VERSION ""

NS_ :

BS_:

BU_: CLOCK HUD H_U DATC CCP KMA_TMU CUBIS TMU IPM RSE_R RRC CGW RSE_L AMP EDT SWRC IBOX CLU FHCU ASD MON AVM KBD

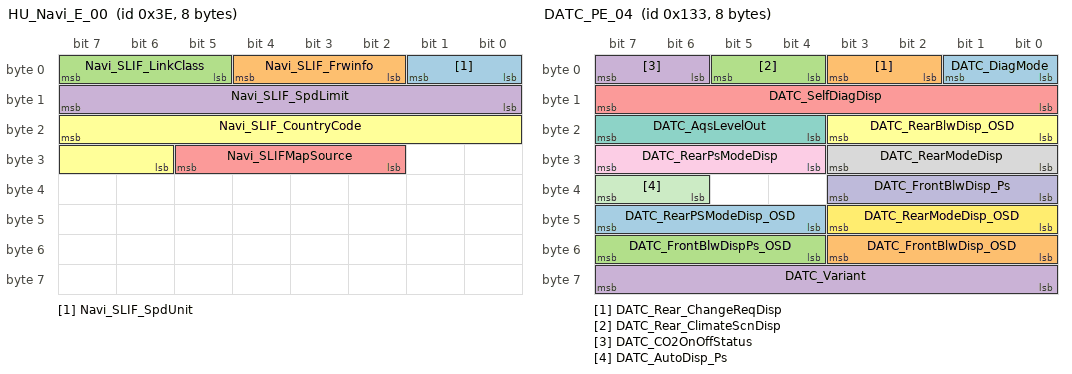
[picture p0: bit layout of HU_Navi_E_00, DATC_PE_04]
BO_ 62 HU_Navi_E_00: 8 H_U
 SG_ Navi_SLIF_SpdUnit : 1|2@0+ (1,0) [0|0] ""  CGW,CLU,HUD
 SG_ Navi_SLIF_Frwinfo : 4|3@0+ (1,0) [0|0] ""  CGW,CLU,HUD
 SG_ Navi_SLIF_LinkClass : 7|3@0+ (1,0) [0|0] ""  CGW,CLU,HUD
 SG_ Navi_SLIF_SpdLimit : 15|8@0+ (1,0) [1|254] ""  CGW,CLU,HUD
 SG_ Navi_SLIFMapSource : 29|4@0+ (1,0) [0|8] ""  CGW,CLU,HUD
 SG_ Navi_SLIF_CountryCode : 23|10@0+ (1,0) [0|0] ""  CGW,CLU,HUD

BO_ 52 HU_DATC_E_02: 8 H_U
 SG_ HU_DATC_DrTempUpDn : 1|2@0+ (1,0) [0|0] ""  CGW,CLU,DATC,IPM
 SG_ HU_DATC_PsTempUpDn : 3|2@0+ (1,0) [0|0] ""  CGW,CLU,DATC,IPM
 SG_ HU_DATC_RlTempUpDn : 5|2@0+ (1,0) [0|0] ""  CGW,CLU,DATC,IPM
 SG_ HU_DATC_RrTempUpDn : 7|2@0+ (1,0) [0|0] ""  CGW,CLU,DATC,IPM
 SG_ HU_DATC_MainBlower : 11|4@0+ (1,0) [0|0] ""  CGW,CLU,DATC,IPM
 SG_ HU_DATC_SubBlower : 15|4@0+ (1,0) [0|0] ""  CGW,CLU,DATC,IPM
 SG_ HU_DATC_RearBlower : 19|4@0+ (1,0) [0|0] ""  CGW,CLU,DATC,IPM
 SG_ HU_DATCRearPsModeSet : 23|4@0+ (1,0) [0|0] ""  CGW,CLU
 SG_ HU_DATC_FrontModeSet : 27|4@0+ (1,0) [0|0] ""  CGW,CLU,DATC,IPM
 SG_ HU_DATC_RearModeSet : 31|4@0+ (1,0) [0|0] ""  CGW,CLU,DATC,IPM
 SG_ HU_DATC_AutoSet : 33|2@0+ (1,0) [0|0] ""  CGW,CLU,DATC,IPM
 SG_ HU_DATC_OffReq : 35|2@0+ (1,0) [0|0] ""  CGW,CLU,DATC,IPM
 SG_ HU_DATC_IntakeSet : 37|2@0+ (1,0) [0|0] ""  CGW,CLU,DATC,IPM
 SG_ HU_DATC_RearOnOffSet : 39|2@0+ (1,0) [0|0] ""  CGW,CLU,DATC,IPM
 SG_ HU_DATC_AcSet : 41|2@0+ (1,0) [0|0] ""  CGW,CLU,DATC,IPM
 SG_ HU_DATC_AqsSet : 43|2@0+ (1,0) [0|0] ""  CGW,CLU,DATC,IPM
 SG_ HU_DATC_FrontDefog : 45|2@0+ (1,0) [0|0] ""  CGW,CLU,DATC,IPM
 SG_ HU_DATC_RearDefog : 47|2@0+ (1,0) [0|0] ""  CGW,CLU,DATC,IPM
 SG_ HU_DATC_ZoneControl : 49|2@0+ (1,0) [0|0] ""  CGW,CLU,DATC,IPM
 SG_ HU_DATC_CO2Set : 51|2@0+ (1,0) [0|0] ""  CGW,CLU,DATC,IPM
 SG_ DATC_SmartVentOnOffSet : 53|2@0+ (1,0) [0|0] ""  CGW,CLU,DATC,IPM
 SG_ DATC_ADSOnOffSet : 55|2@0+ (1,0) [0|0] ""  CGW,CLU
 SG_ HU_DATC_RearAutoDisp : 57|2@0+ (1,0) [0|0] ""  CGW,CLU
 SG_ HU_DATC_RearOffDisp : 59|2@0+ (1,0) [0|0] ""  CGW,CLU

BO_ 308 DATC_PE_05: 8 CLU
 SG_ DATC_PwrInfo : 3|4@0+ (1,0) [0|0] ""  AMP,AVM,CUBIS,H_U,MON
 SG_ DATC_AltL : 5|2@0+ (1,0) [0|0] ""  H_U,MON
 SG_ DATC_CarInfo : 7|2@0+ (1,0) [0|0] ""  H_U
 SG_ DATC_ParkingBrake : 9|2@0+ (1,0) [0|0] ""  H_U
 SG_ DATC_LowFuelWarn : 11|2@0+ (1,0) [0|0] ""  H_U
 SG_ DATC_Rear_Off_Disp : 13|2@0+ (1,0) [0|0] ""  H_U,MON
 SG_ DATC_Rear_AutoDisp : 15|2@0+ (1,0) [0|0] ""  H_U,MON
 SG_ DATC_Rear_BlowerDisp : 19|4@0+ (1,0) [0|0] ""  H_U,MON
 SG_ DATC_DrSeatWarmerDisp : 22|3@0+ (1,0) [0|0] ""  H_U,MON
 SG_ DATC_SyncDisp : 27|4@0+ (1,0) [0|0] ""  H_U,MON
 SG_ DATC_RearDispCtrl : 31|4@0+ (1,0) [0|0] ""  H_U,MON
 SG_ DATC_RearDrModeDisp : 35|4@0+ (1,0) [0|0] ""  H_U
 SG_ DATC_PsSeatWarmerDisp : 38|3@0+ (1,0) [0|0] ""  H_U,MON
 SG_ DATC_DrVentSeatDisp : 42|3@0+ (1,0) [0|0] ""  H_U,MON
 SG_ DATC_PSVentSeatDisp : 46|3@0+ (1,0) [0|0] ""  H_U,MON
 SG_ DATC_RrDefLed : 49|2@0+ (1,0) [0|0] ""  H_U,MON
 SG_ DATC_SmartVentOnOffStatus : 51|2@0+ (1,0) [0|0] ""  H_U
 SG_ DATC_ADSOnOffStatus : 53|2@0+ (1,0) [0|0] ""  H_U
 SG_ DATC_AcDisp_OSD : 55|2@0+ (1,0) [0|0] ""  H_U
 SG_ DATC_PsModeDisp_OSD : 59|4@0+ (1,0) [0|0] ""  H_U
 SG_ DATC_ModeDisp_OSD : 63|4@0+ (1,0) [0|0] ""  H_U

BO_ 307 DATC_PE_04: 8 CLU
 SG_ DATC_DiagMode : 1|2@0+ (1,0) [0|0] ""  H_U,IBOX,MON
 SG_ DATC_Rear_ChangeReqDisp : 3|2@0+ (1,0) [0|0] ""  H_U,IBOX,MON
 SG_ DATC_Rear_ClimateScnDisp : 5|2@0+ (1,0) [0|0] ""  H_U,IBOX,MON
 SG_ DATC_CO2OnOffStatus : 7|2@0+ (1,0) [0|0] ""  H_U
 SG_ DATC_SelfDiagDisp : 15|8@0+ (1,0) [0|0] ""  H_U,IBOX,MON
 SG_ DATC_RearBlwDisp_OSD : 19|4@0+ (1,0) [0|0] ""  H_U
 SG_ DATC_AqsLevelOut : 23|4@0+ (1,0) [0|0] ""  H_U,IBOX,MON
 SG_ DATC_RearModeDisp : 27|4@0+ (1,0) [0|0] ""  H_U
 SG_ DATC_RearPsModeDisp : 31|4@0+ (1,0) [0|0] ""  H_U
 SG_ DATC_FrontBlwDisp_Ps : 35|4@0+ (1,0) [0|0] ""  H_U
 SG_ DATC_AutoDisp_Ps : 39|2@0+ (1,0) [0|0] ""  H_U
 SG_ DATC_RearModeDisp_OSD : 43|4@0+ (1,0) [0|0] ""  H_U
 SG_ DATC_RearPSModeDisp_OSD : 47|4@0+ (1,0) [0|0] ""  H_U
 SG_ DATC_FrontBlwDisp_OSD : 51|4@0+ (1,0) [0|0] ""  H_U
 SG_ DATC_FrontBlwDispPs_OSD : 55|4@0+ (1,0) [0|0] ""  H_U
 SG_ DATC_Variant : 63|8@0+ (1,0) [0|0] ""  H_U,IBOX,MON

BO_ 306 DATC_PE_03: 8 CLU
 SG_ DATC_ModeDisp : 3|4@0+ (1,0) [0|0] ""  H_U,IBOX
 SG_ DATC_TempUnit : 5|2@0+ (1,0) [0|0] ""  H_U,IBOX
 SG_ DATC_AutoDisp : 9|2@0+ (1,0) [0|0] ""  H_U,IBOX
 SG_ DATC_IntakeDisp : 11|2@0+ (1,0) [0|0] ""  H_U,IBOX
 SG_ DATC_ChangeReqDisp : 13|2@0+ (1,0) [0|0] ""  H_U,IBOX
 SG_ DATC_AcDisp : 17|2@0+ (1,0) [0|0] ""  H_U,IBOX
 SG_ DATC_AqsDisp : 19|2@0+ (1,0) [0|0] ""  H_U,IBOX
 SG_ DATC_ClimateScnDisp : 21|2@0+ (1,0) [0|0] ""  H_U,IBOX
 SG_ DATC_DualDisp : 25|2@0+ (1,0) [0|0] ""  H_U,IBOX
 SG_ DATC_OffDisp : 27|2@0+ (1,0) [0|0] ""  H_U,IBOX
 SG_ DATC_OpSts : 30|3@0+ (1,0) [0|0] ""  H_U,IBOX
 SG_ DATC_RearManual : 33|2@0+ (1,0) [0|0] ""  H_U,MON
 SG_ DATC_FrDefLed : 37|2@0+ (1,0) [0|0] ""  H_U
 SG_ DATC_SmartVentDisp : 39|2@0+ (1,0) [0|0] ""  H_U
 SG_ DATC_AutoDefogBlink : 41|2@0+ (1,0) [0|0] ""  H_U,IBOX
 SG_ DATC_ADSDisp : 43|2@0+ (1,0) [0|0] ""  H_U
 SG_ DATC_IonClean : 45|2@0+ (1,0) [0|0] ""  H_U,IBOX
 SG_ DATC_CO2Warning : 47|2@0+ (1,0) [0|0] ""  H_U,IBOX
 SG_ DATC_SubBlowerDisp : 51|4@0+ (1,0) [0|0] ""  H_U,MON
 SG_ DATC_BeepReq : 55|4@0+ (1,0) [0|0] ""  H_U,KBD,MON
 SG_ DATC_MainBlowerDisp : 59|4@0+ (1,0) [0|0] ""  H_U,IBOX
 SG_ DATC_PsModeDisp : 63|4@0+ (1,0) [0|0] ""  H_U,IBOX

BO_ 1329 DATC_P_02: 8 CLU
 SG_ DATC_AmbientTemp_C : 7|8@0+ (1,0) [0|0] ""  H_U,MON
 SG_ DATC_AmbientTemp_F : 23|8@0+ (1,0) [0|0] ""  H_U,MON

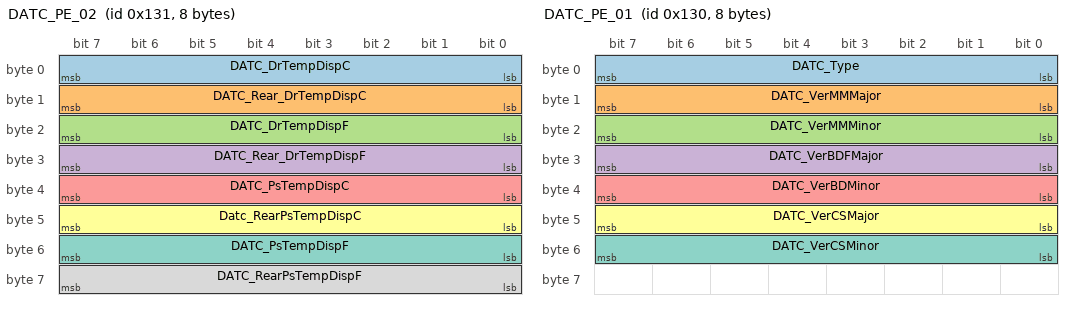
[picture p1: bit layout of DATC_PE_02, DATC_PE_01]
BO_ 305 DATC_PE_02: 8 CLU
 SG_ DATC_DrTempDispC : 7|8@0+ (0.5,14) [15|32] "C"  H_U,IBOX,MON
 SG_ DATC_Rear_DrTempDispC : 15|8@0+ (0.5,14) [15|32] "C"  H_U,IBOX,MON
 SG_ DATC_DrTempDispF : 23|8@0+ (1,56) [58|90] "F"  H_U,IBOX,MON
 SG_ DATC_Rear_DrTempDispF : 31|8@0+ (1,56) [58|90] "F"  H_U,IBOX,MON
 SG_ DATC_PsTempDispC : 39|8@0+ (0.5,14) [15|32] "C"  H_U,IBOX,MON
 SG_ Datc_RearPsTempDispC : 47|8@0+ (0.5,14) [15|32] "C"  H_U,IBOX,MON
 SG_ DATC_PsTempDispF : 55|8@0+ (1,56) [58|90] "F"  H_U,IBOX,MON
 SG_ DATC_RearPsTempDispF : 63|8@0+ (1,56) [58|90] "F"  H_U,IBOX,MON

BO_ 304 DATC_PE_01: 8 CLU
 SG_ DATC_Type : 7|8@0+ (1,0) [0|0] ""  H_U,MON
 SG_ DATC_VerMMMajor : 15|8@0+ (1,0) [0|0] ""  H_U,MON
 SG_ DATC_VerMMMinor : 23|8@0+ (1,0) [0|0] ""  H_U,MON
 SG_ DATC_VerBDFMajor : 31|8@0+ (1,0) [0|0] ""  H_U,MON
 SG_ DATC_VerBDMinor : 39|8@0+ (1,0) [0|0] ""  H_U,MON
 SG_ DATC_VerCSMajor : 47|8@0+ (1,0) [0|0] ""  H_U,MON
 SG_ DATC_VerCSMinor : 55|8@0+ (1,0) [0|0] ""  H_U,MON

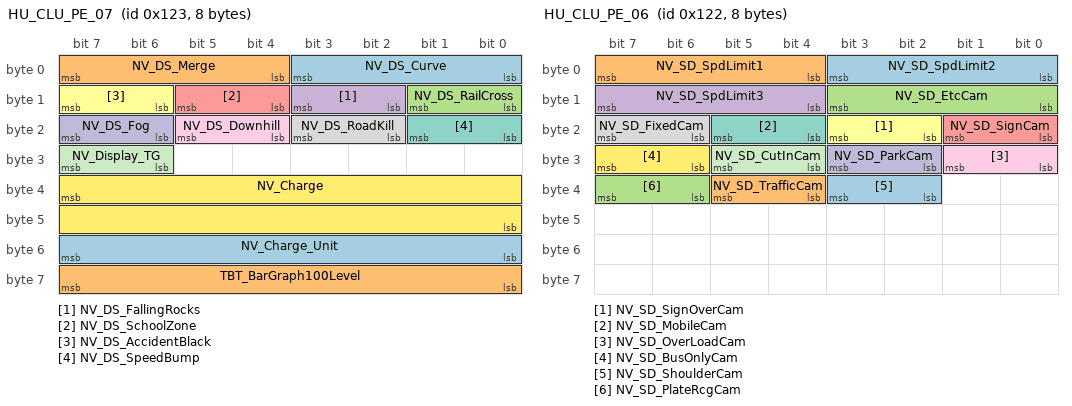
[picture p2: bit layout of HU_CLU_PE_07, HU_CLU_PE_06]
BO_ 291 HU_CLU_PE_07: 8 H_U
 SG_ NV_DS_Curve : 3|4@0+ (1,0) [0|0] ""  CLU
 SG_ NV_DS_Merge : 7|4@0+ (1,0) [0|0] ""  CLU
 SG_ NV_DS_RailCross : 9|2@0+ (1,0) [0|0] ""  CLU
 SG_ NV_DS_FallingRocks : 11|2@0+ (1,0) [0|0] ""  CLU
 SG_ NV_DS_SchoolZone : 13|2@0+ (1,0) [0|0] ""  CLU
 SG_ NV_DS_AccidentBlack : 15|2@0+ (1,0) [0|0] ""  CLU
 SG_ NV_DS_SpeedBump : 17|2@0+ (1,0) [0|0] ""  CLU
 SG_ NV_DS_RoadKill : 19|2@0+ (1,0) [0|0] ""  CLU
 SG_ NV_DS_Downhill : 21|2@0+ (1,0) [0|0] ""  CLU
 SG_ NV_DS_Fog : 23|2@0+ (1,0) [0|0] ""  CLU
 SG_ NV_Display_TG : 31|2@0+ (1,0) [0|0] ""  CLU,HUD
 SG_ NV_Charge : 39|16@0+ (1,0) [0|0] ""  CLU,HUD
 SG_ NV_Charge_Unit : 55|8@0+ (1,0) [0|0] ""  CLU,HUD
 SG_ TBT_BarGraph100Level : 63|8@0+ (1,0) [0|100] "%"  CLU,HUD

BO_ 290 HU_CLU_PE_06: 8 H_U
 SG_ NV_SD_SpdLimit2 : 3|4@0+ (10,0) [0|0] "km/h"  CLU
 SG_ NV_SD_SpdLimit1 : 7|4@0+ (10,0) [0|0] "km/h"  CLU
 SG_ NV_SD_EtcCam : 11|4@0+ (1,0) [0|0] ""  CLU
 SG_ NV_SD_SpdLimit3 : 15|4@0+ (10,0) [0|0] "km/h"  CLU
 SG_ NV_SD_SignCam : 17|2@0+ (1,0) [0|0] ""  CLU
 SG_ NV_SD_SignOverCam : 19|2@0+ (1,0) [0|0] ""  CLU
 SG_ NV_SD_MobileCam : 21|2@0+ (1,0) [0|0] ""  CLU
 SG_ NV_SD_FixedCam : 23|2@0+ (1,0) [0|0] ""  CLU
 SG_ NV_SD_OverLoadCam : 25|2@0+ (1,0) [0|0] ""  CLU
 SG_ NV_SD_ParkCam : 27|2@0+ (1,0) [0|0] ""  CLU
 SG_ NV_SD_CutInCam : 29|2@0+ (1,0) [0|0] ""  CLU
 SG_ NV_SD_BusOnlyCam : 31|2@0+ (1,0) [0|0] ""  CLU
 SG_ NV_SD_ShoulderCam : 35|2@0+ (1,0) [0|0] ""  CLU
 SG_ NV_SD_TrafficCam : 37|2@0+ (1,0) [0|0] ""  CLU
 SG_ NV_SD_PlateRcgCam : 39|2@0+ (1,0) [0|0] ""  CLU

BO_ 286 HU_CLU_PE_10: 8 H_U
 SG_ Navi_TBTInfo : 63|8@0+ (1,0) [0|0] ""  CGW,CLU

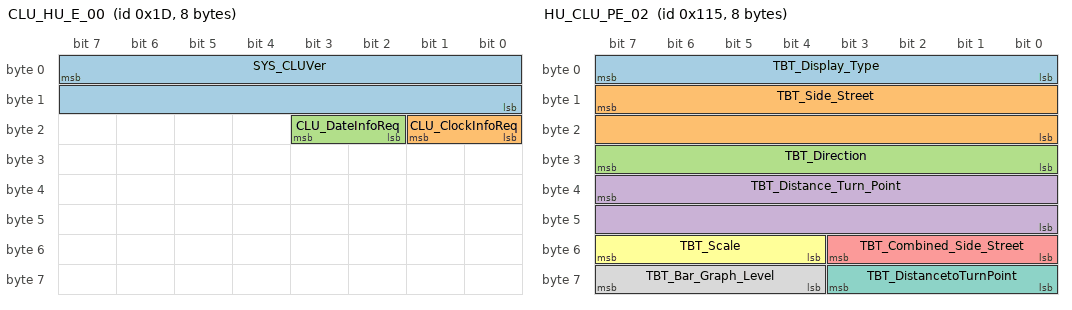
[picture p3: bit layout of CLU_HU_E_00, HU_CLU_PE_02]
BO_ 29 CLU_HU_E_00: 8 CLU
 SG_ SYS_CLUVer : 7|16@0+ (1,0) [0|0] ""  CUBIS,H_U
 SG_ CLU_ClockInfoReq : 17|2@0+ (1,0) [0|0] ""  H_U
 SG_ CLU_DateInfoReq : 19|2@0+ (1,0) [0|0] ""  H_U

BO_ 27 AMP_HU_E_00: 8 AMP
 SG_ SYS_AMPVer : 7|16@0+ (1,0) [0|0] ""  H_U

BO_ 23 HU_IPM_E_00: 8 H_U
 SG_ C_ADrLNValueSet : 2|3@0+ (1,0) [0|0] ""  DATC,IPM
 SG_ C_ADrUNValueSet : 5|3@0+ (1,0) [0|0] ""  DATC,IPM
 SG_ SYS_Ver_Req : 7|2@0+ (1,0) [0|0] ""  AMP,AVM,CLU,CUBIS,DATC,IPM
 SG_ C_IMSRValueReq : 9|2@0+ (1,0) [0|0] ""  DATC,IPM
 SG_ C_PSMNValueSet : 11|2@0+ (1,0) [0|0] ""  DATC,IPM
 SG_ C_SCMNValueSet : 13|2@0+ (1,0) [0|0] ""  DATC,IPM
 SG_ C_ADrLURValueReq : 15|2@0+ (1,0) [0|0] ""  DATC,IPM
 SG_ C_ABuzzerNValueSet : 17|2@0+ (1,0) [0|0] ""  DATC,IPM
 SG_ C_AlarmRValueReq : 19|2@0+ (1,0) [0|0] ""  DATC,IPM
 SG_ C_ArmWKeyNValueSet : 21|2@0+ (1,0) [0|0] ""  DATC,IPM
 SG_ C_TwUnRValueReq : 23|2@0+ (1,0) [0|0] ""  DATC,IPM
 SG_ C_TwUnNValueSet : 25|2@0+ (1,0) [0|0] ""  DATC,IPM
 SG_ C_AutoMRFoldRValueReq : 27|2@0+ (1,0) [0|0] ""  DATC,IPM
 SG_ C_AutoMRFoldNValueSet : 29|2@0+ (1,0) [0|0] ""  DATC,IPM
 SG_ C_ADrLRValueReq : 31|2@0+ (1,0) [0|0] ""  DATC,IPM
 SG_ C_ArmWKeyRValueReq : 33|2@0+ (1,0) [0|0] ""  DATC,IPM
 SG_ C_ABuzzerRValueReq : 35|2@0+ (1,0) [0|0] ""  DATC,IPM
 SG_ C_ADrURValueReq : 37|2@0+ (1,0) [0|0] ""  DATC,IPM
 SG_ C_PSMRValueReq : 39|2@0+ (1,0) [0|0] ""  DATC,IPM
 SG_ C_SCMRValueReq : 47|2@0+ (1,0) [0|0] ""  DATC,IPM

BO_ 277 HU_CLU_PE_02: 8 H_U
 SG_ TBT_Display_Type : 7|8@0+ (1,0) [0|0] ""  CLU,HUD
 SG_ TBT_Side_Street : 15|16@0+ (1,0) [0|0] ""  CLU,HUD
 SG_ TBT_Direction : 31|8@0+ (1,0) [0|0] ""  CLU,HUD
 SG_ TBT_Distance_Turn_Point : 39|16@0+ (1,0) [0|0] "m"  CLU,HUD
 SG_ TBT_Combined_Side_Street : 51|4@0+ (1,0) [0|0] ""  CLU,HUD
 SG_ TBT_Scale : 55|4@0+ (1,0) [0|0] ""  CLU,HUD
 SG_ TBT_DistancetoTurnPoint : 59|4@0+ (1,0) [0|0] "times"  CLU,HUD
 SG_ TBT_Bar_Graph_Level : 63|4@0+ (10,0) [0|100] ""  CLU,HUD

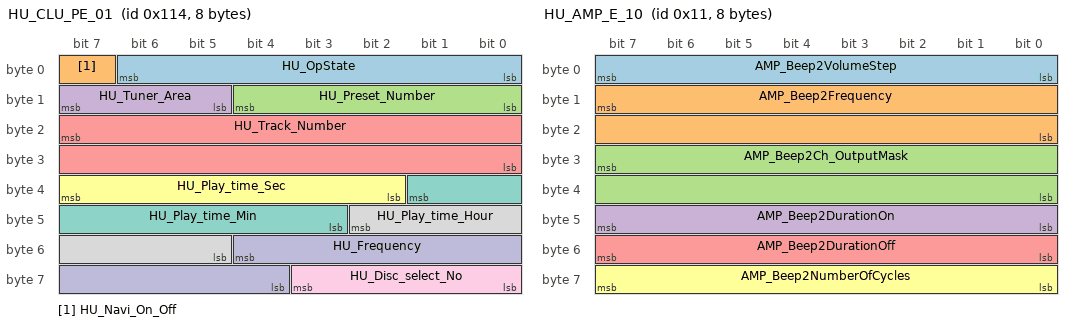
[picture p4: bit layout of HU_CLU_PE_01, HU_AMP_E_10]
BO_ 276 HU_CLU_PE_01: 8 H_U
 SG_ HU_OpState : 6|7@0+ (1,0) [0|0] ""  AMP,CLU
 SG_ HU_Navi_On_Off : 7|1@0+ (1,0) [0|0] ""  CLU,HUD
 SG_ HU_Preset_Number : 12|5@0+ (1,1) [1|30] ""  AMP,CLU
 SG_ HU_Tuner_Area : 15|3@0+ (1,0) [0|0] ""  AMP,CLU
 SG_ HU_Track_Number : 23|16@0+ (1,0) [0|0] ""  CLU
 SG_ HU_Play_time_Sec : 39|6@0+ (1,0) [0|0] ""  CLU
 SG_ HU_Play_time_Min : 33|7@0+ (1,0) [0|0] ""  CLU
 SG_ HU_Play_time_Hour : 42|6@0+ (1,0) [0|0] ""  CLU
 SG_ HU_Disc_select_No : 59|4@0+ (1,0) [0|0] ""  CLU
 SG_ HU_Frequency : 52|9@0+ (1,0) [0|0] ""  AMP,CLU

BO_ 17 HU_AMP_E_10: 8 H_U
 SG_ AMP_Beep2VolumeStep : 7|8@0+ (1,0) [0|0] ""  AMP
 SG_ AMP_Beep2Frequency : 15|16@0+ (1,0) [0|0] ""  AMP
 SG_ AMP_Beep2Ch_OutputMask : 31|16@0+ (1,0) [0|0] ""  AMP
 SG_ AMP_Beep2DurationOn : 47|8@0+ (1,0) [0|0] ""  AMP
 SG_ AMP_Beep2DurationOff : 55|8@0+ (1,0) [0|0] ""  AMP
 SG_ AMP_Beep2NumberOfCycles : 63|8@0+ (1,0) [0|0] ""  AMP

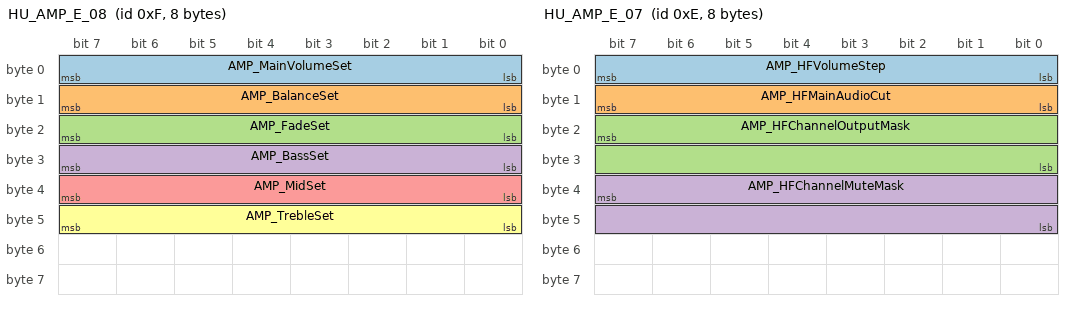
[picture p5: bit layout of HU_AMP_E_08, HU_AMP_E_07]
BO_ 15 HU_AMP_E_08: 8 H_U
 SG_ AMP_MainVolumeSet : 7|8@0+ (1,0) [0|0] ""  AMP
 SG_ AMP_BalanceSet : 15|8@0+ (1,0) [0|0] ""  AMP
 SG_ AMP_FadeSet : 23|8@0+ (1,0) [0|0] ""  AMP
 SG_ AMP_BassSet : 31|8@0+ (1,0) [0|0] ""  AMP
 SG_ AMP_MidSet : 39|8@0+ (1,0) [0|0] ""  AMP
 SG_ AMP_TrebleSet : 47|8@0+ (1,0) [0|0] ""  AMP

BO_ 14 HU_AMP_E_07: 8 H_U
 SG_ AMP_HFVolumeStep : 7|8@0+ (1,0) [0|0] ""  AMP
 SG_ AMP_HFMainAudioCut : 15|8@0+ (1,0) [0|0] ""  AMP
 SG_ AMP_HFChannelOutputMask : 23|16@0+ (1,0) [0|0] ""  AMP
 SG_ AMP_HFChannelMuteMask : 39|16@0+ (1,0) [0|0] ""  AMP

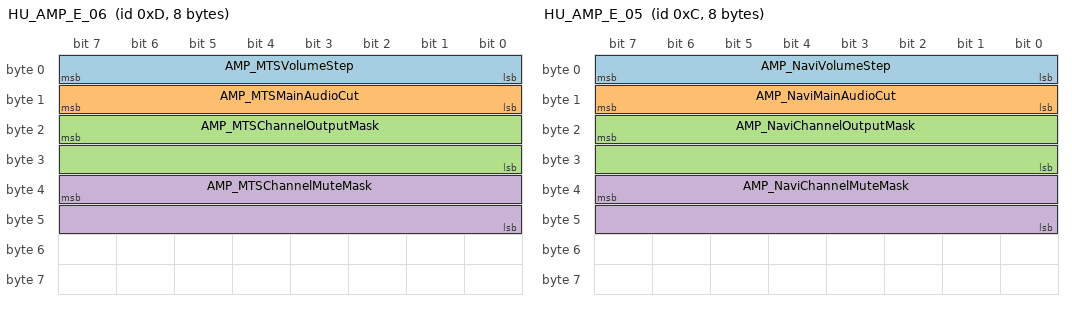
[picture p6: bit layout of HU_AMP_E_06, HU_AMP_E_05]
BO_ 13 HU_AMP_E_06: 8 H_U
 SG_ AMP_MTSVolumeStep : 7|8@0+ (1,0) [0|0] ""  AMP
 SG_ AMP_MTSMainAudioCut : 15|8@0+ (1,0) [0|0] ""  AMP
 SG_ AMP_MTSChannelOutputMask : 23|16@0+ (1,0) [0|0] ""  AMP
 SG_ AMP_MTSChannelMuteMask : 39|16@0+ (1,0) [0|0] ""  AMP

BO_ 12 HU_AMP_E_05: 8 H_U
 SG_ AMP_NaviVolumeStep : 7|8@0+ (1,0) [0|0] ""  AMP
 SG_ AMP_NaviMainAudioCut : 15|8@0+ (1,0) [0|0] ""  AMP
 SG_ AMP_NaviChannelOutputMask : 23|16@0+ (1,0) [0|0] ""  AMP
 SG_ AMP_NaviChannelMuteMask : 39|16@0+ (1,0) [0|0] ""  AMP

BO_ 11 HU_AMP_E_04: 8 H_U
 SG_ AMP_Drive : 1|2@0+ (1,0) [0|0] ""  AMP
 SG_ AMP_ConvertibleTop : 5|2@0+ (1,0) [0|0] ""  AMP

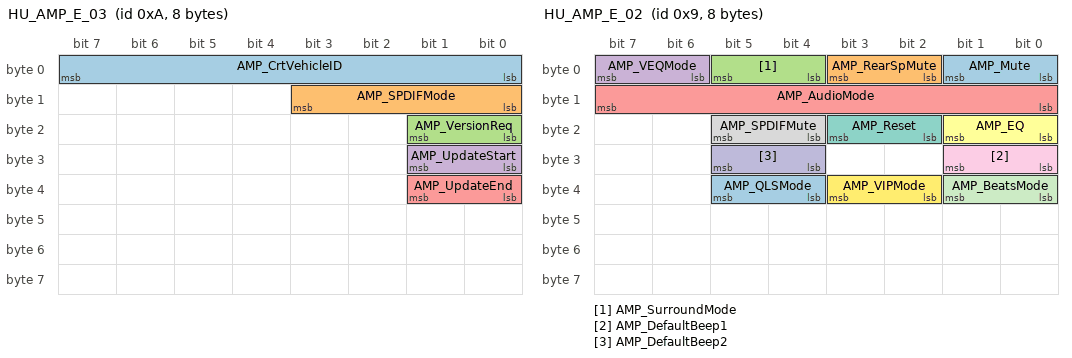
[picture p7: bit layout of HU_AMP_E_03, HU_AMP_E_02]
BO_ 10 HU_AMP_E_03: 8 H_U
 SG_ AMP_CrtVehicleID : 7|8@0+ (1,0) [0|0] ""  AMP
 SG_ AMP_SPDIFMode : 11|4@0+ (1,0) [0|0] ""  AMP
 SG_ AMP_VersionReq : 17|2@0+ (1,0) [0|0] ""  AMP
 SG_ AMP_UpdateStart : 25|2@0+ (1,0) [0|0] ""  AMP
 SG_ AMP_UpdateEnd : 33|2@0+ (1,0) [0|0] ""  AMP

BO_ 9 HU_AMP_E_02: 8 H_U
 SG_ AMP_Mute : 1|2@0+ (1,0) [0|0] ""  AMP
 SG_ AMP_RearSpMute : 3|2@0+ (1,0) [0|0] ""  AMP
 SG_ AMP_SurroundMode : 5|2@0+ (1,0) [0|0] ""  AMP
 SG_ AMP_VEQMode : 7|2@0+ (1,0) [0|0] ""  AMP
 SG_ AMP_AudioMode : 15|8@0+ (1,0) [0|0] ""  AMP
 SG_ AMP_EQ : 17|2@0+ (1,0) [0|0] ""  AMP
 SG_ AMP_Reset : 19|2@0+ (1,0) [0|0] ""  AMP
 SG_ AMP_SPDIFMute : 21|2@0+ (1,0) [0|0] ""  AMP
 SG_ AMP_DefaultBeep1 : 25|2@0+ (1,0) [0|0] ""  AMP
 SG_ AMP_DefaultBeep2 : 29|2@0+ (1,0) [0|0] ""  AMP
 SG_ AMP_BeatsMode : 33|2@0+ (1,0) [0|0] ""  AMP
 SG_ AMP_VIPMode : 35|2@0+ (1,0) [0|0] ""  AMP
 SG_ AMP_QLSMode : 37|2@0+ (1,0) [0|0] ""  AMP

BO_ 1288 HU_CLU_P_02: 8 H_U
 SG_ NV_TIME_TYPE : 3|4@0+ (1,0) [0|0] ""  CLU
 SG_ NV_Hour : 15|8@0+ (1,0) [0|0] ""  CLU
 SG_ NV_Min : 23|8@0+ (1,0) [0|0] ""  CLU

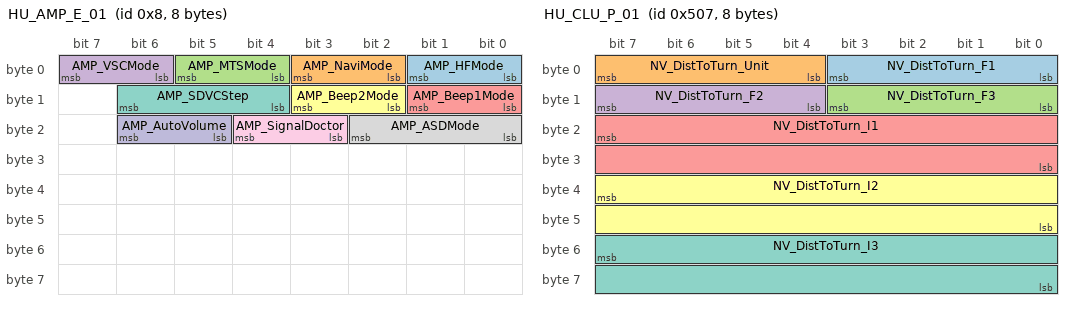
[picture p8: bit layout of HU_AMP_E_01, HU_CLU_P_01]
BO_ 8 HU_AMP_E_01: 8 H_U
 SG_ AMP_HFMode : 1|2@0+ (1,0) [0|0] ""  AMP
 SG_ AMP_NaviMode : 3|2@0+ (1,0) [0|0] ""  AMP
 SG_ AMP_MTSMode : 5|2@0+ (1,0) [0|0] ""  AMP
 SG_ AMP_VSCMode : 7|2@0+ (1,0) [0|0] ""  AMP
 SG_ AMP_Beep1Mode : 9|2@0+ (1,0) [0|0] ""  AMP
 SG_ AMP_Beep2Mode : 11|2@0+ (1,0) [0|0] ""  AMP
 SG_ AMP_SDVCStep : 14|3@0+ (1,0) [0|0] ""  AMP
 SG_ AMP_ASDMode : 18|3@0+ (1,0) [0|0] ""  AMP
 SG_ AMP_SignalDoctor : 20|2@0+ (1,0) [0|0] ""  AMP
 SG_ AMP_AutoVolume : 22|2@0+ (1,0) [0|0] ""  AMP

BO_ 1287 HU_CLU_P_01: 8 H_U
 SG_ NV_DistToTurn_F1 : 3|4@0+ (1,0) [0|0] ""  CLU
 SG_ NV_DistToTurn_Unit : 7|4@0+ (1,0) [0|0] ""  CLU
 SG_ NV_DistToTurn_F3 : 11|4@0+ (1,0) [0|0] ""  CLU
 SG_ NV_DistToTurn_F2 : 15|4@0+ (1,0) [0|0] ""  CLU
 SG_ NV_DistToTurn_I1 : 23|16@0+ (1,0) [0|0] ""  CLU
 SG_ NV_DistToTurn_I2 : 39|16@0+ (1,0) [0|0] ""  CLU
 SG_ NV_DistToTurn_I3 : 55|16@0+ (1,0) [0|0] ""  CLU

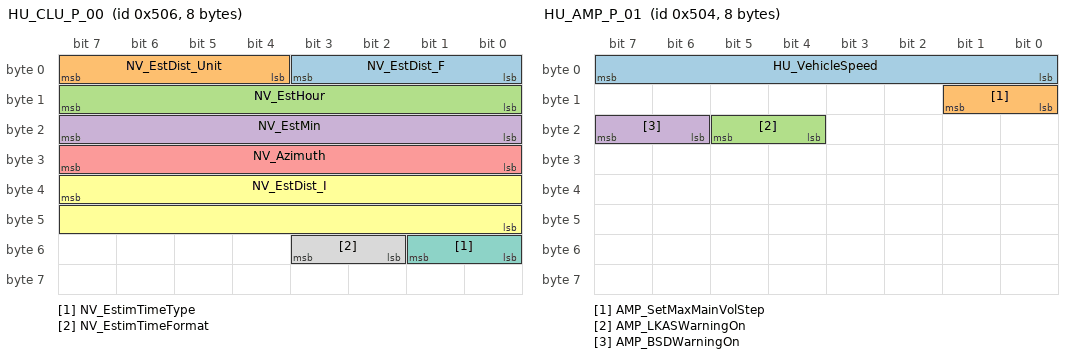
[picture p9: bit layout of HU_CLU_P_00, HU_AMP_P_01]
BO_ 1286 HU_CLU_P_00: 8 H_U
 SG_ NV_EstDist_F : 3|4@0+ (1,0) [0|0] ""  CLU,HUD
 SG_ NV_EstDist_Unit : 7|4@0+ (1,0) [0|0] ""  CLU,HUD
 SG_ NV_EstHour : 15|8@0+ (1,0) [0|0] ""  CLU,HUD
 SG_ NV_EstMin : 23|8@0+ (1,0) [0|0] ""  CLU,HUD
 SG_ NV_Azimuth : 31|8@0+ (1,0) [0|0] ""  CLU,HUD
 SG_ NV_EstDist_I : 39|16@0+ (1,0) [0|0] ""  CLU,HUD
 SG_ NV_EstimTimeType : 49|2@0+ (1,0) [0|0] ""  CGW,CLU,HUD
 SG_ NV_EstimTimeFormat : 51|2@0+ (1,0) [0|0] ""  CGW,CLU,HUD

BO_ 1284 HU_AMP_P_01: 8 H_U
 SG_ HU_VehicleSpeed : 7|8@0+ (1,0) [0|0] ""  AMP
 SG_ AMP_SetMaxMainVolStep : 9|2@0+ (1,0) [0|0] ""  AMP
 SG_ AMP_LKASWarningOn : 21|2@0+ (1,0) [0|0] ""  AMP
 SG_ AMP_BSDWarningOn : 23|2@0+ (1,0) [0|0] ""  AMP

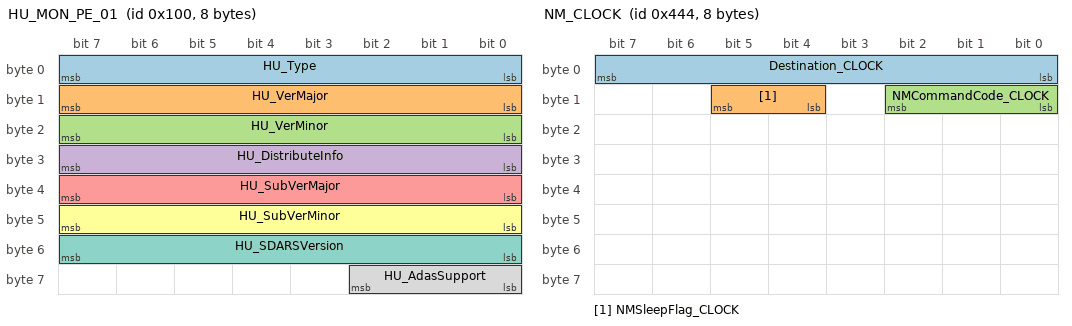
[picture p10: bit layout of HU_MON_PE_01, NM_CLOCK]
BO_ 256 HU_MON_PE_01: 8 H_U
 SG_ HU_Type : 7|8@0+ (1,0) [0|0] ""  AMP,CGW,CLU,HUD,KMA_TMU
 SG_ HU_VerMajor : 15|8@0+ (1,0) [0|0] ""  AMP,CLU,KMA_TMU,MON
 SG_ HU_VerMinor : 23|8@0+ (1,0) [0|0] ""  AMP,CLU,KMA_TMU,MON
 SG_ HU_DistributeInfo : 31|8@0+ (1,0) [0|0] ""  AMP,CGW,CLU,KMA_TMU,MON,RRC
 SG_ HU_SubVerMajor : 39|8@0+ (1,0) [0|0] ""  AMP,MON
 SG_ HU_SubVerMinor : 47|8@0+ (1,0) [0|0] ""  AMP,MON
 SG_ HU_SDARSVersion : 55|8@0+ (1,0) [0|0] ""  AMP,MON
 SG_ HU_AdasSupport : 58|3@0+ (1,0) [0|0] ""  CGW,CLU

BO_ 1092 NM_CLOCK: 8 CLOCK
 SG_ Destination_CLOCK : 7|8@0+ (1,0) [0|0] ""  HUD,H_U,DATC,CCP,KMA_TMU,CUBIS,TMU,IPM,RSE_R,RRC,CGW,RSE_L,AMP,EDT,SWRC,IBOX,CLU,FHCU,ASD,MON,AVM,KBD
 SG_ NMSleepFlag_CLOCK : 13|2@0+ (1,0) [0|0] ""  HUD,H_U,DATC,CCP,KMA_TMU,CUBIS,TMU,IPM,RSE_R,RRC,CGW,RSE_L,AMP,EDT,SWRC,IBOX,CLU,FHCU,ASD,MON,AVM,KBD
 SG_ NMCommandCode_CLOCK : 10|3@0+ (1,0) [0|0] ""  HUD,H_U,DATC,CCP,KMA_TMU,CUBIS,TMU,IPM,RSE_R,RRC,CGW,RSE_L,AMP,EDT,SWRC,IBOX,CLU,FHCU,ASD,MON,AVM,KBD

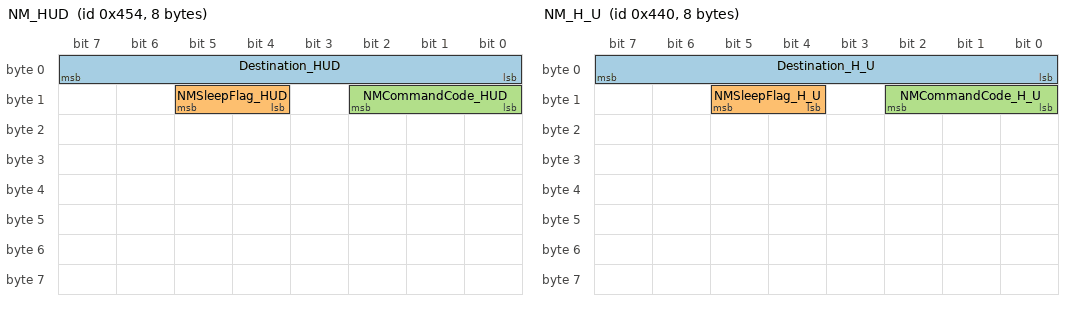
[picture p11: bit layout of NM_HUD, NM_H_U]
BO_ 1108 NM_HUD: 8 HUD
 SG_ Destination_HUD : 7|8@0+ (1,0) [0|0] ""  CLOCK,H_U,DATC,CCP,KMA_TMU,CUBIS,TMU,IPM,RSE_R,RRC,CGW,RSE_L,AMP,EDT,SWRC,IBOX,CLU,FHCU,ASD,MON,AVM,KBD
 SG_ NMSleepFlag_HUD : 13|2@0+ (1,0) [0|0] ""  CLOCK,H_U,DATC,CCP,KMA_TMU,CUBIS,TMU,IPM,RSE_R,RRC,CGW,RSE_L,AMP,EDT,SWRC,IBOX,CLU,FHCU,ASD,MON,AVM,KBD
 SG_ NMCommandCode_HUD : 10|3@0+ (1,0) [0|0] ""  CLOCK,H_U,DATC,CCP,KMA_TMU,CUBIS,TMU,IPM,RSE_R,RRC,CGW,RSE_L,AMP,EDT,SWRC,IBOX,CLU,FHCU,ASD,MON,AVM,KBD

BO_ 1088 NM_H_U: 8 H_U
 SG_ Destination_H_U : 7|8@0+ (1,0) [0|0] ""  CLOCK,HUD,DATC,CCP,KMA_TMU,CUBIS,TMU,IPM,RSE_R,RRC,CGW,RSE_L,AMP,EDT,SWRC,IBOX,CLU,FHCU,ASD,MON,AVM,KBD
 SG_ NMSleepFlag_H_U : 13|2@0+ (1,0) [0|0] ""  CLOCK,HUD,DATC,CCP,KMA_TMU,CUBIS,TMU,IPM,RSE_R,RRC,CGW,RSE_L,AMP,EDT,SWRC,IBOX,CLU,FHCU,ASD,MON,AVM,KBD
 SG_ NMCommandCode_H_U : 10|3@0+ (1,0) [0|0] ""  CLOCK,HUD,DATC,CCP,KMA_TMU,CUBIS,TMU,IPM,RSE_R,RRC,CGW,RSE_L,AMP,EDT,SWRC,IBOX,CLU,FHCU,ASD,MON,AVM,KBD

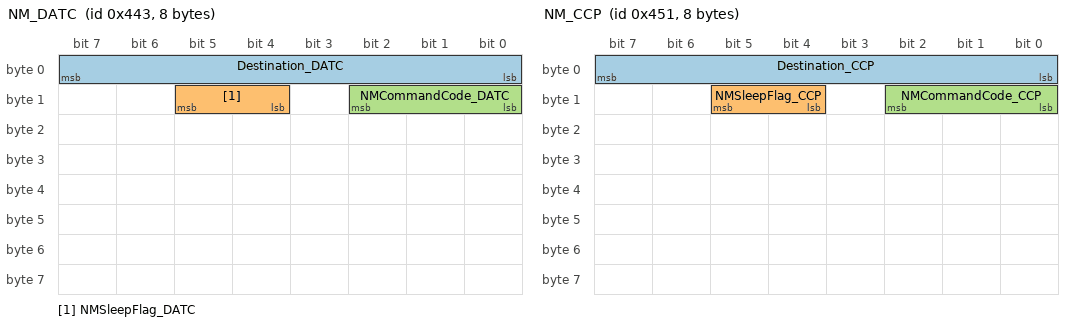
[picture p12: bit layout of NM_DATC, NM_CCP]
BO_ 1091 NM_DATC: 8 DATC
 SG_ Destination_DATC : 7|8@0+ (1,0) [0|0] ""  CLOCK,HUD,H_U,CCP,KMA_TMU,CUBIS,TMU,IPM,RSE_R,RRC,CGW,RSE_L,AMP,EDT,SWRC,IBOX,CLU,FHCU,ASD,MON,AVM,KBD
 SG_ NMSleepFlag_DATC : 13|2@0+ (1,0) [0|0] ""  CLOCK,HUD,H_U,CCP,KMA_TMU,CUBIS,TMU,IPM,RSE_R,RRC,CGW,RSE_L,AMP,EDT,SWRC,IBOX,CLU,FHCU,ASD,MON,AVM,KBD
 SG_ NMCommandCode_DATC : 10|3@0+ (1,0) [0|0] ""  CLOCK,HUD,H_U,CCP,KMA_TMU,CUBIS,TMU,IPM,RSE_R,RRC,CGW,RSE_L,AMP,EDT,SWRC,IBOX,CLU,FHCU,ASD,MON,AVM,KBD

BO_ 1105 NM_CCP: 8 CCP
 SG_ Destination_CCP : 7|8@0+ (1,0) [0|0] ""  CLOCK,HUD,H_U,DATC,KMA_TMU,CUBIS,TMU,IPM,RSE_R,RRC,CGW,RSE_L,AMP,EDT,SWRC,IBOX,CLU,FHCU,ASD,MON,AVM,KBD
 SG_ NMSleepFlag_CCP : 13|2@0+ (1,0) [0|0] ""  CLOCK,HUD,H_U,DATC,KMA_TMU,CUBIS,TMU,IPM,RSE_R,RRC,CGW,RSE_L,AMP,EDT,SWRC,IBOX,CLU,FHCU,ASD,MON,AVM,KBD
 SG_ NMCommandCode_CCP : 10|3@0+ (1,0) [0|0] ""  CLOCK,HUD,H_U,DATC,KMA_TMU,CUBIS,TMU,IPM,RSE_R,RRC,CGW,RSE_L,AMP,EDT,SWRC,IBOX,CLU,FHCU,ASD,MON,AVM,KBD

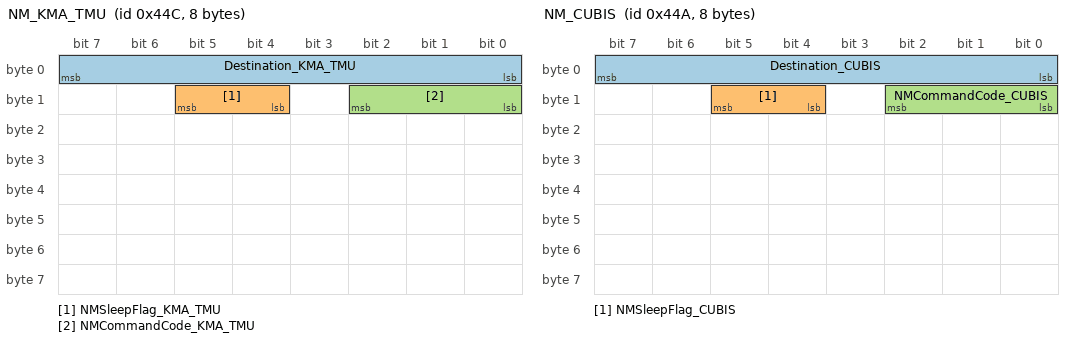
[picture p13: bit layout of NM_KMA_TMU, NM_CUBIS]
BO_ 1100 NM_KMA_TMU: 8 KMA_TMU
 SG_ Destination_KMA_TMU : 7|8@0+ (1,0) [0|0] ""  CLOCK,HUD,H_U,DATC,CCP,CUBIS,TMU,IPM,RSE_R,RRC,CGW,RSE_L,AMP,EDT,SWRC,IBOX,CLU,FHCU,ASD,MON,AVM,KBD
 SG_ NMSleepFlag_KMA_TMU : 13|2@0+ (1,0) [0|0] ""  CLOCK,HUD,H_U,DATC,CCP,CUBIS,TMU,IPM,RSE_R,RRC,CGW,RSE_L,AMP,EDT,SWRC,IBOX,CLU,FHCU,ASD,MON,AVM,KBD
 SG_ NMCommandCode_KMA_TMU : 10|3@0+ (1,0) [0|0] ""  CLOCK,HUD,H_U,DATC,CCP,CUBIS,TMU,IPM,RSE_R,RRC,CGW,RSE_L,AMP,EDT,SWRC,IBOX,CLU,FHCU,ASD,MON,AVM,KBD

BO_ 1098 NM_CUBIS: 8 CUBIS
 SG_ Destination_CUBIS : 7|8@0+ (1,0) [0|0] ""  CLOCK,HUD,H_U,DATC,CCP,KMA_TMU,TMU,IPM,RSE_R,RRC,CGW,RSE_L,AMP,EDT,SWRC,IBOX,CLU,FHCU,ASD,MON,AVM,KBD
 SG_ NMSleepFlag_CUBIS : 13|2@0+ (1,0) [0|0] ""  CLOCK,HUD,H_U,DATC,CCP,KMA_TMU,TMU,IPM,RSE_R,RRC,CGW,RSE_L,AMP,EDT,SWRC,IBOX,CLU,FHCU,ASD,MON,AVM,KBD
 SG_ NMCommandCode_CUBIS : 10|3@0+ (1,0) [0|0] ""  CLOCK,HUD,H_U,DATC,CCP,KMA_TMU,TMU,IPM,RSE_R,RRC,CGW,RSE_L,AMP,EDT,SWRC,IBOX,CLU,FHCU,ASD,MON,AVM,KBD

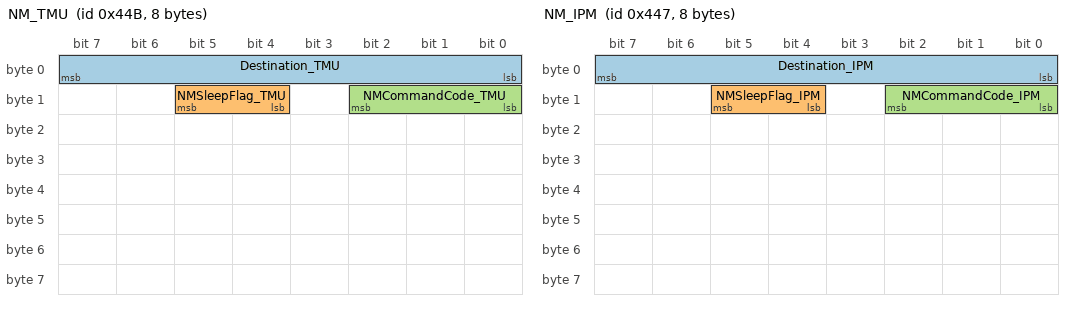
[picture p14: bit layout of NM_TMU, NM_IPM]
BO_ 1099 NM_TMU: 8 TMU
 SG_ Destination_TMU : 7|8@0+ (1,0) [0|0] ""  CLOCK,HUD,H_U,DATC,CCP,KMA_TMU,CUBIS,IPM,RSE_R,RRC,CGW,RSE_L,AMP,EDT,SWRC,IBOX,CLU,FHCU,ASD,MON,AVM,KBD
 SG_ NMSleepFlag_TMU : 13|2@0+ (1,0) [0|0] ""  CLOCK,HUD,H_U,DATC,CCP,KMA_TMU,CUBIS,IPM,RSE_R,RRC,CGW,RSE_L,AMP,EDT,SWRC,IBOX,CLU,FHCU,ASD,MON,AVM,KBD
 SG_ NMCommandCode_TMU : 10|3@0+ (1,0) [0|0] ""  CLOCK,HUD,H_U,DATC,CCP,KMA_TMU,CUBIS,IPM,RSE_R,RRC,CGW,RSE_L,AMP,EDT,SWRC,IBOX,CLU,FHCU,ASD,MON,AVM,KBD

BO_ 1095 NM_IPM: 8 IPM
 SG_ Destination_IPM : 7|8@0+ (1,0) [0|0] ""  CLOCK,HUD,H_U,DATC,CCP,KMA_TMU,CUBIS,TMU,RSE_R,RRC,CGW,RSE_L,AMP,EDT,SWRC,IBOX,CLU,FHCU,ASD,MON,AVM,KBD
 SG_ NMSleepFlag_IPM : 13|2@0+ (1,0) [0|0] ""  CLOCK,HUD,H_U,DATC,CCP,KMA_TMU,CUBIS,TMU,RSE_R,RRC,CGW,RSE_L,AMP,EDT,SWRC,IBOX,CLU,FHCU,ASD,MON,AVM,KBD
 SG_ NMCommandCode_IPM : 10|3@0+ (1,0) [0|0] ""  CLOCK,HUD,H_U,DATC,CCP,KMA_TMU,CUBIS,TMU,RSE_R,RRC,CGW,RSE_L,AMP,EDT,SWRC,IBOX,CLU,FHCU,ASD,MON,AVM,KBD

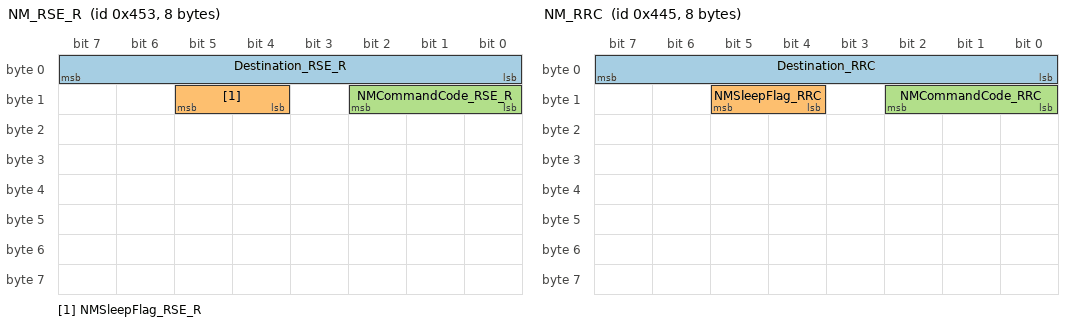
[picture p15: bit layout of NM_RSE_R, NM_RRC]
BO_ 1107 NM_RSE_R: 8 RSE_R
 SG_ Destination_RSE_R : 7|8@0+ (1,0) [0|0] ""  CLOCK,HUD,H_U,DATC,CCP,KMA_TMU,CUBIS,TMU,IPM,RRC,CGW,RSE_L,AMP,EDT,SWRC,IBOX,CLU,FHCU,ASD,MON,AVM,KBD
 SG_ NMSleepFlag_RSE_R : 13|2@0+ (1,0) [0|0] ""  CLOCK,HUD,H_U,DATC,CCP,KMA_TMU,CUBIS,TMU,IPM,RRC,CGW,RSE_L,AMP,EDT,SWRC,IBOX,CLU,FHCU,ASD,MON,AVM,KBD
 SG_ NMCommandCode_RSE_R : 10|3@0+ (1,0) [0|0] ""  CLOCK,HUD,H_U,DATC,CCP,KMA_TMU,CUBIS,TMU,IPM,RRC,CGW,RSE_L,AMP,EDT,SWRC,IBOX,CLU,FHCU,ASD,MON,AVM,KBD

BO_ 1093 NM_RRC: 8 RRC
 SG_ Destination_RRC : 7|8@0+ (1,0) [0|0] ""  CLOCK,HUD,H_U,DATC,CCP,KMA_TMU,CUBIS,TMU,IPM,RSE_R,CGW,RSE_L,AMP,EDT,SWRC,IBOX,CLU,FHCU,ASD,MON,AVM,KBD
 SG_ NMSleepFlag_RRC : 13|2@0+ (1,0) [0|0] ""  CLOCK,HUD,H_U,DATC,CCP,KMA_TMU,CUBIS,TMU,IPM,RSE_R,CGW,RSE_L,AMP,EDT,SWRC,IBOX,CLU,FHCU,ASD,MON,AVM,KBD
 SG_ NMCommandCode_RRC : 10|3@0+ (1,0) [0|0] ""  CLOCK,HUD,H_U,DATC,CCP,KMA_TMU,CUBIS,TMU,IPM,RSE_R,CGW,RSE_L,AMP,EDT,SWRC,IBOX,CLU,FHCU,ASD,MON,AVM,KBD

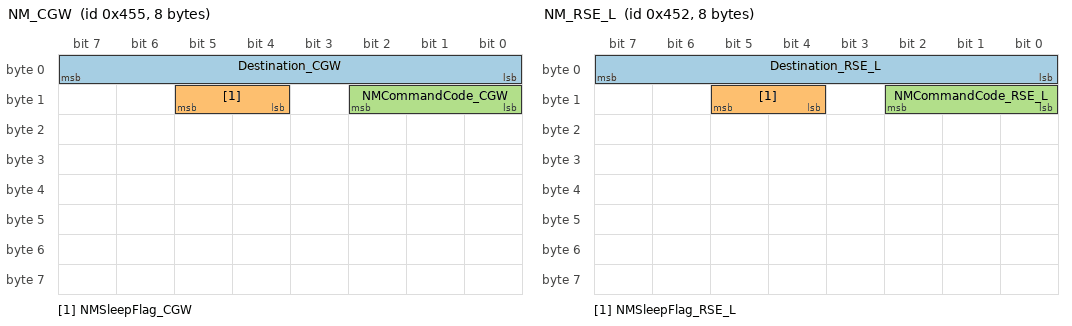
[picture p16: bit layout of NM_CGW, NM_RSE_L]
BO_ 1109 NM_CGW: 8 CGW
 SG_ Destination_CGW : 7|8@0+ (1,0) [0|0] ""  CLOCK,HUD,H_U,DATC,CCP,KMA_TMU,CUBIS,TMU,IPM,RSE_R,RRC,RSE_L,AMP,EDT,SWRC,IBOX,CLU,FHCU,ASD,MON,AVM,KBD
 SG_ NMSleepFlag_CGW : 13|2@0+ (1,0) [0|0] ""  CLOCK,HUD,H_U,DATC,CCP,KMA_TMU,CUBIS,TMU,IPM,RSE_R,RRC,RSE_L,AMP,EDT,SWRC,IBOX,CLU,FHCU,ASD,MON,AVM,KBD
 SG_ NMCommandCode_CGW : 10|3@0+ (1,0) [0|0] ""  CLOCK,HUD,H_U,DATC,CCP,KMA_TMU,CUBIS,TMU,IPM,RSE_R,RRC,RSE_L,AMP,EDT,SWRC,IBOX,CLU,FHCU,ASD,MON,AVM,KBD

BO_ 1106 NM_RSE_L: 8 RSE_L
 SG_ Destination_RSE_L : 7|8@0+ (1,0) [0|0] ""  CLOCK,HUD,H_U,DATC,CCP,KMA_TMU,CUBIS,TMU,IPM,RSE_R,RRC,CGW,AMP,EDT,SWRC,IBOX,CLU,FHCU,ASD,MON,AVM,KBD
 SG_ NMSleepFlag_RSE_L : 13|2@0+ (1,0) [0|0] ""  CLOCK,HUD,H_U,DATC,CCP,KMA_TMU,CUBIS,TMU,IPM,RSE_R,RRC,CGW,AMP,EDT,SWRC,IBOX,CLU,FHCU,ASD,MON,AVM,KBD
 SG_ NMCommandCode_RSE_L : 10|3@0+ (1,0) [0|0] ""  CLOCK,HUD,H_U,DATC,CCP,KMA_TMU,CUBIS,TMU,IPM,RSE_R,RRC,CGW,AMP,EDT,SWRC,IBOX,CLU,FHCU,ASD,MON,AVM,KBD

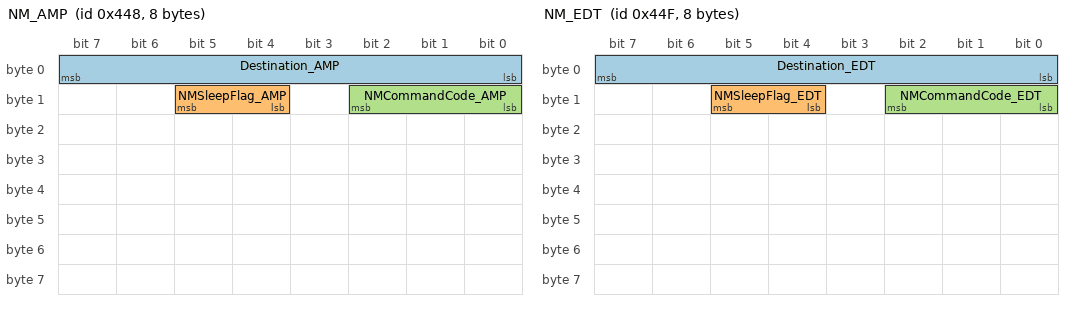
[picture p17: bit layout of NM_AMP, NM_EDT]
BO_ 1096 NM_AMP: 8 AMP
 SG_ Destination_AMP : 7|8@0+ (1,0) [0|0] ""  CLOCK,HUD,H_U,DATC,CCP,KMA_TMU,CUBIS,TMU,IPM,RSE_R,RRC,CGW,RSE_L,EDT,SWRC,IBOX,CLU,FHCU,ASD,MON,AVM,KBD
 SG_ NMSleepFlag_AMP : 13|2@0+ (1,0) [0|0] ""  CLOCK,HUD,H_U,DATC,CCP,KMA_TMU,CUBIS,TMU,IPM,RSE_R,RRC,CGW,RSE_L,EDT,SWRC,IBOX,CLU,FHCU,ASD,MON,AVM,KBD
 SG_ NMCommandCode_AMP : 10|3@0+ (1,0) [0|0] ""  CLOCK,HUD,H_U,DATC,CCP,KMA_TMU,CUBIS,TMU,IPM,RSE_R,RRC,CGW,RSE_L,EDT,SWRC,IBOX,CLU,FHCU,ASD,MON,AVM,KBD

BO_ 1103 NM_EDT: 8 EDT
 SG_ Destination_EDT : 7|8@0+ (1,0) [0|0] ""  CLOCK,HUD,H_U,DATC,CCP,KMA_TMU,CUBIS,TMU,IPM,RSE_R,RRC,CGW,RSE_L,AMP,SWRC,IBOX,CLU,FHCU,ASD,MON,AVM,KBD
 SG_ NMSleepFlag_EDT : 13|2@0+ (1,0) [0|0] ""  CLOCK,HUD,H_U,DATC,CCP,KMA_TMU,CUBIS,TMU,IPM,RSE_R,RRC,CGW,RSE_L,AMP,SWRC,IBOX,CLU,FHCU,ASD,MON,AVM,KBD
 SG_ NMCommandCode_EDT : 10|3@0+ (1,0) [0|0] ""  CLOCK,HUD,H_U,DATC,CCP,KMA_TMU,CUBIS,TMU,IPM,RSE_R,RRC,CGW,RSE_L,AMP,SWRC,IBOX,CLU,FHCU,ASD,MON,AVM,KBD

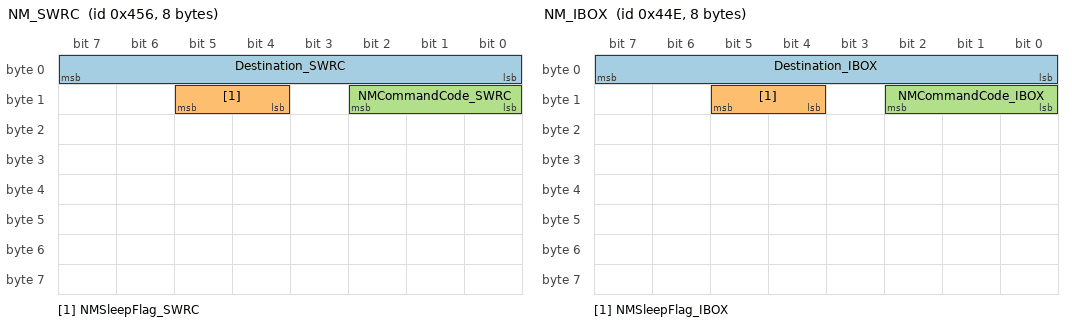
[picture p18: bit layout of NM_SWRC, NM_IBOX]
BO_ 1110 NM_SWRC: 8 SWRC
 SG_ Destination_SWRC : 7|8@0+ (1,0) [0|0] ""  CLOCK,HUD,H_U,DATC,CCP,KMA_TMU,CUBIS,TMU,IPM,RSE_R,RRC,CGW,RSE_L,AMP,EDT,IBOX,CLU,FHCU,ASD,MON,AVM,KBD
 SG_ NMSleepFlag_SWRC : 13|2@0+ (1,0) [0|0] ""  CLOCK,HUD,H_U,DATC,CCP,KMA_TMU,CUBIS,TMU,IPM,RSE_R,RRC,CGW,RSE_L,AMP,EDT,IBOX,CLU,FHCU,ASD,MON,AVM,KBD
 SG_ NMCommandCode_SWRC : 10|3@0+ (1,0) [0|0] ""  CLOCK,HUD,H_U,DATC,CCP,KMA_TMU,CUBIS,TMU,IPM,RSE_R,RRC,CGW,RSE_L,AMP,EDT,IBOX,CLU,FHCU,ASD,MON,AVM,KBD

BO_ 1102 NM_IBOX: 8 IBOX
 SG_ Destination_IBOX : 7|8@0+ (1,0) [0|0] ""  CLOCK,HUD,H_U,DATC,CCP,KMA_TMU,CUBIS,TMU,IPM,RSE_R,RRC,CGW,RSE_L,AMP,EDT,SWRC,CLU,FHCU,ASD,MON,AVM,KBD
 SG_ NMSleepFlag_IBOX : 13|2@0+ (1,0) [0|0] ""  CLOCK,HUD,H_U,DATC,CCP,KMA_TMU,CUBIS,TMU,IPM,RSE_R,RRC,CGW,RSE_L,AMP,EDT,SWRC,CLU,FHCU,ASD,MON,AVM,KBD
 SG_ NMCommandCode_IBOX : 10|3@0+ (1,0) [0|0] ""  CLOCK,HUD,H_U,DATC,CCP,KMA_TMU,CUBIS,TMU,IPM,RSE_R,RRC,CGW,RSE_L,AMP,EDT,SWRC,CLU,FHCU,ASD,MON,AVM,KBD

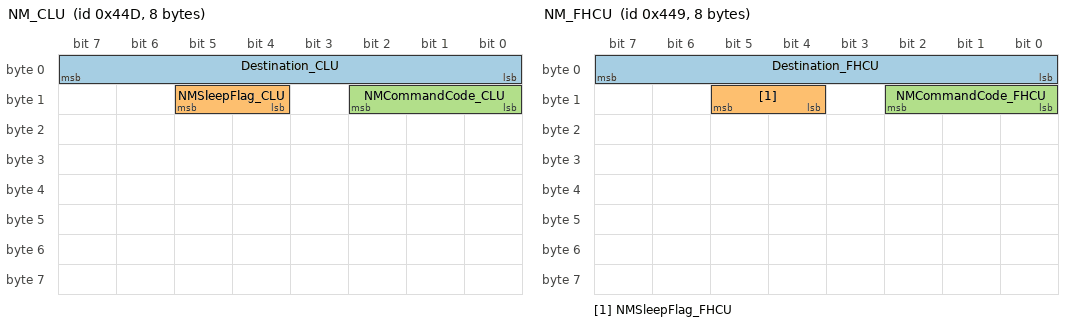
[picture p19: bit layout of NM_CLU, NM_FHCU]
BO_ 1101 NM_CLU: 8 CLU
 SG_ Destination_CLU : 7|8@0+ (1,0) [0|0] ""  CLOCK,HUD,H_U,DATC,CCP,KMA_TMU,CUBIS,TMU,IPM,RSE_R,RRC,CGW,RSE_L,AMP,EDT,SWRC,IBOX,FHCU,ASD,MON,AVM,KBD
 SG_ NMSleepFlag_CLU : 13|2@0+ (1,0) [0|0] ""  CLOCK,HUD,H_U,DATC,CCP,KMA_TMU,CUBIS,TMU,IPM,RSE_R,RRC,CGW,RSE_L,AMP,EDT,SWRC,IBOX,FHCU,ASD,MON,AVM,KBD
 SG_ NMCommandCode_CLU : 10|3@0+ (1,0) [0|0] ""  CLOCK,HUD,H_U,DATC,CCP,KMA_TMU,CUBIS,TMU,IPM,RSE_R,RRC,CGW,RSE_L,AMP,EDT,SWRC,IBOX,FHCU,ASD,MON,AVM,KBD

BO_ 1097 NM_FHCU: 8 FHCU
 SG_ Destination_FHCU : 7|8@0+ (1,0) [0|0] ""  CLOCK,HUD,H_U,DATC,CCP,KMA_TMU,CUBIS,TMU,IPM,RSE_R,RRC,CGW,RSE_L,AMP,EDT,SWRC,IBOX,CLU,ASD,MON,AVM,KBD
 SG_ NMSleepFlag_FHCU : 13|2@0+ (1,0) [0|0] ""  CLOCK,HUD,H_U,DATC,CCP,KMA_TMU,CUBIS,TMU,IPM,RSE_R,RRC,CGW,RSE_L,AMP,EDT,SWRC,IBOX,CLU,ASD,MON,AVM,KBD
 SG_ NMCommandCode_FHCU : 10|3@0+ (1,0) [0|0] ""  CLOCK,HUD,H_U,DATC,CCP,KMA_TMU,CUBIS,TMU,IPM,RSE_R,RRC,CGW,RSE_L,AMP,EDT,SWRC,IBOX,CLU,ASD,MON,AVM,KBD

BO_ 1094 NM_ASD: 8 ASD
 SG_ Destination_ASD : 7|8@0+ (1,0) [0|0] ""  CLOCK,HUD,H_U,DATC,CCP,KMA_TMU,CUBIS,TMU,IPM,RSE_R,RRC,CGW,RSE_L,AMP,EDT,SWRC,IBOX,CLU,FHCU,MON,AVM,KBD
 SG_ NMSleepFlag_ASD : 13|2@0+ (1,0) [0|0] ""  CLOCK,HUD,H_U,DATC,CCP,KMA_TMU,CUBIS,TMU,IPM,RSE_R,RRC,CGW,RSE_L,AMP,EDT,SWRC,IBOX,CLU,FHCU,MON,AVM,KBD
 SG_ NMCommandCode_ASD : 10|3@0+ (1,0) [0|0] ""  CLOCK,HUD,H_U,DATC,CCP,KMA_TMU,CUBIS,TMU,IPM,RSE_R,RRC,CGW,RSE_L,AMP,EDT,SWRC,IBOX,CLU,FHCU,MON,AVM,KBD

BO_ 1089 NM_MON: 8 MON
 SG_ Destination_MON : 7|8@0+ (1,0) [0|0] ""  CLOCK,HUD,H_U,DATC,CCP,KMA_TMU,CUBIS,TMU,IPM,RSE_R,RRC,CGW,RSE_L,AMP,EDT,SWRC,IBOX,CLU,FHCU,ASD,AVM,KBD
 SG_ NMSleepFlag_MON : 13|2@0+ (1,0) [0|0] ""  CLOCK,HUD,H_U,DATC,CCP,KMA_TMU,CUBIS,TMU,IPM,RSE_R,RRC,CGW,RSE_L,AMP,EDT,SWRC,IBOX,CLU,FHCU,ASD,AVM,KBD
 SG_ NMCommandCode_MON : 10|3@0+ (1,0) [0|0] ""  CLOCK,HUD,H_U,DATC,CCP,KMA_TMU,CUBIS,TMU,IPM,RSE_R,RRC,CGW,RSE_L,AMP,EDT,SWRC,IBOX,CLU,FHCU,ASD,AVM,KBD

BO_ 1104 NM_AVM: 8 AVM
 SG_ Destination_AVM : 7|8@0+ (1,0) [0|0] ""  CLOCK,HUD,H_U,DATC,CCP,KMA_TMU,CUBIS,TMU,IPM,RSE_R,RRC,CGW,RSE_L,AMP,EDT,SWRC,IBOX,CLU,FHCU,ASD,MON,KBD
 SG_ NMSleepFlag_AVM : 13|2@0+ (1,0) [0|0] ""  CLOCK,HUD,H_U,DATC,CCP,KMA_TMU,CUBIS,TMU,IPM,RSE_R,RRC,CGW,RSE_L,AMP,EDT,SWRC,IBOX,CLU,FHCU,ASD,MON,KBD
 SG_ NMCommandCode_AVM : 10|3@0+ (1,0) [0|0] ""  CLOCK,HUD,H_U,DATC,CCP,KMA_TMU,CUBIS,TMU,IPM,RSE_R,RRC,CGW,RSE_L,AMP,EDT,SWRC,IBOX,CLU,FHCU,ASD,MON,KBD

BO_ 1090 NM_KBD: 8 KBD
 SG_ Destination_KBD : 7|8@0+ (1,0) [0|0] ""  CLOCK,HUD,H_U,DATC,CCP,KMA_TMU,CUBIS,TMU,IPM,RSE_R,RRC,CGW,RSE_L,AMP,EDT,SWRC,IBOX,CLU,FHCU,ASD,MON,AVM
 SG_ NMSleepFlag_KBD : 13|2@0+ (1,0) [0|0] ""  CLOCK,HUD,H_U,DATC,CCP,KMA_TMU,CUBIS,TMU,IPM,RSE_R,RRC,CGW,RSE_L,AMP,EDT,SWRC,IBOX,CLU,FHCU,ASD,MON,AVM
 SG_ NMCommandCode_KBD : 10|3@0+ (1,0) [0|0] ""  CLOCK,HUD,H_U,DATC,CCP,KMA_TMU,CUBIS,TMU,IPM,RSE_R,RRC,CGW,RSE_L,AMP,EDT,SWRC,IBOX,CLU,FHCU,ASD,MON,AVM

CM_ BO_ 62 "[EC] On Event and On Change";
CM_ SG_ 62 Navi_SLIF_SpdUnit "Unit of Speed Limit for SLIF from NAVI to Camera";
CM_ SG_ 62 Navi_SLIF_Frwinfo "Freeway info for SLIF";
CM_ SG_ 62 Navi_SLIF_LinkClass "Link Class for SLIF";
CM_ SG_ 62 Navi_SLIF_SpdLimit "Speed of Speed Limit for SLIF from NAVI to Camera";
CM_ SG_ 62 Navi_SLIFMapSource "Map source signal for SLIF with TOMTOM service in EU
(NT.TT.ETC)";
CM_ SG_ 62 Navi_SLIF_CountryCode "Country Code for SLIF";
CM_ BO_ 52 "[EC] On Event and On Change";
CM_ SG_ 52 HU_DATC_DrTempUpDn "Temperature control of Driver side";
CM_ SG_ 52 HU_DATC_PsTempUpDn "Temperature control of Passenger side";
CM_ SG_ 52 HU_DATC_RlTempUpDn "In 3-zone system, Temperature control of rear side.
In 4-zone system, Temperature control of rear left side.";
CM_ SG_ 52 HU_DATC_RrTempUpDn "Only for 4-zone system, Temperature control of rear right side";
CM_ SG_ 52 HU_DATC_MainBlower "Main Blower control";
CM_ SG_ 52 HU_DATC_SubBlower "Sub Blower control";
CM_ SG_ 52 HU_DATC_RearBlower "Rear Blower control";
CM_ SG_ 52 HU_DATCRearPsModeSet "후석 조수석 MODE 설정 신호";
CM_ SG_ 52 HU_DATC_FrontModeSet "DATC Mode control";
CM_ SG_ 52 HU_DATC_RearModeSet "DATC Mode control";
CM_ SG_ 52 HU_DATC_AutoSet "DATC Auto control";
CM_ SG_ 52 HU_DATC_OffReq "DATC Off";
CM_ SG_ 52 HU_DATC_IntakeSet "DATC Intake control";
CM_ SG_ 52 HU_DATC_RearOnOffSet "HU_DATC_RearOnOffSet";
CM_ SG_ 52 HU_DATC_AcSet "DATC A/C control";
CM_ SG_ 52 HU_DATC_AqsSet "DATC AQS control";
CM_ SG_ 52 HU_DATC_FrontDefog "Front window Defog";
CM_ SG_ 52 HU_DATC_RearDefog "Rear window Defog";
CM_ SG_ 52 HU_DATC_ZoneControl "DATC independent zone control (Dual/3-Zone/4-Zone)";
CM_ SG_ 52 HU_DATC_CO2Set "CO2 Sensor On/Off";
CM_ SG_ 52 DATC_SmartVentOnOffSet "Smart Ventilation On/Off Set Command";
CM_ SG_ 52 DATC_ADSOnOffSet "ADS(Auto Defog System) On/Off Set Command";
CM_ SG_ 52 HU_DATC_RearAutoDisp "후석 Auto 모드 설정 신호";
CM_ SG_ 52 HU_DATC_RearOffDisp "후석 공조 Off 표시 설정 신호";
CM_ BO_ 308 "[PE] Periodic and On Event";
CM_ SG_ 308 DATC_AltL "AltL Status from CLU";
CM_ SG_ 308 DATC_CarInfo "Car Information";
CM_ SG_ 308 DATC_ParkingBrake "ParkingBrake from EPB";
CM_ SG_ 308 DATC_LowFuelWarn "LowFuelWarning from CLU";
CM_ SG_ 308 DATC_DrSeatWarmerDisp "OPERATING STATUS OF DRIVER-SIDE SEAT WARMER";
CM_ SG_ 308 DATC_SyncDisp "Rear& Front HVAC";
CM_ SG_ 308 DATC_RearDispCtrl "information for Rear HVAC Control State";
CM_ SG_ 308 DATC_RearDrModeDisp "Display Mode for rear left side. In case of 3 zone, this signal is for rear mode.";
CM_ SG_ 308 DATC_PsSeatWarmerDisp "OPERATING STATUS OF PASSENGER-SIDE SEAT WARMER";
CM_ SG_ 308 DATC_DrVentSeatDisp "Operating status of deiver-side ventilation seat";
CM_ SG_ 308 DATC_PSVentSeatDisp "Operating status of passenger-side ventilatioan seat";
CM_ SG_ 308 DATC_RrDefLed "Rear Def LED 점등신호";
CM_ SG_ 308 DATC_SmartVentOnOffStatus "Activation Status of Smart Ventilation";
CM_ SG_ 308 DATC_ADSOnOffStatus "Activation Status of ADS(Auto Defog System)";
CM_ SG_ 308 DATC_AcDisp_OSD "AC display for OSD screen";
CM_ SG_ 308 DATC_PsModeDisp_OSD "PS modedisplay for OSD screen";
CM_ SG_ 308 DATC_ModeDisp_OSD "Mode display for OSD screen, not for full screen";
CM_ BO_ 307 "[PE] Periodic and On Event";
CM_ SG_ 307 DATC_DiagMode "Inform DATC Self diagnosis Stop/Start";
CM_ SG_ 307 DATC_Rear_ChangeReqDisp "Show OSD of climate infor in rear display";
CM_ SG_ 307 DATC_Rear_ClimateScnDisp "Show Full Climate Mode in rear display";
CM_ SG_ 307 DATC_CO2OnOffStatus "Activation Status of Co2 Function";
CM_ SG_ 307 DATC_SelfDiagDisp "Inform HVAC Controller or Sensor error";
CM_ SG_ 307 DATC_RearBlwDisp_OSD "Rear Blower 표시 (상태표시창 용)";
CM_ SG_ 307 DATC_AqsLevelOut "Display AQS Level";
CM_ SG_ 307 DATC_RearModeDisp "Rear Mode";
CM_ SG_ 307 DATC_RearPsModeDisp ".";
CM_ SG_ 307 DATC_FrontBlwDisp_Ps "DATC Front BLower Display-Ps";
CM_ SG_ 307 DATC_AutoDisp_Ps ".";
CM_ SG_ 307 DATC_RearModeDisp_OSD "Rear Mode disply for status line";
CM_ SG_ 307 DATC_RearPSModeDisp_OSD "Rear PS mode display for Status Line";
CM_ SG_ 307 DATC_FrontBlwDispPs_OSD "Front Blower 표시용 (상태표시창 용)";
CM_ SG_ 307 DATC_Variant "DATC Option Variant Information";
CM_ BO_ 306 "[PE] Periodic and On Event";
CM_ SG_ 306 DATC_ModeDisp "Display DATC Mode of Driver side

Basic Modes
- Defog : Defog
- Vent : Upper
- Def : Middle
- Floor : Lower

Mixed Modes
- Auto Defog : Defog + Auto 
- Max Defog : Defog + Seat

* Compatabilityfor old value table 
- Vent/Floor : same with old B/L 
- Defog/Floor : same with old MIX 
- Max Defog : same with old DEF";
CM_ SG_ 306 DATC_TempUnit "Unit of Temperature";
CM_ SG_ 306 DATC_AutoDisp "Display AUTO";
CM_ SG_ 306 DATC_IntakeDisp "Display INTAKE";
CM_ SG_ 306 DATC_ChangeReqDisp "Refresh DATC display";
CM_ SG_ 306 DATC_AcDisp "Display A/C";
CM_ SG_ 306 DATC_AqsDisp "Display AQS";
CM_ SG_ 306 DATC_ClimateScnDisp "Display DATC Full screen";
CM_ SG_ 306 DATC_DualDisp "Display DUAL";
CM_ SG_ 306 DATC_OffDisp "Display OFF";
CM_ SG_ 306 DATC_OpSts "Display DATC Operation Status";
CM_ SG_ 306 DATC_RearManual "Supported Features";
CM_ SG_ 306 DATC_FrDefLed ".";
CM_ SG_ 306 DATC_SmartVentDisp "Operation Status of Smart Ventilation";
CM_ SG_ 306 DATC_AutoDefogBlink "Blink Auto DEFOG";
CM_ SG_ 306 DATC_ADSDisp "Operation Status of ADS(Auto Defog System)";
CM_ SG_ 306 DATC_IonClean "Display ION/CLEAN";
CM_ SG_ 306 DATC_CO2Warning "Display CO2 warning";
CM_ SG_ 306 DATC_BeepReq "beep음 요구";
CM_ SG_ 306 DATC_MainBlowerDisp "Display Level of Main Blower";
CM_ SG_ 306 DATC_PsModeDisp "Display DATC Mode of Passenger side";
CM_ BO_ 1329 "[P] Periodic";
CM_ SG_ 1329 DATC_AmbientTemp_C "Ext temprature : C";
CM_ SG_ 1329 DATC_AmbientTemp_F "Ext temperature : F";
CM_ BO_ 305 "[PE] Periodic and On Event";
CM_ SG_ 305 DATC_DrTempDispC "Temperature of Driver seat (C)";
CM_ SG_ 305 DATC_Rear_DrTempDispC "Temperature of RearLeft seat (Centigrade)";
CM_ SG_ 305 DATC_DrTempDispF "Temperature of Driver seat (F)";
CM_ SG_ 305 DATC_Rear_DrTempDispF "Temperature of RearLeft seat (Fahrenheit)";
CM_ SG_ 305 DATC_PsTempDispC "Temperature of Passenger seat (C)";
CM_ SG_ 305 Datc_RearPsTempDispC "Setting Temperature of Rear Ps side

PHY = = (HEX*0.5 +14)";
CM_ SG_ 305 DATC_PsTempDispF "Temperature of Passenger seat (F)";
CM_ SG_ 305 DATC_RearPsTempDispF "Temperature of RearLeft seat (Fahrenheit)

PHY = =(HEX*1.0 + 56)";
CM_ BO_ 304 "[PE] Periodic and On Event";
CM_ BO_ 291 "[PE] Periodic and On Event";
CM_ SG_ 291 TBT_BarGraph100Level "Bar Graph Level (0 ~ 100%, 10% interval), 
if your system develop after 2012-09-10, you must not use TBT_Bar_Level(@0x115)";
CM_ BO_ 290 "[PE] Periodic and On Event";
CM_ BO_ 286 "[PE] Periodic and On Event";
CM_ SG_ 286 Navi_TBTInfo "TBT Info for Cluster";
CM_ BO_ 29 "[EC] On Event and On Change";
CM_ SG_ 29 CLU_ClockInfoReq "Reqeust Clock Information";
CM_ SG_ 29 CLU_DateInfoReq "Reqeust Date Information";
CM_ BO_ 27 "[EC] On Event and On Change";
CM_ BO_ 23 "[EC] On Event and On Change";
CM_ SG_ 23 C_ADrLNValueSet "Auto Door Lock User Selection mode new setting value signal from DIS";
CM_ SG_ 23 C_ADrUNValueSet "Auto Door Unlock User Selection mode new setting value signal from DIS";
CM_ SG_ 23 SYS_Ver_Req "ECU의 소프트웨어 버전을 물어봄";
CM_ SG_ 23 C_IMSRValueReq "IMS user selection mode status current set value Request signal from DIS";
CM_ SG_ 23 C_PSMNValueSet "PSM User Selection Mode new setting from DIS";
CM_ SG_ 23 C_SCMNValueSet "SCM User Selection Mode new setting value signal from DIS";
CM_ SG_ 23 C_ADrLURValueReq "Auto Door Lock user selection mode status current set value Request signal from DIS";
CM_ SG_ 23 C_ABuzzerNValueSet "Answer Buzzer User Selection mode new setting value signal from DIS";
CM_ SG_ 23 C_AlarmRValueReq "Blaram Alarm user selection mode status current set value Request signal from DIS";
CM_ SG_ 23 C_ArmWKeyNValueSet "Burglar Alarm User Selection mode new setting value signal from DIS";
CM_ SG_ 23 C_TwUnRValueReq "Request send the data of current 'Twice Unlock Mode' value";
CM_ SG_ 23 C_TwUnNValueSet "Request set the new Twice Unlock Mode Value";
CM_ SG_ 23 C_AutoMRFoldRValueReq "Request send the data of Auto Mirror Fold Mode value";
CM_ SG_ 23 C_AutoMRFoldNValueSet "Request set the new Auto mirror Fold Mode";
CM_ SG_ 23 C_ADrLRValueReq "Request send the data of Current Auto Door Lock Mode value";
CM_ SG_ 23 C_ArmWKeyRValueReq "Request send the data of Current Burglar Alarm  Mode value";
CM_ SG_ 23 C_ABuzzerRValueReq "Request send the data of Current Door Lock Sound Mode value";
CM_ SG_ 23 C_ADrURValueReq "Request send the data of Current Auto Door Unlock Mode value";
CM_ SG_ 23 C_PSMRValueReq "Request send the data of Current Seat Easy Access Mode value";
CM_ SG_ 23 C_SCMRValueReq "Request send the data of Current Steering Easy Access Mode value";
CM_ BO_ 277 "[PE] Periodic and On Event";
CM_ SG_ 277 TBT_Display_Type "Display type";
CM_ SG_ 277 TBT_Side_Street "Using according to display type definition";
CM_ SG_ 277 TBT_Direction "Exit road’s direction(7.5 deg. Interval)";
CM_ SG_ 277 TBT_Distance_Turn_Point "Remaining distance to turn point (over Zero Point)";
CM_ SG_ 277 TBT_Combined_Side_Street "Using according to display type definition";
CM_ SG_ 277 TBT_Scale "Scale unit (m, km, mile, feet)";
CM_ SG_ 277 TBT_DistancetoTurnPoint "Remaining distance to turn point (under Zero Point)";
CM_ SG_ 277 TBT_Bar_Graph_Level "Bar Graph Level (0 ~ 100%, 10% interval)";
CM_ BO_ 276 "[PE] Periodic and On Event";
CM_ SG_ 276 HU_OpState "Information that Headunit display device (or Monitor )operates now";
CM_ SG_ 276 HU_Navi_On_Off "Navigation On/Off";
CM_ SG_ 276 HU_Preset_Number "Preset Number info";
CM_ SG_ 276 HU_Tuner_Area "Radio Area Information";
CM_ SG_ 276 HU_Track_Number "Number of track, chapter, file or song";
CM_ SG_ 276 HU_Play_time_Sec "Play time information of Media";
CM_ SG_ 276 HU_Play_time_Min "Play time information of Media";
CM_ SG_ 276 HU_Play_time_Hour "Play time information of Media";
CM_ SG_ 276 HU_Disc_select_No "DISC selection information";
CM_ SG_ 276 HU_Frequency "Radio Frequency Information , DVD Title Number";
CM_ BO_ 17 "[EC] On Event and On Change";
CM_ SG_ 17 AMP_Beep2VolumeStep "Beep2 volume setting";
CM_ SG_ 17 AMP_Beep2Frequency "Beep2 frequency  setting";
CM_ SG_ 17 AMP_Beep2Ch_OutputMask "Bit mask used to identify which speakers will output beep2";
CM_ SG_ 17 AMP_Beep2DurationOn "Beep2 on-time setting
(the middle pause in double beep = 0.5 x AMP_Beep2DurationOn)";
CM_ SG_ 17 AMP_Beep2DurationOff "Beep 2 Off time setting";
CM_ SG_ 17 AMP_Beep2NumberOfCycles "Beep2 repetition numbern setting";
CM_ BO_ 15 "[EC] On Event and On Change";
CM_ SG_ 15 AMP_MainVolumeSet "Main audio volume setting";
CM_ SG_ 15 AMP_BalanceSet "Left/Right Audio Balance setting";
CM_ SG_ 15 AMP_FadeSet "Front/rear audio fader setting";
CM_ SG_ 15 AMP_BassSet "Bass tone control setting";
CM_ SG_ 15 AMP_MidSet "Mid-range tone control setting";
CM_ SG_ 15 AMP_TrebleSet "Treble tone control setting";
CM_ BO_ 14 "[EC] On Event and On Change";
CM_ SG_ 14 AMP_HFVolumeStep "HF call volume setting";
CM_ SG_ 14 AMP_HFMainAudioCut "SPDIF audio volume cut setting during HF call";
CM_ SG_ 14 AMP_HFChannelOutputMask "Bit mask used to identify which speakers will output HF call";
CM_ SG_ 14 AMP_HFChannelMuteMask "Bit mask used to identify which speakers will mute main audio during HF call";
CM_ BO_ 13 "[EC] On Event and On Change";
CM_ SG_ 13 AMP_MTSVolumeStep "MTS call voume Setting";
CM_ SG_ 13 AMP_MTSMainAudioCut "SPDIF audio volume cut setting during MTS call";
CM_ SG_ 13 AMP_MTSChannelOutputMask "Bit mask used to identify which speakers will output MTS call";
CM_ SG_ 13 AMP_MTSChannelMuteMask "Bit mask used to identify which speakers will mute main audio during MTS call";
CM_ BO_ 12 "[EC] On Event and On Change";
CM_ SG_ 12 AMP_NaviVolumeStep "Navigation prompt volume setting";
CM_ SG_ 12 AMP_NaviMainAudioCut "Main audio volume cut setting during Navigation prompt";
CM_ SG_ 12 AMP_NaviChannelOutputMask "Bit mask used to identify which speakers will output NAVI prompt";
CM_ SG_ 12 AMP_NaviChannelMuteMask "Bit mask used to identify which speakers will mute main audio during NAVI prompt";
CM_ BO_ 11 "[EC] On Event and On Change";
CM_ SG_ 11 AMP_Drive "AMP Driver Side State";
CM_ SG_ 11 AMP_ConvertibleTop "Convertible top up/down status";
CM_ BO_ 10 "[EC] On Event and On Change";
CM_ SG_ 10 AMP_CrtVehicleID "Vehicle ID information";
CM_ SG_ 10 AMP_SPDIFMode "SPDIF audio source information";
CM_ SG_ 10 AMP_VersionReq "To Display current version of AMP on Headunit monitor in engineering More";
CM_ SG_ 10 AMP_UpdateStart "AMP Update？Command Start？";
CM_ SG_ 10 AMP_UpdateEnd "AMP Update？Command End？";
CM_ BO_ 9 "[EC] On Event and On Change";
CM_ SG_ 9 AMP_Mute "Mute all speakers";
CM_ SG_ 9 AMP_RearSpMute "Mute rear speakers during RSE use";
CM_ SG_ 9 AMP_SurroundMode "turn surround On/Off";
CM_ SG_ 9 AMP_VEQMode "VEQ On/Off";
CM_ SG_ 9 AMP_AudioMode "set audio mode for EQ selection";
CM_ SG_ 9 AMP_EQ "Report the current EQ status";
CM_ SG_ 9 AMP_Reset "Signal for external amp reinitiation process";
CM_ SG_ 9 AMP_SPDIFMute "Command to only SPDIF sound mute";
CM_ SG_ 9 AMP_DefaultBeep1 "Command to output beep sound asd default beep-1 settings in amplifier";
CM_ SG_ 9 AMP_DefaultBeep2 "Command to output beep sound asd default beep-2 settings in amplifier";
CM_ SG_ 9 AMP_BeatsMode "Tunr Beats On/Off";
CM_ SG_ 9 AMP_VIPMode "Turn VIP mode ON/OFF";
CM_ SG_ 9 AMP_QLSMode "Turn Quantum Logic Surround ON/OFF";
CM_ BO_ 1288 "[P] Periodic";
CM_ SG_ 1288 NV_TIME_TYPE "예정시간 종별";
CM_ SG_ 1288 NV_Hour "Time(Hours)";
CM_ SG_ 1288 NV_Min "Time(Minutes)";
CM_ BO_ 8 "[EC] On Event and On Change";
CM_ SG_ 8 AMP_HFMode "HF call on/off";
CM_ SG_ 8 AMP_NaviMode "Navi prompt on/off";
CM_ SG_ 8 AMP_MTSMode "MTS call on/off";
CM_ SG_ 8 AMP_VSCMode "Vehicle Speed Compensation on/off";
CM_ SG_ 8 AMP_Beep1Mode "Beep1 mode on/off";
CM_ SG_ 8 AMP_Beep2Mode "Beep2 mode on/off";
CM_ SG_ 8 AMP_SDVCStep "SDVC step4 : off,low,mid,high";
CM_ SG_ 8 AMP_ASDMode "ASD Set Mode Value";
CM_ SG_ 8 AMP_SignalDoctor "Turn SignalDoctor ON/OFF";
CM_ SG_ 8 AMP_AutoVolume "Turn AutoVolume ON/OFF";
CM_ BO_ 1287 "[P] Periodic";
CM_ BO_ 1286 "[P] Periodic";
CM_ SG_ 1286 NV_EstimTimeFormat "Time Format of Estimated Arrival Time";
CM_ BO_ 1284 "[P] Periodic";
CM_ SG_ 1284 HU_VehicleSpeed "Vehicle Speed information setting";
CM_ SG_ 1284 AMP_SetMaxMainVolStep "Set AMP’s  Main Volume max step";
CM_ SG_ 1284 AMP_LKASWarningOn "LKAS Warning Alarm On/Off";
CM_ SG_ 1284 AMP_BSDWarningOn "BSD Warning Alarm On/Off";
CM_ BO_ 256 "[PE] Periodic and On Event";
CM_ SG_ 256 HU_Type "H/U type";
CM_ SG_ 256 HU_VerMajor "Major version";
CM_ SG_ 256 HU_VerMinor "Minor version";
CM_ SG_ 256 HU_DistributeInfo "Region :Europe/North America/
Vehicle Type : RHD/LHD
Positionning information";
CM_ SG_ 256 HU_SubVerMajor "Head Unit Submicom Major version";
CM_ SG_ 256 HU_SubVerMinor "Head Unit Submicom Minor version";
CM_ SG_ 256 HU_SDARSVersion "Head Unit SDARS(Sirius/XM) Version";
CM_ SG_ 256 HU_AdasSupport "Information about ADAS support";
CM_ BO_ 1092 "NM Message";
CM_ BO_ 1108 "NM Message";
CM_ BO_ 1088 "NM Message";
CM_ BO_ 1091 "NM Message";
CM_ BO_ 1105 "NM Message";
CM_ BO_ 1100 "NM Message";
CM_ BO_ 1098 "NM Message";
CM_ BO_ 1099 "NM Message";
CM_ BO_ 1095 "NM Message";
CM_ BO_ 1107 "NM Message";
CM_ BO_ 1093 "NM Message";
CM_ BO_ 1109 "NM Message";
CM_ BO_ 1106 "NM Message";
CM_ BO_ 1096 "NM Message";
CM_ BO_ 1103 "NM Message";
CM_ BO_ 1110 "NM Message";
CM_ BO_ 1102 "NM Message";
CM_ BO_ 1101 "NM Message";
CM_ BO_ 1097 "NM Message";
CM_ BO_ 1094 "NM Message";
CM_ BO_ 1089 "NM Message";
CM_ BO_ 1104 "NM Message";
CM_ BO_ 1090 "NM Message";
BA_DEF_ SG_  "Gatewaysignal" ENUM  "No","M-B","B-M","M-C","C-M","M-C-B";
BA_DEF_ SG_  "GenSigEnvVarType" ENUM  "Int","Float","undef";
BA_DEF_ SG_  "GenSigSendType" ENUM  "Cyclic","OnWrite","OnWriteWithRepetition","OnChange","OnChangeWithRepetition","IfActive","IfActiveWithRepetition","NoSigSendType";
BA_DEF_ SG_  "GenSigStartValue" INT 0 0;
BA_DEF_ SG_  "GwSigLatencyTime" INT 0 65535;
BA_DEF_ SG_  "GwSigMissingSourceType" ENUM  "Undef","OldValue","DefaultValue","InitialValue";
BA_DEF_ SG_  "NmNetworkRequest" ENUM  "No","Yes";
BA_DEF_ SG_  "NmNetworkRequestHoldingTime" INT 0 65535;
BA_DEF_ SG_  "Purpose" ENUM  "<t.b.d.>","Function","Diagnostic","Development","NM";
BA_DEF_ SG_  "SignalCategory" HEX 10 15;
BA_DEF_ SG_  "TimeoutValue" STRING ;
BA_DEF_ SG_  "UpdateRateMax" INT 0 0;
BA_DEF_ SG_  "UpdateRateMin" INT 0 0;
BA_DEF_ SG_  "Validity" ENUM  "B+","ACC","IGN1","IGN2";
BA_DEF_ BO_  "DiagRequest" ENUM  "No","Yes";
BA_DEF_ BO_  "DiagResponse" ENUM  "No","Yes";
BA_DEF_ BO_  "DiagState" ENUM  "No","Yes";
BA_DEF_ BO_  "GenMsgCycleTime" INT 0 100000;
BA_DEF_ BO_  "GenMsgCycleTimeFast" INT 0 500;
BA_DEF_ BO_  "GenMsgDelayTime" INT 0 20;
BA_DEF_ BO_  "GenMsgEVName" STRING ;
BA_DEF_ BO_  "GenMsgILSupport" ENUM  "No","Yes";
BA_DEF_ BO_  "GenMsgNrOfRepetition" INT 0 3;
BA_DEF_ BO_  "GenMsgSendType" ENUM  "Cyclic","not_used","not_used","not_used","not_used","not_used","not_used","not_used","NoMsgSendType";
BA_DEF_ BO_  "GenMsgStartDelayTime" INT 0 2000;
BA_DEF_ BO_  "NmMessage" ENUM  "No","Yes";
BA_DEF_ BO_  "RoutingType" ENUM  "<n.a.>","Direct","Indirect";
BA_DEF_ BO_  "TpMessage" ENUM  "No","Yes";
BA_DEF_ BO_  "TpTxIndex" INT 0 255;
BA_DEF_REL_ BU_SG_REL_  "GenSigTimeoutTime" INT 0 7000;
BA_DEF_DEF_  "Gatewaysignal" "No";
BA_DEF_DEF_  "GenSigEnvVarType" "undef";
BA_DEF_DEF_  "GenSigSendType" "NoSigSendType";
BA_DEF_DEF_  "GenSigStartValue" 0;
BA_DEF_DEF_  "GwSigLatencyTime" 40;
BA_DEF_DEF_  "GwSigMissingSourceType" "Undef";
BA_DEF_DEF_  "NmNetworkRequest" "No";
BA_DEF_DEF_  "NmNetworkRequestHoldingTime" 0;
BA_DEF_DEF_  "Purpose" "<t.b.d.>";
BA_DEF_DEF_  "SignalCategory" 12;
BA_DEF_DEF_  "TimeoutValue" "";
BA_DEF_DEF_  "UpdateRateMax" 0;
BA_DEF_DEF_  "UpdateRateMin" 0;
BA_DEF_DEF_  "Validity" "ACC";
BA_DEF_DEF_  "DiagRequest" "No";
BA_DEF_DEF_  "DiagResponse" "No";
BA_DEF_DEF_  "DiagState" "No";
BA_DEF_DEF_  "GenMsgCycleTime" 0;
BA_DEF_DEF_  "GenMsgCycleTimeFast" 0;
BA_DEF_DEF_  "GenMsgDelayTime" 20;
BA_DEF_DEF_  "GenMsgEVName" "@Signame";
BA_DEF_DEF_  "GenMsgILSupport" "Yes";
BA_DEF_DEF_  "GenMsgNrOfRepetition" 0;
BA_DEF_DEF_  "GenMsgSendType" "NoMsgSendType";
BA_DEF_DEF_  "GenMsgStartDelayTime" 0;
BA_DEF_DEF_  "NmMessage" "No";
BA_DEF_DEF_  "RoutingType" "<n.a.>";
BA_DEF_DEF_  "TpMessage" "No";
BA_DEF_DEF_  "TpTxIndex" 0;
BA_DEF_DEF_REL_ "GenSigTimeoutTime" 700;
BA_ "GenMsgCycleTimeFast" BO_ 62 40;
BA_ "GenMsgNrOfRepetition" BO_ 62 3;
BA_ "GenMsgCycleTimeFast" BO_ 52 40;
BA_ "GenMsgNrOfRepetition" BO_ 52 3;
BA_ "GenMsgSendType" BO_ 308 0;
BA_ "GenMsgCycleTime" BO_ 308 1000;
BA_ "GenMsgCycleTimeFast" BO_ 308 40;
BA_ "GenMsgNrOfRepetition" BO_ 308 3;
BA_ "GenMsgStartDelayTime" BO_ 308 50;
BA_ "GenMsgSendType" BO_ 307 0;
BA_ "GenMsgCycleTime" BO_ 307 200;
BA_ "GenMsgCycleTimeFast" BO_ 307 40;
BA_ "GenMsgNrOfRepetition" BO_ 307 3;
BA_ "GenMsgStartDelayTime" BO_ 307 60;
BA_ "GenMsgSendType" BO_ 306 0;
BA_ "GenMsgCycleTime" BO_ 306 1000;
BA_ "GenMsgCycleTimeFast" BO_ 306 40;
BA_ "GenMsgNrOfRepetition" BO_ 306 3;
BA_ "GenMsgStartDelayTime" BO_ 306 70;
BA_ "GenMsgSendType" BO_ 1329 0;
BA_ "GenMsgCycleTime" BO_ 1329 200;
BA_ "GenMsgSendType" BO_ 305 0;
BA_ "GenMsgCycleTime" BO_ 305 1000;
BA_ "GenMsgCycleTimeFast" BO_ 305 40;
BA_ "GenMsgNrOfRepetition" BO_ 305 3;
BA_ "GenMsgStartDelayTime" BO_ 305 80;
BA_ "GenMsgSendType" BO_ 304 0;
BA_ "GenMsgCycleTime" BO_ 304 1000;
BA_ "GenMsgCycleTimeFast" BO_ 304 40;
BA_ "GenMsgNrOfRepetition" BO_ 304 3;
BA_ "GenMsgStartDelayTime" BO_ 304 90;
BA_ "GenMsgSendType" BO_ 291 0;
BA_ "GenMsgCycleTime" BO_ 291 200;
BA_ "GenMsgCycleTimeFast" BO_ 291 40;
BA_ "GenMsgNrOfRepetition" BO_ 291 3;
BA_ "GenMsgStartDelayTime" BO_ 291 80;
BA_ "GenMsgSendType" BO_ 290 0;
BA_ "GenMsgCycleTime" BO_ 290 200;
BA_ "GenMsgCycleTimeFast" BO_ 290 40;
BA_ "GenMsgNrOfRepetition" BO_ 290 3;
BA_ "GenMsgStartDelayTime" BO_ 290 40;
BA_ "GenMsgSendType" BO_ 286 0;
BA_ "GenMsgCycleTime" BO_ 286 200;
BA_ "GenMsgCycleTimeFast" BO_ 286 40;
BA_ "GenMsgNrOfRepetition" BO_ 286 3;
BA_ "GenMsgStartDelayTime" BO_ 286 150;
BA_ "GenMsgCycleTimeFast" BO_ 29 40;
BA_ "GenMsgNrOfRepetition" BO_ 29 3;
BA_ "GenMsgCycleTimeFast" BO_ 27 40;
BA_ "GenMsgNrOfRepetition" BO_ 27 3;
BA_ "GenMsgCycleTimeFast" BO_ 23 40;
BA_ "GenMsgNrOfRepetition" BO_ 23 3;
BA_ "GenMsgSendType" BO_ 277 0;
BA_ "GenMsgCycleTime" BO_ 277 200;
BA_ "GenMsgCycleTimeFast" BO_ 277 40;
BA_ "GenMsgNrOfRepetition" BO_ 277 3;
BA_ "GenMsgStartDelayTime" BO_ 277 70;
BA_ "GenMsgSendType" BO_ 276 0;
BA_ "GenMsgCycleTime" BO_ 276 200;
BA_ "GenMsgCycleTimeFast" BO_ 276 40;
BA_ "GenMsgNrOfRepetition" BO_ 276 3;
BA_ "GenMsgStartDelayTime" BO_ 276 80;
BA_ "GenMsgCycleTimeFast" BO_ 17 40;
BA_ "GenMsgNrOfRepetition" BO_ 17 3;
BA_ "GenMsgCycleTimeFast" BO_ 15 40;
BA_ "GenMsgNrOfRepetition" BO_ 15 3;
BA_ "GenMsgCycleTimeFast" BO_ 14 40;
BA_ "GenMsgNrOfRepetition" BO_ 14 3;
BA_ "GenMsgCycleTimeFast" BO_ 13 40;
BA_ "GenMsgNrOfRepetition" BO_ 13 3;
BA_ "GenMsgCycleTimeFast" BO_ 12 40;
BA_ "GenMsgNrOfRepetition" BO_ 12 3;
BA_ "GenMsgCycleTimeFast" BO_ 11 40;
BA_ "GenMsgNrOfRepetition" BO_ 11 3;
BA_ "GenMsgCycleTimeFast" BO_ 10 40;
BA_ "GenMsgNrOfRepetition" BO_ 10 3;
BA_ "GenMsgCycleTimeFast" BO_ 9 40;
BA_ "GenMsgNrOfRepetition" BO_ 9 3;
BA_ "GenMsgSendType" BO_ 1288 0;
BA_ "GenMsgCycleTime" BO_ 1288 200;
BA_ "GenMsgStartDelayTime" BO_ 1288 20;
BA_ "GenMsgCycleTimeFast" BO_ 8 40;
BA_ "GenMsgNrOfRepetition" BO_ 8 3;
BA_ "GenMsgSendType" BO_ 1287 0;
BA_ "GenMsgCycleTime" BO_ 1287 200;
BA_ "GenMsgStartDelayTime" BO_ 1287 20;
BA_ "GenMsgSendType" BO_ 1286 0;
BA_ "GenMsgCycleTime" BO_ 1286 200;
BA_ "GenMsgStartDelayTime" BO_ 1286 10;
BA_ "GenMsgSendType" BO_ 1284 0;
BA_ "GenMsgCycleTime" BO_ 1284 200;
BA_ "GenMsgStartDelayTime" BO_ 1284 20;
BA_ "GenMsgSendType" BO_ 256 0;
BA_ "GenMsgCycleTime" BO_ 256 2000;
BA_ "GenMsgCycleTimeFast" BO_ 256 40;
BA_ "GenMsgNrOfRepetition" BO_ 256 3;
BA_ "GenMsgStartDelayTime" BO_ 256 110;
BA_ "NmMessage" BO_ 1092 1;
BA_ "GenMsgILSupport" BO_ 1092 0;
BA_ "NmMessage" BO_ 1108 1;
BA_ "GenMsgILSupport" BO_ 1108 0;
BA_ "NmMessage" BO_ 1088 1;
BA_ "GenMsgILSupport" BO_ 1088 0;
BA_ "NmMessage" BO_ 1091 1;
BA_ "GenMsgILSupport" BO_ 1091 0;
BA_ "NmMessage" BO_ 1105 1;
BA_ "GenMsgILSupport" BO_ 1105 0;
BA_ "NmMessage" BO_ 1100 1;
BA_ "GenMsgILSupport" BO_ 1100 0;
BA_ "NmMessage" BO_ 1098 1;
BA_ "GenMsgILSupport" BO_ 1098 0;
BA_ "NmMessage" BO_ 1099 1;
BA_ "GenMsgILSupport" BO_ 1099 0;
BA_ "NmMessage" BO_ 1095 1;
BA_ "GenMsgILSupport" BO_ 1095 0;
BA_ "NmMessage" BO_ 1107 1;
BA_ "GenMsgILSupport" BO_ 1107 0;
BA_ "NmMessage" BO_ 1093 1;
BA_ "GenMsgILSupport" BO_ 1093 0;
BA_ "NmMessage" BO_ 1109 1;
BA_ "GenMsgILSupport" BO_ 1109 0;
BA_ "NmMessage" BO_ 1106 1;
BA_ "GenMsgILSupport" BO_ 1106 0;
BA_ "NmMessage" BO_ 1096 1;
BA_ "GenMsgILSupport" BO_ 1096 0;
BA_ "NmMessage" BO_ 1103 1;
BA_ "GenMsgILSupport" BO_ 1103 0;
BA_ "NmMessage" BO_ 1110 1;
BA_ "GenMsgILSupport" BO_ 1110 0;
BA_ "NmMessage" BO_ 1102 1;
BA_ "GenMsgILSupport" BO_ 1102 0;
BA_ "NmMessage" BO_ 1101 1;
BA_ "GenMsgILSupport" BO_ 1101 0;
BA_ "NmMessage" BO_ 1097 1;
BA_ "GenMsgILSupport" BO_ 1097 0;
BA_ "NmMessage" BO_ 1094 1;
BA_ "GenMsgILSupport" BO_ 1094 0;
BA_ "NmMessage" BO_ 1089 1;
BA_ "GenMsgILSupport" BO_ 1089 0;
BA_ "NmMessage" BO_ 1104 1;
BA_ "GenMsgILSupport" BO_ 1104 0;
BA_ "NmMessage" BO_ 1090 1;
BA_ "GenMsgILSupport" BO_ 1090 0;
BA_ "GenSigSendType" SG_ 62 Navi_SLIF_SpdUnit 4;
BA_ "GenSigStartValue" SG_ 62 Navi_SLIF_SpdUnit 3;
BA_ "Gatewaysignal" SG_ 62 Navi_SLIF_SpdUnit 3;
BA_ "NmNetworkRequest" SG_ 62 Navi_SLIF_SpdUnit 1;
BA_ "TimeoutValue" SG_ 62 Navi_SLIF_SpdUnit "Old Value";
BA_ "GenSigSendType" SG_ 62 Navi_SLIF_Frwinfo 4;
BA_ "GenSigStartValue" SG_ 62 Navi_SLIF_Frwinfo 7;
BA_ "Gatewaysignal" SG_ 62 Navi_SLIF_Frwinfo 3;
BA_ "NmNetworkRequest" SG_ 62 Navi_SLIF_Frwinfo 1;
BA_ "GenSigSendType" SG_ 62 Navi_SLIF_LinkClass 4;
BA_ "GenSigStartValue" SG_ 62 Navi_SLIF_LinkClass 7;
BA_ "Gatewaysignal" SG_ 62 Navi_SLIF_LinkClass 3;
BA_ "NmNetworkRequest" SG_ 62 Navi_SLIF_LinkClass 1;
BA_ "GenSigSendType" SG_ 62 Navi_SLIF_SpdLimit 4;
BA_ "GenSigStartValue" SG_ 62 Navi_SLIF_SpdLimit 255;
BA_ "Gatewaysignal" SG_ 62 Navi_SLIF_SpdLimit 3;
BA_ "NmNetworkRequest" SG_ 62 Navi_SLIF_SpdLimit 1;
BA_ "TimeoutValue" SG_ 62 Navi_SLIF_SpdLimit "Old Value";
BA_ "GenSigSendType" SG_ 62 Navi_SLIFMapSource 4;
BA_ "GenSigStartValue" SG_ 62 Navi_SLIFMapSource 7;
BA_ "Gatewaysignal" SG_ 62 Navi_SLIFMapSource 3;
BA_ "NmNetworkRequest" SG_ 62 Navi_SLIFMapSource 1;
BA_ "GenSigSendType" SG_ 62 Navi_SLIF_CountryCode 4;
BA_ "GenSigStartValue" SG_ 62 Navi_SLIF_CountryCode 1023;
BA_ "Gatewaysignal" SG_ 62 Navi_SLIF_CountryCode 3;
BA_ "NmNetworkRequest" SG_ 62 Navi_SLIF_CountryCode 1;
BA_ "GenSigSendType" SG_ 52 HU_DATC_DrTempUpDn 4;
BA_ "GenSigStartValue" SG_ 52 HU_DATC_DrTempUpDn 3;
BA_ "Gatewaysignal" SG_ 52 HU_DATC_DrTempUpDn 3;
BA_ "NmNetworkRequest" SG_ 52 HU_DATC_DrTempUpDn 1;
BA_ "SignalCategory" SG_ 52 HU_DATC_DrTempUpDn 13;
BA_ "Validity" SG_ 52 HU_DATC_DrTempUpDn 2;
BA_ "GenSigSendType" SG_ 52 HU_DATC_PsTempUpDn 4;
BA_ "GenSigStartValue" SG_ 52 HU_DATC_PsTempUpDn 3;
BA_ "Gatewaysignal" SG_ 52 HU_DATC_PsTempUpDn 3;
BA_ "NmNetworkRequest" SG_ 52 HU_DATC_PsTempUpDn 1;
BA_ "Validity" SG_ 52 HU_DATC_PsTempUpDn 2;
BA_ "GenSigSendType" SG_ 52 HU_DATC_RlTempUpDn 4;
BA_ "GenSigStartValue" SG_ 52 HU_DATC_RlTempUpDn 3;
BA_ "Gatewaysignal" SG_ 52 HU_DATC_RlTempUpDn 3;
BA_ "NmNetworkRequest" SG_ 52 HU_DATC_RlTempUpDn 1;
BA_ "Validity" SG_ 52 HU_DATC_RlTempUpDn 2;
BA_ "GenSigSendType" SG_ 52 HU_DATC_RrTempUpDn 4;
BA_ "GenSigStartValue" SG_ 52 HU_DATC_RrTempUpDn 3;
BA_ "Gatewaysignal" SG_ 52 HU_DATC_RrTempUpDn 3;
BA_ "NmNetworkRequest" SG_ 52 HU_DATC_RrTempUpDn 1;
BA_ "Validity" SG_ 52 HU_DATC_RrTempUpDn 2;
BA_ "GenSigSendType" SG_ 52 HU_DATC_MainBlower 4;
BA_ "GenSigStartValue" SG_ 52 HU_DATC_MainBlower 15;
BA_ "Gatewaysignal" SG_ 52 HU_DATC_MainBlower 3;
BA_ "NmNetworkRequest" SG_ 52 HU_DATC_MainBlower 1;
BA_ "Validity" SG_ 52 HU_DATC_MainBlower 2;
BA_ "GenSigSendType" SG_ 52 HU_DATC_SubBlower 4;
BA_ "GenSigStartValue" SG_ 52 HU_DATC_SubBlower 15;
BA_ "Gatewaysignal" SG_ 52 HU_DATC_SubBlower 3;
BA_ "NmNetworkRequest" SG_ 52 HU_DATC_SubBlower 1;
BA_ "Validity" SG_ 52 HU_DATC_SubBlower 2;
BA_ "GenSigSendType" SG_ 52 HU_DATC_RearBlower 4;
BA_ "GenSigStartValue" SG_ 52 HU_DATC_RearBlower 15;
BA_ "Gatewaysignal" SG_ 52 HU_DATC_RearBlower 3;
BA_ "NmNetworkRequest" SG_ 52 HU_DATC_RearBlower 1;
BA_ "Validity" SG_ 52 HU_DATC_RearBlower 2;
BA_ "GenSigSendType" SG_ 52 HU_DATCRearPsModeSet 3;
BA_ "GenSigStartValue" SG_ 52 HU_DATCRearPsModeSet 15;
BA_ "Validity" SG_ 52 HU_DATCRearPsModeSet 2;
BA_ "GenSigSendType" SG_ 52 HU_DATC_FrontModeSet 4;
BA_ "GenSigStartValue" SG_ 52 HU_DATC_FrontModeSet 15;
BA_ "Gatewaysignal" SG_ 52 HU_DATC_FrontModeSet 3;
BA_ "NmNetworkRequest" SG_ 52 HU_DATC_FrontModeSet 1;
BA_ "Validity" SG_ 52 HU_DATC_FrontModeSet 2;
BA_ "GenSigSendType" SG_ 52 HU_DATC_RearModeSet 4;
BA_ "GenSigStartValue" SG_ 52 HU_DATC_RearModeSet 15;
BA_ "Gatewaysignal" SG_ 52 HU_DATC_RearModeSet 3;
BA_ "NmNetworkRequest" SG_ 52 HU_DATC_RearModeSet 1;
BA_ "Validity" SG_ 52 HU_DATC_RearModeSet 2;
BA_ "GenSigSendType" SG_ 52 HU_DATC_AutoSet 4;
BA_ "GenSigStartValue" SG_ 52 HU_DATC_AutoSet 3;
BA_ "Gatewaysignal" SG_ 52 HU_DATC_AutoSet 3;
BA_ "NmNetworkRequest" SG_ 52 HU_DATC_AutoSet 1;
BA_ "Validity" SG_ 52 HU_DATC_AutoSet 2;
BA_ "GenSigSendType" SG_ 52 HU_DATC_OffReq 4;
BA_ "GenSigStartValue" SG_ 52 HU_DATC_OffReq 3;
BA_ "Gatewaysignal" SG_ 52 HU_DATC_OffReq 3;
BA_ "NmNetworkRequest" SG_ 52 HU_DATC_OffReq 1;
BA_ "Validity" SG_ 52 HU_DATC_OffReq 2;
BA_ "GenSigSendType" SG_ 52 HU_DATC_IntakeSet 4;
BA_ "GenSigStartValue" SG_ 52 HU_DATC_IntakeSet 3;
BA_ "Gatewaysignal" SG_ 52 HU_DATC_IntakeSet 3;
BA_ "NmNetworkRequest" SG_ 52 HU_DATC_IntakeSet 1;
BA_ "Validity" SG_ 52 HU_DATC_IntakeSet 2;
BA_ "GenSigSendType" SG_ 52 HU_DATC_RearOnOffSet 4;
BA_ "GenSigStartValue" SG_ 52 HU_DATC_RearOnOffSet 3;
BA_ "Gatewaysignal" SG_ 52 HU_DATC_RearOnOffSet 3;
BA_ "NmNetworkRequest" SG_ 52 HU_DATC_RearOnOffSet 1;
BA_ "Validity" SG_ 52 HU_DATC_RearOnOffSet 2;
BA_ "GenSigSendType" SG_ 52 HU_DATC_AcSet 4;
BA_ "GenSigStartValue" SG_ 52 HU_DATC_AcSet 3;
BA_ "Gatewaysignal" SG_ 52 HU_DATC_AcSet 3;
BA_ "NmNetworkRequest" SG_ 52 HU_DATC_AcSet 1;
BA_ "Validity" SG_ 52 HU_DATC_AcSet 2;
BA_ "GenSigSendType" SG_ 52 HU_DATC_AqsSet 4;
BA_ "GenSigStartValue" SG_ 52 HU_DATC_AqsSet 3;
BA_ "Gatewaysignal" SG_ 52 HU_DATC_AqsSet 3;
BA_ "NmNetworkRequest" SG_ 52 HU_DATC_AqsSet 1;
BA_ "Validity" SG_ 52 HU_DATC_AqsSet 2;
BA_ "GenSigSendType" SG_ 52 HU_DATC_FrontDefog 4;
BA_ "GenSigStartValue" SG_ 52 HU_DATC_FrontDefog 3;
BA_ "Gatewaysignal" SG_ 52 HU_DATC_FrontDefog 3;
BA_ "NmNetworkRequest" SG_ 52 HU_DATC_FrontDefog 1;
BA_ "Validity" SG_ 52 HU_DATC_FrontDefog 2;
BA_ "GenSigSendType" SG_ 52 HU_DATC_RearDefog 4;
BA_ "GenSigStartValue" SG_ 52 HU_DATC_RearDefog 3;
BA_ "Gatewaysignal" SG_ 52 HU_DATC_RearDefog 3;
BA_ "NmNetworkRequest" SG_ 52 HU_DATC_RearDefog 1;
BA_ "Validity" SG_ 52 HU_DATC_RearDefog 2;
BA_ "GenSigSendType" SG_ 52 HU_DATC_ZoneControl 4;
BA_ "GenSigStartValue" SG_ 52 HU_DATC_ZoneControl 3;
BA_ "Gatewaysignal" SG_ 52 HU_DATC_ZoneControl 3;
BA_ "NmNetworkRequest" SG_ 52 HU_DATC_ZoneControl 1;
BA_ "Validity" SG_ 52 HU_DATC_ZoneControl 2;
BA_ "GenSigSendType" SG_ 52 HU_DATC_CO2Set 4;
BA_ "GenSigStartValue" SG_ 52 HU_DATC_CO2Set 3;
BA_ "Gatewaysignal" SG_ 52 HU_DATC_CO2Set 3;
BA_ "NmNetworkRequest" SG_ 52 HU_DATC_CO2Set 1;
BA_ "Validity" SG_ 52 HU_DATC_CO2Set 2;
BA_ "GenSigSendType" SG_ 52 DATC_SmartVentOnOffSet 4;
BA_ "GenSigStartValue" SG_ 52 DATC_SmartVentOnOffSet 3;
BA_ "Gatewaysignal" SG_ 52 DATC_SmartVentOnOffSet 3;
BA_ "NmNetworkRequest" SG_ 52 DATC_SmartVentOnOffSet 1;
BA_ "Validity" SG_ 52 DATC_SmartVentOnOffSet 2;
BA_ "GenSigSendType" SG_ 52 DATC_ADSOnOffSet 4;
BA_ "GenSigStartValue" SG_ 52 DATC_ADSOnOffSet 3;
BA_ "Gatewaysignal" SG_ 52 DATC_ADSOnOffSet 3;
BA_ "NmNetworkRequest" SG_ 52 DATC_ADSOnOffSet 1;
BA_ "Validity" SG_ 52 DATC_ADSOnOffSet 2;
BA_ "GenSigSendType" SG_ 52 HU_DATC_RearAutoDisp 3;
BA_ "GenSigStartValue" SG_ 52 HU_DATC_RearAutoDisp 3;
BA_ "Validity" SG_ 52 HU_DATC_RearAutoDisp 2;
BA_ "GenSigSendType" SG_ 52 HU_DATC_RearOffDisp 3;
BA_ "GenSigStartValue" SG_ 52 HU_DATC_RearOffDisp 3;
BA_ "Validity" SG_ 52 HU_DATC_RearOffDisp 2;
BA_ "GenSigSendType" SG_ 308 DATC_PwrInfo 4;
BA_ "NmNetworkRequest" SG_ 308 DATC_PwrInfo 1;
BA_ "NmNetworkRequestHoldingTime" SG_ 308 DATC_PwrInfo 5;
BA_ "Validity" SG_ 308 DATC_PwrInfo 2;
BA_ "GenSigSendType" SG_ 308 DATC_AltL 4;
BA_ "NmNetworkRequest" SG_ 308 DATC_AltL 1;
BA_ "NmNetworkRequestHoldingTime" SG_ 308 DATC_AltL 5;
BA_ "Validity" SG_ 308 DATC_AltL 2;
BA_ "GenSigSendType" SG_ 308 DATC_CarInfo 4;
BA_ "NmNetworkRequest" SG_ 308 DATC_CarInfo 1;
BA_ "NmNetworkRequestHoldingTime" SG_ 308 DATC_CarInfo 5;
BA_ "TimeoutValue" SG_ 308 DATC_CarInfo "0x0";
BA_ "Validity" SG_ 308 DATC_CarInfo 2;
BA_ "GenSigSendType" SG_ 308 DATC_ParkingBrake 4;
BA_ "NmNetworkRequest" SG_ 308 DATC_ParkingBrake 1;
BA_ "NmNetworkRequestHoldingTime" SG_ 308 DATC_ParkingBrake 5;
BA_ "TimeoutValue" SG_ 308 DATC_ParkingBrake "0x0";
BA_ "Validity" SG_ 308 DATC_ParkingBrake 2;
BA_ "GenSigSendType" SG_ 308 DATC_LowFuelWarn 4;
BA_ "NmNetworkRequest" SG_ 308 DATC_LowFuelWarn 1;
BA_ "NmNetworkRequestHoldingTime" SG_ 308 DATC_LowFuelWarn 5;
BA_ "TimeoutValue" SG_ 308 DATC_LowFuelWarn "0x0";
BA_ "Validity" SG_ 308 DATC_LowFuelWarn 2;
BA_ "GenSigSendType" SG_ 308 DATC_Rear_Off_Disp 4;
BA_ "GenSigStartValue" SG_ 308 DATC_Rear_Off_Disp 3;
BA_ "NmNetworkRequest" SG_ 308 DATC_Rear_Off_Disp 1;
BA_ "Validity" SG_ 308 DATC_Rear_Off_Disp 2;
BA_ "GenSigSendType" SG_ 308 DATC_Rear_AutoDisp 4;
BA_ "GenSigStartValue" SG_ 308 DATC_Rear_AutoDisp 3;
BA_ "NmNetworkRequest" SG_ 308 DATC_Rear_AutoDisp 1;
BA_ "Validity" SG_ 308 DATC_Rear_AutoDisp 2;
BA_ "GenSigSendType" SG_ 308 DATC_Rear_BlowerDisp 4;
BA_ "GenSigStartValue" SG_ 308 DATC_Rear_BlowerDisp 3;
BA_ "NmNetworkRequest" SG_ 308 DATC_Rear_BlowerDisp 1;
BA_ "Validity" SG_ 308 DATC_Rear_BlowerDisp 2;
BA_ "GenSigSendType" SG_ 308 DATC_DrSeatWarmerDisp 4;
BA_ "GenSigStartValue" SG_ 308 DATC_DrSeatWarmerDisp 7;
BA_ "NmNetworkRequest" SG_ 308 DATC_DrSeatWarmerDisp 1;
BA_ "SignalCategory" SG_ 308 DATC_DrSeatWarmerDisp 13;
BA_ "Validity" SG_ 308 DATC_DrSeatWarmerDisp 2;
BA_ "GenSigSendType" SG_ 308 DATC_SyncDisp 4;
BA_ "NmNetworkRequest" SG_ 308 DATC_SyncDisp 1;
BA_ "TimeoutValue" SG_ 308 DATC_SyncDisp "0xf";
BA_ "Validity" SG_ 308 DATC_SyncDisp 2;
BA_ "GenSigSendType" SG_ 308 DATC_RearDispCtrl 4;
BA_ "NmNetworkRequest" SG_ 308 DATC_RearDispCtrl 1;
BA_ "TimeoutValue" SG_ 308 DATC_RearDispCtrl "0xf";
BA_ "Validity" SG_ 308 DATC_RearDispCtrl 2;
BA_ "GenSigSendType" SG_ 308 DATC_RearDrModeDisp 4;
BA_ "GenSigStartValue" SG_ 308 DATC_RearDrModeDisp 15;
BA_ "NmNetworkRequest" SG_ 308 DATC_RearDrModeDisp 1;
BA_ "TimeoutValue" SG_ 308 DATC_RearDrModeDisp "Old Value";
BA_ "Validity" SG_ 308 DATC_RearDrModeDisp 2;
BA_ "GenSigSendType" SG_ 308 DATC_PsSeatWarmerDisp 4;
BA_ "GenSigStartValue" SG_ 308 DATC_PsSeatWarmerDisp 7;
BA_ "NmNetworkRequest" SG_ 308 DATC_PsSeatWarmerDisp 1;
BA_ "SignalCategory" SG_ 308 DATC_PsSeatWarmerDisp 13;
BA_ "Validity" SG_ 308 DATC_PsSeatWarmerDisp 2;
BA_ "GenSigSendType" SG_ 308 DATC_DrVentSeatDisp 4;
BA_ "GenSigStartValue" SG_ 308 DATC_DrVentSeatDisp 7;
BA_ "NmNetworkRequest" SG_ 308 DATC_DrVentSeatDisp 1;
BA_ "SignalCategory" SG_ 308 DATC_DrVentSeatDisp 13;
BA_ "Validity" SG_ 308 DATC_DrVentSeatDisp 2;
BA_ "GenSigSendType" SG_ 308 DATC_PSVentSeatDisp 4;
BA_ "GenSigStartValue" SG_ 308 DATC_PSVentSeatDisp 7;
BA_ "NmNetworkRequest" SG_ 308 DATC_PSVentSeatDisp 1;
BA_ "SignalCategory" SG_ 308 DATC_PSVentSeatDisp 13;
BA_ "Validity" SG_ 308 DATC_PSVentSeatDisp 2;
BA_ "GenSigSendType" SG_ 308 DATC_RrDefLed 4;
BA_ "GenSigStartValue" SG_ 308 DATC_RrDefLed 3;
BA_ "NmNetworkRequest" SG_ 308 DATC_RrDefLed 1;
BA_ "SignalCategory" SG_ 308 DATC_RrDefLed 13;
BA_ "Validity" SG_ 308 DATC_RrDefLed 2;
BA_ "GenSigSendType" SG_ 308 DATC_SmartVentOnOffStatus 4;
BA_ "GenSigStartValue" SG_ 308 DATC_SmartVentOnOffStatus 3;
BA_ "Gatewaysignal" SG_ 308 DATC_SmartVentOnOffStatus 4;
BA_ "NmNetworkRequest" SG_ 308 DATC_SmartVentOnOffStatus 1;
BA_ "TimeoutValue" SG_ 308 DATC_SmartVentOnOffStatus "Old Value";
BA_ "Validity" SG_ 308 DATC_SmartVentOnOffStatus 2;
BA_ "GenSigSendType" SG_ 308 DATC_ADSOnOffStatus 4;
BA_ "GenSigStartValue" SG_ 308 DATC_ADSOnOffStatus 3;
BA_ "Gatewaysignal" SG_ 308 DATC_ADSOnOffStatus 4;
BA_ "NmNetworkRequest" SG_ 308 DATC_ADSOnOffStatus 1;
BA_ "TimeoutValue" SG_ 308 DATC_ADSOnOffStatus "Old Value";
BA_ "Validity" SG_ 308 DATC_ADSOnOffStatus 2;
BA_ "GenSigSendType" SG_ 308 DATC_AcDisp_OSD 3;
BA_ "GenSigStartValue" SG_ 308 DATC_AcDisp_OSD 3;
BA_ "Validity" SG_ 308 DATC_AcDisp_OSD 2;
BA_ "GenSigSendType" SG_ 308 DATC_PsModeDisp_OSD 3;
BA_ "GenSigStartValue" SG_ 308 DATC_PsModeDisp_OSD 15;
BA_ "Validity" SG_ 308 DATC_PsModeDisp_OSD 2;
BA_ "GenSigSendType" SG_ 308 DATC_ModeDisp_OSD 3;
BA_ "GenSigStartValue" SG_ 308 DATC_ModeDisp_OSD 15;
BA_ "Validity" SG_ 308 DATC_ModeDisp_OSD 2;
BA_ "GenSigSendType" SG_ 307 DATC_DiagMode 4;
BA_ "GenSigStartValue" SG_ 307 DATC_DiagMode 3;
BA_ "NmNetworkRequest" SG_ 307 DATC_DiagMode 1;
BA_ "TimeoutValue" SG_ 307 DATC_DiagMode "Old Value";
BA_ "Validity" SG_ 307 DATC_DiagMode 2;
BA_ "GenSigSendType" SG_ 307 DATC_Rear_ChangeReqDisp 4;
BA_ "GenSigStartValue" SG_ 307 DATC_Rear_ChangeReqDisp 3;
BA_ "NmNetworkRequest" SG_ 307 DATC_Rear_ChangeReqDisp 1;
BA_ "TimeoutValue" SG_ 307 DATC_Rear_ChangeReqDisp "Old Value";
BA_ "Validity" SG_ 307 DATC_Rear_ChangeReqDisp 2;
BA_ "GenSigSendType" SG_ 307 DATC_Rear_ClimateScnDisp 4;
BA_ "GenSigStartValue" SG_ 307 DATC_Rear_ClimateScnDisp 3;
BA_ "NmNetworkRequest" SG_ 307 DATC_Rear_ClimateScnDisp 1;
BA_ "TimeoutValue" SG_ 307 DATC_Rear_ClimateScnDisp "Old Value";
BA_ "Validity" SG_ 307 DATC_Rear_ClimateScnDisp 2;
BA_ "GenSigSendType" SG_ 307 DATC_CO2OnOffStatus 3;
BA_ "GenSigStartValue" SG_ 307 DATC_CO2OnOffStatus 3;
BA_ "TimeoutValue" SG_ 307 DATC_CO2OnOffStatus "Old value";
BA_ "Validity" SG_ 307 DATC_CO2OnOffStatus 2;
BA_ "GenSigSendType" SG_ 307 DATC_SelfDiagDisp 4;
BA_ "GenSigStartValue" SG_ 307 DATC_SelfDiagDisp 255;
BA_ "NmNetworkRequest" SG_ 307 DATC_SelfDiagDisp 1;
BA_ "TimeoutValue" SG_ 307 DATC_SelfDiagDisp "Old Value";
BA_ "Validity" SG_ 307 DATC_SelfDiagDisp 2;
BA_ "GenSigSendType" SG_ 307 DATC_RearBlwDisp_OSD 3;
BA_ "GenSigStartValue" SG_ 307 DATC_RearBlwDisp_OSD 15;
BA_ "Validity" SG_ 307 DATC_RearBlwDisp_OSD 2;
BA_ "GenSigSendType" SG_ 307 DATC_AqsLevelOut 4;
BA_ "GenSigStartValue" SG_ 307 DATC_AqsLevelOut 15;
BA_ "NmNetworkRequest" SG_ 307 DATC_AqsLevelOut 1;
BA_ "TimeoutValue" SG_ 307 DATC_AqsLevelOut "Old Value";
BA_ "Validity" SG_ 307 DATC_AqsLevelOut 2;
BA_ "GenSigSendType" SG_ 307 DATC_RearModeDisp 3;
BA_ "GenSigStartValue" SG_ 307 DATC_RearModeDisp 15;
BA_ "TimeoutValue" SG_ 307 DATC_RearModeDisp "Old value";
BA_ "Validity" SG_ 307 DATC_RearModeDisp 2;
BA_ "GenSigSendType" SG_ 307 DATC_RearPsModeDisp 3;
BA_ "GenSigStartValue" SG_ 307 DATC_RearPsModeDisp 15;
BA_ "TimeoutValue" SG_ 307 DATC_RearPsModeDisp "Old Value";
BA_ "Validity" SG_ 307 DATC_RearPsModeDisp 2;
BA_ "GenSigSendType" SG_ 307 DATC_FrontBlwDisp_Ps 3;
BA_ "GenSigStartValue" SG_ 307 DATC_FrontBlwDisp_Ps 15;
BA_ "TimeoutValue" SG_ 307 DATC_FrontBlwDisp_Ps "Old Value";
BA_ "Validity" SG_ 307 DATC_FrontBlwDisp_Ps 2;
BA_ "GenSigSendType" SG_ 307 DATC_AutoDisp_Ps 3;
BA_ "GenSigStartValue" SG_ 307 DATC_AutoDisp_Ps 3;
BA_ "TimeoutValue" SG_ 307 DATC_AutoDisp_Ps "Old value";
BA_ "Validity" SG_ 307 DATC_AutoDisp_Ps 2;
BA_ "GenSigSendType" SG_ 307 DATC_RearModeDisp_OSD 3;
BA_ "GenSigStartValue" SG_ 307 DATC_RearModeDisp_OSD 15;
BA_ "TimeoutValue" SG_ 307 DATC_RearModeDisp_OSD "Old value";
BA_ "Validity" SG_ 307 DATC_RearModeDisp_OSD 2;
BA_ "GenSigSendType" SG_ 307 DATC_RearPSModeDisp_OSD 3;
BA_ "GenSigStartValue" SG_ 307 DATC_RearPSModeDisp_OSD 15;
BA_ "TimeoutValue" SG_ 307 DATC_RearPSModeDisp_OSD "Old value";
BA_ "Validity" SG_ 307 DATC_RearPSModeDisp_OSD 2;
BA_ "GenSigSendType" SG_ 307 DATC_FrontBlwDisp_OSD 3;
BA_ "GenSigStartValue" SG_ 307 DATC_FrontBlwDisp_OSD 15;
BA_ "TimeoutValue" SG_ 307 DATC_FrontBlwDisp_OSD "Old Value";
BA_ "Validity" SG_ 307 DATC_FrontBlwDisp_OSD 2;
BA_ "GenSigSendType" SG_ 307 DATC_FrontBlwDispPs_OSD 3;
BA_ "GenSigStartValue" SG_ 307 DATC_FrontBlwDispPs_OSD 15;
BA_ "Validity" SG_ 307 DATC_FrontBlwDispPs_OSD 2;
BA_ "GenSigSendType" SG_ 307 DATC_Variant 4;
BA_ "GenSigStartValue" SG_ 307 DATC_Variant 255;
BA_ "NmNetworkRequest" SG_ 307 DATC_Variant 1;
BA_ "TimeoutValue" SG_ 307 DATC_Variant "Old Value";
BA_ "Validity" SG_ 307 DATC_Variant 2;
BA_ "GenSigSendType" SG_ 306 DATC_ModeDisp 4;
BA_ "GenSigStartValue" SG_ 306 DATC_ModeDisp 15;
BA_ "NmNetworkRequest" SG_ 306 DATC_ModeDisp 1;
BA_ "TimeoutValue" SG_ 306 DATC_ModeDisp "Old Value";
BA_ "Validity" SG_ 306 DATC_ModeDisp 2;
BA_ "GenSigSendType" SG_ 306 DATC_TempUnit 4;
BA_ "GenSigStartValue" SG_ 306 DATC_TempUnit 3;
BA_ "NmNetworkRequest" SG_ 306 DATC_TempUnit 1;
BA_ "TimeoutValue" SG_ 306 DATC_TempUnit "Old Value";
BA_ "Validity" SG_ 306 DATC_TempUnit 2;
BA_ "GenSigSendType" SG_ 306 DATC_AutoDisp 4;
BA_ "GenSigStartValue" SG_ 306 DATC_AutoDisp 3;
BA_ "NmNetworkRequest" SG_ 306 DATC_AutoDisp 1;
BA_ "TimeoutValue" SG_ 306 DATC_AutoDisp "Old Value";
BA_ "Validity" SG_ 306 DATC_AutoDisp 2;
BA_ "GenSigSendType" SG_ 306 DATC_IntakeDisp 4;
BA_ "GenSigStartValue" SG_ 306 DATC_IntakeDisp 3;
BA_ "NmNetworkRequest" SG_ 306 DATC_IntakeDisp 1;
BA_ "TimeoutValue" SG_ 306 DATC_IntakeDisp "Old Value";
BA_ "Validity" SG_ 306 DATC_IntakeDisp 2;
BA_ "GenSigSendType" SG_ 306 DATC_ChangeReqDisp 4;
BA_ "GenSigStartValue" SG_ 306 DATC_ChangeReqDisp 3;
BA_ "NmNetworkRequest" SG_ 306 DATC_ChangeReqDisp 1;
BA_ "TimeoutValue" SG_ 306 DATC_ChangeReqDisp "Old Value";
BA_ "Validity" SG_ 306 DATC_ChangeReqDisp 2;
BA_ "GenSigSendType" SG_ 306 DATC_AcDisp 4;
BA_ "GenSigStartValue" SG_ 306 DATC_AcDisp 3;
BA_ "NmNetworkRequest" SG_ 306 DATC_AcDisp 1;
BA_ "TimeoutValue" SG_ 306 DATC_AcDisp "Old Value";
BA_ "Validity" SG_ 306 DATC_AcDisp 2;
BA_ "GenSigSendType" SG_ 306 DATC_AqsDisp 4;
BA_ "GenSigStartValue" SG_ 306 DATC_AqsDisp 3;
BA_ "NmNetworkRequest" SG_ 306 DATC_AqsDisp 1;
BA_ "TimeoutValue" SG_ 306 DATC_AqsDisp "Old Value";
BA_ "Validity" SG_ 306 DATC_AqsDisp 2;
BA_ "GenSigSendType" SG_ 306 DATC_ClimateScnDisp 4;
BA_ "GenSigStartValue" SG_ 306 DATC_ClimateScnDisp 3;
BA_ "Gatewaysignal" SG_ 306 DATC_ClimateScnDisp 4;
BA_ "NmNetworkRequest" SG_ 306 DATC_ClimateScnDisp 1;
BA_ "TimeoutValue" SG_ 306 DATC_ClimateScnDisp "Old Value";
BA_ "Validity" SG_ 306 DATC_ClimateScnDisp 2;
BA_ "GenSigSendType" SG_ 306 DATC_DualDisp 4;
BA_ "GenSigStartValue" SG_ 306 DATC_DualDisp 3;
BA_ "NmNetworkRequest" SG_ 306 DATC_DualDisp 1;
BA_ "TimeoutValue" SG_ 306 DATC_DualDisp "Old Value";
BA_ "Validity" SG_ 306 DATC_DualDisp 2;
BA_ "GenSigSendType" SG_ 306 DATC_OffDisp 4;
BA_ "GenSigStartValue" SG_ 306 DATC_OffDisp 3;
BA_ "NmNetworkRequest" SG_ 306 DATC_OffDisp 1;
BA_ "TimeoutValue" SG_ 306 DATC_OffDisp "Old Value";
BA_ "Validity" SG_ 306 DATC_OffDisp 2;
BA_ "GenSigSendType" SG_ 306 DATC_OpSts 4;
BA_ "GenSigStartValue" SG_ 306 DATC_OpSts 7;
BA_ "NmNetworkRequest" SG_ 306 DATC_OpSts 1;
BA_ "TimeoutValue" SG_ 306 DATC_OpSts "Old Value";
BA_ "Validity" SG_ 306 DATC_OpSts 2;
BA_ "GenSigSendType" SG_ 306 DATC_RearManual 4;
BA_ "GenSigStartValue" SG_ 306 DATC_RearManual 3;
BA_ "NmNetworkRequest" SG_ 306 DATC_RearManual 1;
BA_ "SignalCategory" SG_ 306 DATC_RearManual 13;
BA_ "TimeoutValue" SG_ 306 DATC_RearManual "Old";
BA_ "Validity" SG_ 306 DATC_RearManual 2;
BA_ "GenSigSendType" SG_ 306 DATC_FrDefLed 3;
BA_ "GenSigStartValue" SG_ 306 DATC_FrDefLed 3;
BA_ "TimeoutValue" SG_ 306 DATC_FrDefLed "Old Value";
BA_ "Validity" SG_ 306 DATC_FrDefLed 2;
BA_ "GenSigSendType" SG_ 306 DATC_SmartVentDisp 4;
BA_ "GenSigStartValue" SG_ 306 DATC_SmartVentDisp 3;
BA_ "Gatewaysignal" SG_ 306 DATC_SmartVentDisp 4;
BA_ "NmNetworkRequest" SG_ 306 DATC_SmartVentDisp 1;
BA_ "TimeoutValue" SG_ 306 DATC_SmartVentDisp "Old Value";
BA_ "Validity" SG_ 306 DATC_SmartVentDisp 2;
BA_ "GenSigSendType" SG_ 306 DATC_AutoDefogBlink 4;
BA_ "GenSigStartValue" SG_ 306 DATC_AutoDefogBlink 3;
BA_ "NmNetworkRequest" SG_ 306 DATC_AutoDefogBlink 1;
BA_ "SignalCategory" SG_ 306 DATC_AutoDefogBlink 13;
BA_ "TimeoutValue" SG_ 306 DATC_AutoDefogBlink "Old Value";
BA_ "Validity" SG_ 306 DATC_AutoDefogBlink 2;
BA_ "GenSigSendType" SG_ 306 DATC_ADSDisp 4;
BA_ "GenSigStartValue" SG_ 306 DATC_ADSDisp 3;
BA_ "Gatewaysignal" SG_ 306 DATC_ADSDisp 4;
BA_ "NmNetworkRequest" SG_ 306 DATC_ADSDisp 1;
BA_ "TimeoutValue" SG_ 306 DATC_ADSDisp "Old Value";
BA_ "Validity" SG_ 306 DATC_ADSDisp 2;
BA_ "GenSigSendType" SG_ 306 DATC_IonClean 4;
BA_ "GenSigStartValue" SG_ 306 DATC_IonClean 3;
BA_ "NmNetworkRequest" SG_ 306 DATC_IonClean 1;
BA_ "TimeoutValue" SG_ 306 DATC_IonClean "Old Value";
BA_ "Validity" SG_ 306 DATC_IonClean 2;
BA_ "GenSigSendType" SG_ 306 DATC_CO2Warning 4;
BA_ "GenSigStartValue" SG_ 306 DATC_CO2Warning 3;
BA_ "NmNetworkRequest" SG_ 306 DATC_CO2Warning 1;
BA_ "TimeoutValue" SG_ 306 DATC_CO2Warning "Old Value";
BA_ "Validity" SG_ 306 DATC_CO2Warning 2;
BA_ "GenSigSendType" SG_ 306 DATC_SubBlowerDisp 4;
BA_ "GenSigStartValue" SG_ 306 DATC_SubBlowerDisp 15;
BA_ "NmNetworkRequest" SG_ 306 DATC_SubBlowerDisp 1;
BA_ "SignalCategory" SG_ 306 DATC_SubBlowerDisp 13;
BA_ "TimeoutValue" SG_ 306 DATC_SubBlowerDisp "Old";
BA_ "Validity" SG_ 306 DATC_SubBlowerDisp 2;
BA_ "GenSigSendType" SG_ 306 DATC_BeepReq 4;
BA_ "NmNetworkRequest" SG_ 306 DATC_BeepReq 1;
BA_ "SignalCategory" SG_ 306 DATC_BeepReq 13;
BA_ "TimeoutValue" SG_ 306 DATC_BeepReq "Old";
BA_ "Validity" SG_ 306 DATC_BeepReq 2;
BA_ "GenSigSendType" SG_ 306 DATC_MainBlowerDisp 4;
BA_ "GenSigStartValue" SG_ 306 DATC_MainBlowerDisp 15;
BA_ "NmNetworkRequest" SG_ 306 DATC_MainBlowerDisp 1;
BA_ "TimeoutValue" SG_ 306 DATC_MainBlowerDisp "Old Value";
BA_ "Validity" SG_ 306 DATC_MainBlowerDisp 2;
BA_ "GenSigSendType" SG_ 306 DATC_PsModeDisp 4;
BA_ "GenSigStartValue" SG_ 306 DATC_PsModeDisp 15;
BA_ "NmNetworkRequest" SG_ 306 DATC_PsModeDisp 1;
BA_ "TimeoutValue" SG_ 306 DATC_PsModeDisp "Old Value";
BA_ "Validity" SG_ 306 DATC_PsModeDisp 2;
BA_ "GenSigStartValue" SG_ 1329 DATC_AmbientTemp_C 255;
BA_ "TimeoutValue" SG_ 1329 DATC_AmbientTemp_C "Old Value";
BA_ "Validity" SG_ 1329 DATC_AmbientTemp_C 2;
BA_ "GenSigStartValue" SG_ 1329 DATC_AmbientTemp_F 255;
BA_ "TimeoutValue" SG_ 1329 DATC_AmbientTemp_F "Old Value";
BA_ "Validity" SG_ 1329 DATC_AmbientTemp_F 2;
BA_ "GenSigSendType" SG_ 305 DATC_DrTempDispC 4;
BA_ "GenSigStartValue" SG_ 305 DATC_DrTempDispC 255;
BA_ "Gatewaysignal" SG_ 305 DATC_DrTempDispC 4;
BA_ "NmNetworkRequest" SG_ 305 DATC_DrTempDispC 1;
BA_ "TimeoutValue" SG_ 305 DATC_DrTempDispC "Old Value";
BA_ "Validity" SG_ 305 DATC_DrTempDispC 2;
BA_ "GenSigSendType" SG_ 305 DATC_Rear_DrTempDispC 4;
BA_ "GenSigStartValue" SG_ 305 DATC_Rear_DrTempDispC 255;
BA_ "Gatewaysignal" SG_ 305 DATC_Rear_DrTempDispC 4;
BA_ "NmNetworkRequest" SG_ 305 DATC_Rear_DrTempDispC 1;
BA_ "TimeoutValue" SG_ 305 DATC_Rear_DrTempDispC "Old Value";
BA_ "Validity" SG_ 305 DATC_Rear_DrTempDispC 2;
BA_ "GenSigSendType" SG_ 305 DATC_DrTempDispF 4;
BA_ "GenSigStartValue" SG_ 305 DATC_DrTempDispF 255;
BA_ "Gatewaysignal" SG_ 305 DATC_DrTempDispF 4;
BA_ "NmNetworkRequest" SG_ 305 DATC_DrTempDispF 1;
BA_ "TimeoutValue" SG_ 305 DATC_DrTempDispF "Old Value";
BA_ "Validity" SG_ 305 DATC_DrTempDispF 2;
BA_ "GenSigSendType" SG_ 305 DATC_Rear_DrTempDispF 4;
BA_ "GenSigStartValue" SG_ 305 DATC_Rear_DrTempDispF 255;
BA_ "Gatewaysignal" SG_ 305 DATC_Rear_DrTempDispF 4;
BA_ "NmNetworkRequest" SG_ 305 DATC_Rear_DrTempDispF 1;
BA_ "TimeoutValue" SG_ 305 DATC_Rear_DrTempDispF "Old Value";
BA_ "Validity" SG_ 305 DATC_Rear_DrTempDispF 2;
BA_ "GenSigSendType" SG_ 305 DATC_PsTempDispC 4;
BA_ "GenSigStartValue" SG_ 305 DATC_PsTempDispC 255;
BA_ "Gatewaysignal" SG_ 305 DATC_PsTempDispC 4;
BA_ "NmNetworkRequest" SG_ 305 DATC_PsTempDispC 1;
BA_ "TimeoutValue" SG_ 305 DATC_PsTempDispC "Old Value";
BA_ "Validity" SG_ 305 DATC_PsTempDispC 2;
BA_ "GenSigSendType" SG_ 305 Datc_RearPsTempDispC 3;
BA_ "GenSigStartValue" SG_ 305 Datc_RearPsTempDispC 255;
BA_ "Gatewaysignal" SG_ 305 Datc_RearPsTempDispC 4;
BA_ "SignalCategory" SG_ 305 Datc_RearPsTempDispC 13;
BA_ "TimeoutValue" SG_ 305 Datc_RearPsTempDispC "Old Value";
BA_ "Validity" SG_ 305 Datc_RearPsTempDispC 2;
BA_ "GenSigSendType" SG_ 305 DATC_PsTempDispF 4;
BA_ "GenSigStartValue" SG_ 305 DATC_PsTempDispF 255;
BA_ "Gatewaysignal" SG_ 305 DATC_PsTempDispF 4;
BA_ "NmNetworkRequest" SG_ 305 DATC_PsTempDispF 1;
BA_ "TimeoutValue" SG_ 305 DATC_PsTempDispF "Old Value";
BA_ "Validity" SG_ 305 DATC_PsTempDispF 2;
BA_ "GenSigSendType" SG_ 305 DATC_RearPsTempDispF 3;
BA_ "GenSigStartValue" SG_ 305 DATC_RearPsTempDispF 255;
BA_ "Gatewaysignal" SG_ 305 DATC_RearPsTempDispF 4;
BA_ "TimeoutValue" SG_ 305 DATC_RearPsTempDispF "Old value";
BA_ "Validity" SG_ 305 DATC_RearPsTempDispF 2;
BA_ "GenSigSendType" SG_ 304 DATC_Type 4;
BA_ "GenSigStartValue" SG_ 304 DATC_Type 255;
BA_ "NmNetworkRequest" SG_ 304 DATC_Type 1;
BA_ "SignalCategory" SG_ 304 DATC_Type 13;
BA_ "TimeoutValue" SG_ 304 DATC_Type "OldValue";
BA_ "Validity" SG_ 304 DATC_Type 2;
BA_ "GenSigSendType" SG_ 304 DATC_VerMMMajor 4;
BA_ "GenSigStartValue" SG_ 304 DATC_VerMMMajor 255;
BA_ "NmNetworkRequest" SG_ 304 DATC_VerMMMajor 1;
BA_ "SignalCategory" SG_ 304 DATC_VerMMMajor 13;
BA_ "TimeoutValue" SG_ 304 DATC_VerMMMajor "OldValue";
BA_ "Validity" SG_ 304 DATC_VerMMMajor 2;
BA_ "GenSigSendType" SG_ 304 DATC_VerMMMinor 4;
BA_ "GenSigStartValue" SG_ 304 DATC_VerMMMinor 255;
BA_ "NmNetworkRequest" SG_ 304 DATC_VerMMMinor 1;
BA_ "SignalCategory" SG_ 304 DATC_VerMMMinor 13;
BA_ "TimeoutValue" SG_ 304 DATC_VerMMMinor "OldValue";
BA_ "Validity" SG_ 304 DATC_VerMMMinor 2;
BA_ "GenSigSendType" SG_ 304 DATC_VerBDFMajor 4;
BA_ "GenSigStartValue" SG_ 304 DATC_VerBDFMajor 255;
BA_ "NmNetworkRequest" SG_ 304 DATC_VerBDFMajor 1;
BA_ "SignalCategory" SG_ 304 DATC_VerBDFMajor 13;
BA_ "TimeoutValue" SG_ 304 DATC_VerBDFMajor "OldValue";
BA_ "Validity" SG_ 304 DATC_VerBDFMajor 2;
BA_ "GenSigSendType" SG_ 304 DATC_VerBDMinor 4;
BA_ "GenSigStartValue" SG_ 304 DATC_VerBDMinor 255;
BA_ "NmNetworkRequest" SG_ 304 DATC_VerBDMinor 1;
BA_ "SignalCategory" SG_ 304 DATC_VerBDMinor 13;
BA_ "TimeoutValue" SG_ 304 DATC_VerBDMinor "OldValue";
BA_ "Validity" SG_ 304 DATC_VerBDMinor 2;
BA_ "GenSigSendType" SG_ 304 DATC_VerCSMajor 4;
BA_ "GenSigStartValue" SG_ 304 DATC_VerCSMajor 255;
BA_ "NmNetworkRequest" SG_ 304 DATC_VerCSMajor 1;
BA_ "SignalCategory" SG_ 304 DATC_VerCSMajor 13;
BA_ "TimeoutValue" SG_ 304 DATC_VerCSMajor "OldValue";
BA_ "Validity" SG_ 304 DATC_VerCSMajor 2;
BA_ "GenSigSendType" SG_ 304 DATC_VerCSMinor 4;
BA_ "GenSigStartValue" SG_ 304 DATC_VerCSMinor 255;
BA_ "NmNetworkRequest" SG_ 304 DATC_VerCSMinor 1;
BA_ "SignalCategory" SG_ 304 DATC_VerCSMinor 13;
BA_ "TimeoutValue" SG_ 304 DATC_VerCSMinor "OldValue";
BA_ "Validity" SG_ 304 DATC_VerCSMinor 2;
BA_ "GenSigSendType" SG_ 291 NV_DS_Curve 4;
BA_ "GenSigStartValue" SG_ 291 NV_DS_Curve 15;
BA_ "NmNetworkRequest" SG_ 291 NV_DS_Curve 1;
BA_ "GenSigSendType" SG_ 291 NV_DS_Merge 4;
BA_ "GenSigStartValue" SG_ 291 NV_DS_Merge 15;
BA_ "NmNetworkRequest" SG_ 291 NV_DS_Merge 1;
BA_ "GenSigSendType" SG_ 291 NV_DS_RailCross 4;
BA_ "GenSigStartValue" SG_ 291 NV_DS_RailCross 3;
BA_ "NmNetworkRequest" SG_ 291 NV_DS_RailCross 1;
BA_ "GenSigSendType" SG_ 291 NV_DS_FallingRocks 4;
BA_ "GenSigStartValue" SG_ 291 NV_DS_FallingRocks 3;
BA_ "NmNetworkRequest" SG_ 291 NV_DS_FallingRocks 1;
BA_ "GenSigSendType" SG_ 291 NV_DS_SchoolZone 4;
BA_ "GenSigStartValue" SG_ 291 NV_DS_SchoolZone 3;
BA_ "NmNetworkRequest" SG_ 291 NV_DS_SchoolZone 1;
BA_ "GenSigSendType" SG_ 291 NV_DS_AccidentBlack 4;
BA_ "GenSigStartValue" SG_ 291 NV_DS_AccidentBlack 3;
BA_ "NmNetworkRequest" SG_ 291 NV_DS_AccidentBlack 1;
BA_ "GenSigSendType" SG_ 291 NV_DS_SpeedBump 4;
BA_ "GenSigStartValue" SG_ 291 NV_DS_SpeedBump 3;
BA_ "NmNetworkRequest" SG_ 291 NV_DS_SpeedBump 1;
BA_ "GenSigSendType" SG_ 291 NV_DS_RoadKill 4;
BA_ "GenSigStartValue" SG_ 291 NV_DS_RoadKill 3;
BA_ "NmNetworkRequest" SG_ 291 NV_DS_RoadKill 1;
BA_ "GenSigSendType" SG_ 291 NV_DS_Downhill 4;
BA_ "GenSigStartValue" SG_ 291 NV_DS_Downhill 3;
BA_ "NmNetworkRequest" SG_ 291 NV_DS_Downhill 1;
BA_ "GenSigSendType" SG_ 291 NV_DS_Fog 4;
BA_ "GenSigStartValue" SG_ 291 NV_DS_Fog 3;
BA_ "NmNetworkRequest" SG_ 291 NV_DS_Fog 1;
BA_ "GenSigSendType" SG_ 291 NV_Display_TG 4;
BA_ "GenSigStartValue" SG_ 291 NV_Display_TG 3;
BA_ "NmNetworkRequest" SG_ 291 NV_Display_TG 1;
BA_ "GenSigSendType" SG_ 291 NV_Charge 4;
BA_ "GenSigStartValue" SG_ 291 NV_Charge 65535;
BA_ "NmNetworkRequest" SG_ 291 NV_Charge 1;
BA_ "GenSigSendType" SG_ 291 NV_Charge_Unit 4;
BA_ "GenSigStartValue" SG_ 291 NV_Charge_Unit 255;
BA_ "NmNetworkRequest" SG_ 291 NV_Charge_Unit 1;
BA_ "GenSigSendType" SG_ 291 TBT_BarGraph100Level 3;
BA_ "GenSigStartValue" SG_ 291 TBT_BarGraph100Level 255;
BA_ "TimeoutValue" SG_ 291 TBT_BarGraph100Level "old vaule";
BA_ "Validity" SG_ 291 TBT_BarGraph100Level 2;
BA_ "GenSigSendType" SG_ 290 NV_SD_SpdLimit2 4;
BA_ "GenSigStartValue" SG_ 290 NV_SD_SpdLimit2 15;
BA_ "NmNetworkRequest" SG_ 290 NV_SD_SpdLimit2 1;
BA_ "GenSigSendType" SG_ 290 NV_SD_SpdLimit1 4;
BA_ "GenSigStartValue" SG_ 290 NV_SD_SpdLimit1 15;
BA_ "NmNetworkRequest" SG_ 290 NV_SD_SpdLimit1 1;
BA_ "GenSigSendType" SG_ 290 NV_SD_EtcCam 4;
BA_ "GenSigStartValue" SG_ 290 NV_SD_EtcCam 3;
BA_ "NmNetworkRequest" SG_ 290 NV_SD_EtcCam 1;
BA_ "GenSigSendType" SG_ 290 NV_SD_SpdLimit3 4;
BA_ "GenSigStartValue" SG_ 290 NV_SD_SpdLimit3 15;
BA_ "NmNetworkRequest" SG_ 290 NV_SD_SpdLimit3 1;
BA_ "GenSigSendType" SG_ 290 NV_SD_SignCam 4;
BA_ "GenSigStartValue" SG_ 290 NV_SD_SignCam 3;
BA_ "NmNetworkRequest" SG_ 290 NV_SD_SignCam 1;
BA_ "GenSigSendType" SG_ 290 NV_SD_SignOverCam 4;
BA_ "GenSigStartValue" SG_ 290 NV_SD_SignOverCam 3;
BA_ "NmNetworkRequest" SG_ 290 NV_SD_SignOverCam 1;
BA_ "GenSigSendType" SG_ 290 NV_SD_MobileCam 4;
BA_ "GenSigStartValue" SG_ 290 NV_SD_MobileCam 3;
BA_ "NmNetworkRequest" SG_ 290 NV_SD_MobileCam 1;
BA_ "GenSigSendType" SG_ 290 NV_SD_FixedCam 4;
BA_ "GenSigStartValue" SG_ 290 NV_SD_FixedCam 3;
BA_ "NmNetworkRequest" SG_ 290 NV_SD_FixedCam 1;
BA_ "GenSigSendType" SG_ 290 NV_SD_OverLoadCam 4;
BA_ "GenSigStartValue" SG_ 290 NV_SD_OverLoadCam 3;
BA_ "NmNetworkRequest" SG_ 290 NV_SD_OverLoadCam 1;
BA_ "GenSigSendType" SG_ 290 NV_SD_ParkCam 4;
BA_ "GenSigStartValue" SG_ 290 NV_SD_ParkCam 3;
BA_ "NmNetworkRequest" SG_ 290 NV_SD_ParkCam 1;
BA_ "GenSigSendType" SG_ 290 NV_SD_CutInCam 4;
BA_ "GenSigStartValue" SG_ 290 NV_SD_CutInCam 3;
BA_ "NmNetworkRequest" SG_ 290 NV_SD_CutInCam 1;
BA_ "GenSigSendType" SG_ 290 NV_SD_BusOnlyCam 4;
BA_ "GenSigStartValue" SG_ 290 NV_SD_BusOnlyCam 3;
BA_ "NmNetworkRequest" SG_ 290 NV_SD_BusOnlyCam 1;
BA_ "GenSigSendType" SG_ 290 NV_SD_ShoulderCam 4;
BA_ "GenSigStartValue" SG_ 290 NV_SD_ShoulderCam 3;
BA_ "NmNetworkRequest" SG_ 290 NV_SD_ShoulderCam 1;
BA_ "GenSigSendType" SG_ 290 NV_SD_TrafficCam 4;
BA_ "GenSigStartValue" SG_ 290 NV_SD_TrafficCam 3;
BA_ "NmNetworkRequest" SG_ 290 NV_SD_TrafficCam 1;
BA_ "GenSigSendType" SG_ 290 NV_SD_PlateRcgCam 4;
BA_ "GenSigStartValue" SG_ 290 NV_SD_PlateRcgCam 3;
BA_ "NmNetworkRequest" SG_ 290 NV_SD_PlateRcgCam 1;
BA_ "GenSigSendType" SG_ 286 Navi_TBTInfo 4;
BA_ "GenSigStartValue" SG_ 286 Navi_TBTInfo 255;
BA_ "NmNetworkRequest" SG_ 286 Navi_TBTInfo 1;
BA_ "SignalCategory" SG_ 286 Navi_TBTInfo 13;
BA_ "TimeoutValue" SG_ 286 Navi_TBTInfo "Old Value";
BA_ "GenSigSendType" SG_ 29 SYS_CLUVer 4;
BA_ "GenSigStartValue" SG_ 29 SYS_CLUVer 65535;
BA_ "NmNetworkRequest" SG_ 29 SYS_CLUVer 1;
BA_ "GenSigSendType" SG_ 29 CLU_ClockInfoReq 4;
BA_ "GenSigStartValue" SG_ 29 CLU_ClockInfoReq 3;
BA_ "NmNetworkRequest" SG_ 29 CLU_ClockInfoReq 1;
BA_ "GenSigSendType" SG_ 29 CLU_DateInfoReq 4;
BA_ "GenSigStartValue" SG_ 29 CLU_DateInfoReq 3;
BA_ "NmNetworkRequest" SG_ 29 CLU_DateInfoReq 1;
BA_ "GenSigSendType" SG_ 27 SYS_AMPVer 4;
BA_ "NmNetworkRequest" SG_ 27 SYS_AMPVer 1;
BA_ "GenSigSendType" SG_ 23 C_ADrLNValueSet 4;
BA_ "GenSigStartValue" SG_ 23 C_ADrLNValueSet 7;
BA_ "NmNetworkRequest" SG_ 23 C_ADrLNValueSet 1;
BA_ "GenSigSendType" SG_ 23 C_ADrUNValueSet 4;
BA_ "GenSigStartValue" SG_ 23 C_ADrUNValueSet 7;
BA_ "NmNetworkRequest" SG_ 23 C_ADrUNValueSet 1;
BA_ "GenSigSendType" SG_ 23 SYS_Ver_Req 4;
BA_ "GenSigStartValue" SG_ 23 SYS_Ver_Req 3;
BA_ "NmNetworkRequest" SG_ 23 SYS_Ver_Req 1;
BA_ "GenSigSendType" SG_ 23 C_IMSRValueReq 4;
BA_ "GenSigStartValue" SG_ 23 C_IMSRValueReq 3;
BA_ "NmNetworkRequest" SG_ 23 C_IMSRValueReq 1;
BA_ "GenSigSendType" SG_ 23 C_PSMNValueSet 4;
BA_ "GenSigStartValue" SG_ 23 C_PSMNValueSet 3;
BA_ "NmNetworkRequest" SG_ 23 C_PSMNValueSet 1;
BA_ "GenSigSendType" SG_ 23 C_SCMNValueSet 4;
BA_ "GenSigStartValue" SG_ 23 C_SCMNValueSet 3;
BA_ "NmNetworkRequest" SG_ 23 C_SCMNValueSet 1;
BA_ "GenSigSendType" SG_ 23 C_ADrLURValueReq 4;
BA_ "GenSigStartValue" SG_ 23 C_ADrLURValueReq 3;
BA_ "NmNetworkRequest" SG_ 23 C_ADrLURValueReq 1;
BA_ "GenSigSendType" SG_ 23 C_ABuzzerNValueSet 4;
BA_ "GenSigStartValue" SG_ 23 C_ABuzzerNValueSet 3;
BA_ "NmNetworkRequest" SG_ 23 C_ABuzzerNValueSet 1;
BA_ "GenSigSendType" SG_ 23 C_AlarmRValueReq 4;
BA_ "GenSigStartValue" SG_ 23 C_AlarmRValueReq 3;
BA_ "NmNetworkRequest" SG_ 23 C_AlarmRValueReq 1;
BA_ "GenSigSendType" SG_ 23 C_ArmWKeyNValueSet 4;
BA_ "GenSigStartValue" SG_ 23 C_ArmWKeyNValueSet 3;
BA_ "NmNetworkRequest" SG_ 23 C_ArmWKeyNValueSet 1;
BA_ "GenSigSendType" SG_ 23 C_TwUnRValueReq 4;
BA_ "GenSigStartValue" SG_ 23 C_TwUnRValueReq 3;
BA_ "NmNetworkRequest" SG_ 23 C_TwUnRValueReq 1;
BA_ "NmNetworkRequestHoldingTime" SG_ 23 C_TwUnRValueReq 5;
BA_ "Validity" SG_ 23 C_TwUnRValueReq 0;
BA_ "GenSigSendType" SG_ 23 C_TwUnNValueSet 4;
BA_ "GenSigStartValue" SG_ 23 C_TwUnNValueSet 3;
BA_ "NmNetworkRequest" SG_ 23 C_TwUnNValueSet 1;
BA_ "NmNetworkRequestHoldingTime" SG_ 23 C_TwUnNValueSet 5;
BA_ "Validity" SG_ 23 C_TwUnNValueSet 0;
BA_ "GenSigSendType" SG_ 23 C_AutoMRFoldRValueReq 4;
BA_ "GenSigStartValue" SG_ 23 C_AutoMRFoldRValueReq 3;
BA_ "NmNetworkRequest" SG_ 23 C_AutoMRFoldRValueReq 1;
BA_ "Validity" SG_ 23 C_AutoMRFoldRValueReq 2;
BA_ "GenSigSendType" SG_ 23 C_AutoMRFoldNValueSet 4;
BA_ "GenSigStartValue" SG_ 23 C_AutoMRFoldNValueSet 3;
BA_ "NmNetworkRequest" SG_ 23 C_AutoMRFoldNValueSet 1;
BA_ "Validity" SG_ 23 C_AutoMRFoldNValueSet 2;
BA_ "GenSigSendType" SG_ 23 C_ADrLRValueReq 4;
BA_ "GenSigStartValue" SG_ 23 C_ADrLRValueReq 3;
BA_ "NmNetworkRequest" SG_ 23 C_ADrLRValueReq 1;
BA_ "GenSigSendType" SG_ 23 C_ArmWKeyRValueReq 4;
BA_ "GenSigStartValue" SG_ 23 C_ArmWKeyRValueReq 3;
BA_ "NmNetworkRequest" SG_ 23 C_ArmWKeyRValueReq 1;
BA_ "GenSigSendType" SG_ 23 C_ABuzzerRValueReq 4;
BA_ "GenSigStartValue" SG_ 23 C_ABuzzerRValueReq 3;
BA_ "NmNetworkRequest" SG_ 23 C_ABuzzerRValueReq 1;
BA_ "GenSigSendType" SG_ 23 C_ADrURValueReq 4;
BA_ "GenSigStartValue" SG_ 23 C_ADrURValueReq 3;
BA_ "NmNetworkRequest" SG_ 23 C_ADrURValueReq 1;
BA_ "GenSigSendType" SG_ 23 C_PSMRValueReq 4;
BA_ "GenSigStartValue" SG_ 23 C_PSMRValueReq 3;
BA_ "NmNetworkRequest" SG_ 23 C_PSMRValueReq 1;
BA_ "GenSigSendType" SG_ 23 C_SCMRValueReq 4;
BA_ "GenSigStartValue" SG_ 23 C_SCMRValueReq 3;
BA_ "NmNetworkRequest" SG_ 23 C_SCMRValueReq 1;
BA_ "GenSigSendType" SG_ 277 TBT_Display_Type 4;
BA_ "GenSigStartValue" SG_ 277 TBT_Display_Type 255;
BA_ "NmNetworkRequest" SG_ 277 TBT_Display_Type 1;
BA_ "TimeoutValue" SG_ 277 TBT_Display_Type "Old value";
BA_ "GenSigSendType" SG_ 277 TBT_Side_Street 4;
BA_ "GenSigStartValue" SG_ 277 TBT_Side_Street 65535;
BA_ "NmNetworkRequest" SG_ 277 TBT_Side_Street 1;
BA_ "TimeoutValue" SG_ 277 TBT_Side_Street "Old value";
BA_ "GenSigSendType" SG_ 277 TBT_Direction 4;
BA_ "GenSigStartValue" SG_ 277 TBT_Direction 255;
BA_ "NmNetworkRequest" SG_ 277 TBT_Direction 1;
BA_ "TimeoutValue" SG_ 277 TBT_Direction "Old value";
BA_ "GenSigSendType" SG_ 277 TBT_Distance_Turn_Point 4;
BA_ "GenSigStartValue" SG_ 277 TBT_Distance_Turn_Point 65535;
BA_ "NmNetworkRequest" SG_ 277 TBT_Distance_Turn_Point 1;
BA_ "TimeoutValue" SG_ 277 TBT_Distance_Turn_Point "Old value";
BA_ "GenSigSendType" SG_ 277 TBT_Combined_Side_Street 4;
BA_ "GenSigStartValue" SG_ 277 TBT_Combined_Side_Street 15;
BA_ "NmNetworkRequest" SG_ 277 TBT_Combined_Side_Street 1;
BA_ "TimeoutValue" SG_ 277 TBT_Combined_Side_Street "Old value";
BA_ "GenSigSendType" SG_ 277 TBT_Scale 4;
BA_ "GenSigStartValue" SG_ 277 TBT_Scale 15;
BA_ "NmNetworkRequest" SG_ 277 TBT_Scale 1;
BA_ "TimeoutValue" SG_ 277 TBT_Scale "Old value";
BA_ "GenSigSendType" SG_ 277 TBT_DistancetoTurnPoint 4;
BA_ "GenSigStartValue" SG_ 277 TBT_DistancetoTurnPoint 15;
BA_ "NmNetworkRequest" SG_ 277 TBT_DistancetoTurnPoint 1;
BA_ "TimeoutValue" SG_ 277 TBT_DistancetoTurnPoint "Old value";
BA_ "GenSigSendType" SG_ 277 TBT_Bar_Graph_Level 4;
BA_ "GenSigStartValue" SG_ 277 TBT_Bar_Graph_Level 15;
BA_ "NmNetworkRequest" SG_ 277 TBT_Bar_Graph_Level 1;
BA_ "TimeoutValue" SG_ 277 TBT_Bar_Graph_Level "Old value";
BA_ "GenSigSendType" SG_ 276 HU_OpState 4;
BA_ "GenSigStartValue" SG_ 276 HU_OpState 127;
BA_ "NmNetworkRequest" SG_ 276 HU_OpState 1;
BA_ "TimeoutValue" SG_ 276 HU_OpState "0x7F";
BA_ "GenSigSendType" SG_ 276 HU_Navi_On_Off 4;
BA_ "NmNetworkRequest" SG_ 276 HU_Navi_On_Off 1;
BA_ "GenSigSendType" SG_ 276 HU_Preset_Number 4;
BA_ "GenSigStartValue" SG_ 276 HU_Preset_Number 31;
BA_ "NmNetworkRequest" SG_ 276 HU_Preset_Number 1;
BA_ "TimeoutValue" SG_ 276 HU_Preset_Number "0x1F";
BA_ "GenSigSendType" SG_ 276 HU_Tuner_Area 4;
BA_ "GenSigStartValue" SG_ 276 HU_Tuner_Area 7;
BA_ "NmNetworkRequest" SG_ 276 HU_Tuner_Area 1;
BA_ "TimeoutValue" SG_ 276 HU_Tuner_Area "0x7";
BA_ "GenSigSendType" SG_ 276 HU_Track_Number 4;
BA_ "GenSigStartValue" SG_ 276 HU_Track_Number 65535;
BA_ "NmNetworkRequest" SG_ 276 HU_Track_Number 1;
BA_ "TimeoutValue" SG_ 276 HU_Track_Number "0xFFFF";
BA_ "GenSigSendType" SG_ 276 HU_Play_time_Sec 4;
BA_ "GenSigStartValue" SG_ 276 HU_Play_time_Sec 63;
BA_ "NmNetworkRequest" SG_ 276 HU_Play_time_Sec 1;
BA_ "TimeoutValue" SG_ 276 HU_Play_time_Sec "0x3F";
BA_ "GenSigSendType" SG_ 276 HU_Play_time_Min 4;
BA_ "GenSigStartValue" SG_ 276 HU_Play_time_Min 127;
BA_ "NmNetworkRequest" SG_ 276 HU_Play_time_Min 1;
BA_ "TimeoutValue" SG_ 276 HU_Play_time_Min "0x7F";
BA_ "GenSigSendType" SG_ 276 HU_Play_time_Hour 4;
BA_ "GenSigStartValue" SG_ 276 HU_Play_time_Hour 63;
BA_ "NmNetworkRequest" SG_ 276 HU_Play_time_Hour 1;
BA_ "TimeoutValue" SG_ 276 HU_Play_time_Hour "0x3F";
BA_ "GenSigSendType" SG_ 276 HU_Disc_select_No 4;
BA_ "GenSigStartValue" SG_ 276 HU_Disc_select_No 15;
BA_ "NmNetworkRequest" SG_ 276 HU_Disc_select_No 1;
BA_ "TimeoutValue" SG_ 276 HU_Disc_select_No "0xF";
BA_ "GenSigSendType" SG_ 276 HU_Frequency 4;
BA_ "GenSigStartValue" SG_ 276 HU_Frequency 511;
BA_ "NmNetworkRequest" SG_ 276 HU_Frequency 1;
BA_ "TimeoutValue" SG_ 276 HU_Frequency "0x1FF";
BA_ "GenSigSendType" SG_ 17 AMP_Beep2VolumeStep 4;
BA_ "GenSigStartValue" SG_ 17 AMP_Beep2VolumeStep 255;
BA_ "NmNetworkRequest" SG_ 17 AMP_Beep2VolumeStep 1;
BA_ "GenSigSendType" SG_ 17 AMP_Beep2Frequency 4;
BA_ "GenSigStartValue" SG_ 17 AMP_Beep2Frequency 65535;
BA_ "NmNetworkRequest" SG_ 17 AMP_Beep2Frequency 1;
BA_ "GenSigSendType" SG_ 17 AMP_Beep2Ch_OutputMask 4;
BA_ "GenSigStartValue" SG_ 17 AMP_Beep2Ch_OutputMask 65535;
BA_ "NmNetworkRequest" SG_ 17 AMP_Beep2Ch_OutputMask 1;
BA_ "GenSigSendType" SG_ 17 AMP_Beep2DurationOn 4;
BA_ "GenSigStartValue" SG_ 17 AMP_Beep2DurationOn 255;
BA_ "NmNetworkRequest" SG_ 17 AMP_Beep2DurationOn 1;
BA_ "GenSigSendType" SG_ 17 AMP_Beep2DurationOff 4;
BA_ "GenSigStartValue" SG_ 17 AMP_Beep2DurationOff 255;
BA_ "NmNetworkRequest" SG_ 17 AMP_Beep2DurationOff 1;
BA_ "GenSigSendType" SG_ 17 AMP_Beep2NumberOfCycles 4;
BA_ "GenSigStartValue" SG_ 17 AMP_Beep2NumberOfCycles 255;
BA_ "NmNetworkRequest" SG_ 17 AMP_Beep2NumberOfCycles 1;
BA_ "GenSigSendType" SG_ 15 AMP_MainVolumeSet 4;
BA_ "GenSigStartValue" SG_ 15 AMP_MainVolumeSet 255;
BA_ "NmNetworkRequest" SG_ 15 AMP_MainVolumeSet 1;
BA_ "GenSigSendType" SG_ 15 AMP_BalanceSet 4;
BA_ "GenSigStartValue" SG_ 15 AMP_BalanceSet 255;
BA_ "NmNetworkRequest" SG_ 15 AMP_BalanceSet 1;
BA_ "GenSigSendType" SG_ 15 AMP_FadeSet 4;
BA_ "GenSigStartValue" SG_ 15 AMP_FadeSet 255;
BA_ "NmNetworkRequest" SG_ 15 AMP_FadeSet 1;
BA_ "GenSigSendType" SG_ 15 AMP_BassSet 4;
BA_ "GenSigStartValue" SG_ 15 AMP_BassSet 255;
BA_ "NmNetworkRequest" SG_ 15 AMP_BassSet 1;
BA_ "GenSigSendType" SG_ 15 AMP_MidSet 4;
BA_ "GenSigStartValue" SG_ 15 AMP_MidSet 255;
BA_ "NmNetworkRequest" SG_ 15 AMP_MidSet 1;
BA_ "GenSigSendType" SG_ 15 AMP_TrebleSet 4;
BA_ "GenSigStartValue" SG_ 15 AMP_TrebleSet 255;
BA_ "NmNetworkRequest" SG_ 15 AMP_TrebleSet 1;
BA_ "GenSigSendType" SG_ 14 AMP_HFVolumeStep 4;
BA_ "GenSigStartValue" SG_ 14 AMP_HFVolumeStep 255;
BA_ "NmNetworkRequest" SG_ 14 AMP_HFVolumeStep 1;
BA_ "GenSigSendType" SG_ 14 AMP_HFMainAudioCut 4;
BA_ "GenSigStartValue" SG_ 14 AMP_HFMainAudioCut 255;
BA_ "NmNetworkRequest" SG_ 14 AMP_HFMainAudioCut 1;
BA_ "GenSigSendType" SG_ 14 AMP_HFChannelOutputMask 4;
BA_ "GenSigStartValue" SG_ 14 AMP_HFChannelOutputMask 65535;
BA_ "NmNetworkRequest" SG_ 14 AMP_HFChannelOutputMask 1;
BA_ "GenSigSendType" SG_ 14 AMP_HFChannelMuteMask 4;
BA_ "GenSigStartValue" SG_ 14 AMP_HFChannelMuteMask 65535;
BA_ "NmNetworkRequest" SG_ 14 AMP_HFChannelMuteMask 1;
BA_ "GenSigSendType" SG_ 13 AMP_MTSVolumeStep 4;
BA_ "GenSigStartValue" SG_ 13 AMP_MTSVolumeStep 255;
BA_ "NmNetworkRequest" SG_ 13 AMP_MTSVolumeStep 1;
BA_ "GenSigSendType" SG_ 13 AMP_MTSMainAudioCut 4;
BA_ "GenSigStartValue" SG_ 13 AMP_MTSMainAudioCut 255;
BA_ "NmNetworkRequest" SG_ 13 AMP_MTSMainAudioCut 1;
BA_ "GenSigSendType" SG_ 13 AMP_MTSChannelOutputMask 4;
BA_ "GenSigStartValue" SG_ 13 AMP_MTSChannelOutputMask 65535;
BA_ "NmNetworkRequest" SG_ 13 AMP_MTSChannelOutputMask 1;
BA_ "GenSigSendType" SG_ 13 AMP_MTSChannelMuteMask 4;
BA_ "GenSigStartValue" SG_ 13 AMP_MTSChannelMuteMask 65535;
BA_ "NmNetworkRequest" SG_ 13 AMP_MTSChannelMuteMask 1;
BA_ "GenSigSendType" SG_ 12 AMP_NaviVolumeStep 4;
BA_ "GenSigStartValue" SG_ 12 AMP_NaviVolumeStep 255;
BA_ "NmNetworkRequest" SG_ 12 AMP_NaviVolumeStep 1;
BA_ "GenSigSendType" SG_ 12 AMP_NaviMainAudioCut 4;
BA_ "GenSigStartValue" SG_ 12 AMP_NaviMainAudioCut 255;
BA_ "NmNetworkRequest" SG_ 12 AMP_NaviMainAudioCut 1;
BA_ "GenSigSendType" SG_ 12 AMP_NaviChannelOutputMask 4;
BA_ "GenSigStartValue" SG_ 12 AMP_NaviChannelOutputMask 65535;
BA_ "NmNetworkRequest" SG_ 12 AMP_NaviChannelOutputMask 1;
BA_ "GenSigSendType" SG_ 12 AMP_NaviChannelMuteMask 4;
BA_ "GenSigStartValue" SG_ 12 AMP_NaviChannelMuteMask 65535;
BA_ "NmNetworkRequest" SG_ 12 AMP_NaviChannelMuteMask 1;
BA_ "GenSigSendType" SG_ 11 AMP_Drive 4;
BA_ "GenSigStartValue" SG_ 11 AMP_Drive 3;
BA_ "NmNetworkRequest" SG_ 11 AMP_Drive 1;
BA_ "GenSigSendType" SG_ 11 AMP_ConvertibleTop 4;
BA_ "GenSigStartValue" SG_ 11 AMP_ConvertibleTop 3;
BA_ "NmNetworkRequest" SG_ 11 AMP_ConvertibleTop 1;
BA_ "GenSigSendType" SG_ 10 AMP_CrtVehicleID 4;
BA_ "GenSigStartValue" SG_ 10 AMP_CrtVehicleID 255;
BA_ "NmNetworkRequest" SG_ 10 AMP_CrtVehicleID 1;
BA_ "GenSigSendType" SG_ 10 AMP_SPDIFMode 4;
BA_ "GenSigStartValue" SG_ 10 AMP_SPDIFMode 15;
BA_ "NmNetworkRequest" SG_ 10 AMP_SPDIFMode 1;
BA_ "GenSigSendType" SG_ 10 AMP_VersionReq 4;
BA_ "NmNetworkRequest" SG_ 10 AMP_VersionReq 1;
BA_ "GenSigSendType" SG_ 10 AMP_UpdateStart 4;
BA_ "GenSigStartValue" SG_ 10 AMP_UpdateStart 3;
BA_ "NmNetworkRequest" SG_ 10 AMP_UpdateStart 1;
BA_ "GenSigSendType" SG_ 10 AMP_UpdateEnd 4;
BA_ "GenSigStartValue" SG_ 10 AMP_UpdateEnd 3;
BA_ "NmNetworkRequest" SG_ 10 AMP_UpdateEnd 1;
BA_ "GenSigSendType" SG_ 9 AMP_Mute 4;
BA_ "GenSigStartValue" SG_ 9 AMP_Mute 3;
BA_ "NmNetworkRequest" SG_ 9 AMP_Mute 1;
BA_ "GenSigSendType" SG_ 9 AMP_RearSpMute 4;
BA_ "GenSigStartValue" SG_ 9 AMP_RearSpMute 3;
BA_ "NmNetworkRequest" SG_ 9 AMP_RearSpMute 1;
BA_ "GenSigSendType" SG_ 9 AMP_SurroundMode 4;
BA_ "GenSigStartValue" SG_ 9 AMP_SurroundMode 3;
BA_ "NmNetworkRequest" SG_ 9 AMP_SurroundMode 1;
BA_ "GenSigSendType" SG_ 9 AMP_VEQMode 4;
BA_ "GenSigStartValue" SG_ 9 AMP_VEQMode 3;
BA_ "NmNetworkRequest" SG_ 9 AMP_VEQMode 1;
BA_ "GenSigSendType" SG_ 9 AMP_AudioMode 4;
BA_ "GenSigStartValue" SG_ 9 AMP_AudioMode 255;
BA_ "NmNetworkRequest" SG_ 9 AMP_AudioMode 1;
BA_ "GenSigSendType" SG_ 9 AMP_EQ 4;
BA_ "GenSigStartValue" SG_ 9 AMP_EQ 3;
BA_ "NmNetworkRequest" SG_ 9 AMP_EQ 1;
BA_ "GenSigSendType" SG_ 9 AMP_Reset 3;
BA_ "GenSigStartValue" SG_ 9 AMP_Reset 3;
BA_ "GenSigSendType" SG_ 9 AMP_SPDIFMute 4;
BA_ "GenSigStartValue" SG_ 9 AMP_SPDIFMute 1;
BA_ "NmNetworkRequest" SG_ 9 AMP_SPDIFMute 1;
BA_ "GenSigSendType" SG_ 9 AMP_DefaultBeep1 4;
BA_ "NmNetworkRequest" SG_ 9 AMP_DefaultBeep1 1;
BA_ "GenSigSendType" SG_ 9 AMP_DefaultBeep2 4;
BA_ "NmNetworkRequest" SG_ 9 AMP_DefaultBeep2 1;
BA_ "GenSigSendType" SG_ 9 AMP_BeatsMode 3;
BA_ "GenSigStartValue" SG_ 9 AMP_BeatsMode 3;
BA_ "GenSigSendType" SG_ 9 AMP_VIPMode 3;
BA_ "GenSigStartValue" SG_ 9 AMP_VIPMode 3;
BA_ "GenSigSendType" SG_ 9 AMP_QLSMode 3;
BA_ "GenSigStartValue" SG_ 9 AMP_QLSMode 3;
BA_ "GenSigStartValue" SG_ 1288 NV_TIME_TYPE 15;
BA_ "TimeoutValue" SG_ 1288 NV_TIME_TYPE "Old";
BA_ "GenSigStartValue" SG_ 1288 NV_Hour 255;
BA_ "TimeoutValue" SG_ 1288 NV_Hour "Old";
BA_ "GenSigStartValue" SG_ 1288 NV_Min 255;
BA_ "TimeoutValue" SG_ 1288 NV_Min "Old";
BA_ "GenSigSendType" SG_ 8 AMP_HFMode 4;
BA_ "GenSigStartValue" SG_ 8 AMP_HFMode 3;
BA_ "NmNetworkRequest" SG_ 8 AMP_HFMode 1;
BA_ "GenSigSendType" SG_ 8 AMP_NaviMode 4;
BA_ "GenSigStartValue" SG_ 8 AMP_NaviMode 3;
BA_ "NmNetworkRequest" SG_ 8 AMP_NaviMode 1;
BA_ "GenSigSendType" SG_ 8 AMP_MTSMode 4;
BA_ "GenSigStartValue" SG_ 8 AMP_MTSMode 3;
BA_ "NmNetworkRequest" SG_ 8 AMP_MTSMode 1;
BA_ "GenSigSendType" SG_ 8 AMP_VSCMode 4;
BA_ "GenSigStartValue" SG_ 8 AMP_VSCMode 3;
BA_ "NmNetworkRequest" SG_ 8 AMP_VSCMode 1;
BA_ "GenSigSendType" SG_ 8 AMP_Beep1Mode 4;
BA_ "GenSigStartValue" SG_ 8 AMP_Beep1Mode 3;
BA_ "NmNetworkRequest" SG_ 8 AMP_Beep1Mode 1;
BA_ "GenSigSendType" SG_ 8 AMP_Beep2Mode 4;
BA_ "GenSigStartValue" SG_ 8 AMP_Beep2Mode 3;
BA_ "NmNetworkRequest" SG_ 8 AMP_Beep2Mode 1;
BA_ "GenSigSendType" SG_ 8 AMP_SDVCStep 4;
BA_ "NmNetworkRequest" SG_ 8 AMP_SDVCStep 1;
BA_ "GenSigSendType" SG_ 8 AMP_ASDMode 4;
BA_ "GenSigStartValue" SG_ 8 AMP_ASDMode 7;
BA_ "NmNetworkRequest" SG_ 8 AMP_ASDMode 1;
BA_ "GenSigSendType" SG_ 8 AMP_SignalDoctor 3;
BA_ "GenSigStartValue" SG_ 8 AMP_SignalDoctor 3;
BA_ "GenSigSendType" SG_ 8 AMP_AutoVolume 3;
BA_ "GenSigStartValue" SG_ 8 AMP_AutoVolume 3;
BA_ "GenSigStartValue" SG_ 1287 NV_DistToTurn_F1 15;
BA_ "GenSigStartValue" SG_ 1287 NV_DistToTurn_Unit 15;
BA_ "GenSigStartValue" SG_ 1287 NV_DistToTurn_F3 15;
BA_ "GenSigStartValue" SG_ 1287 NV_DistToTurn_F2 15;
BA_ "GenSigStartValue" SG_ 1287 NV_DistToTurn_I1 65535;
BA_ "GenSigStartValue" SG_ 1287 NV_DistToTurn_I2 65535;
BA_ "GenSigStartValue" SG_ 1287 NV_DistToTurn_I3 65535;
BA_ "GenSigStartValue" SG_ 1286 NV_EstDist_F 15;
BA_ "GenSigStartValue" SG_ 1286 NV_EstDist_Unit 15;
BA_ "GenSigStartValue" SG_ 1286 NV_EstHour 255;
BA_ "GenSigStartValue" SG_ 1286 NV_EstMin 255;
BA_ "GenSigStartValue" SG_ 1286 NV_Azimuth 255;
BA_ "GenSigStartValue" SG_ 1286 NV_EstDist_I 65535;
BA_ "GenSigStartValue" SG_ 1286 NV_EstimTimeType 3;
BA_ "SignalCategory" SG_ 1286 NV_EstimTimeType 13;
BA_ "TimeoutValue" SG_ 1286 NV_EstimTimeType "Old Value";
BA_ "GenSigStartValue" SG_ 1286 NV_EstimTimeFormat 3;
BA_ "TimeoutValue" SG_ 1286 NV_EstimTimeFormat "Old Value";
BA_ "GenSigStartValue" SG_ 1284 HU_VehicleSpeed 255;
BA_ "TimeoutValue" SG_ 1284 HU_VehicleSpeed "0xFF";
BA_ "TimeoutValue" SG_ 1284 AMP_SetMaxMainVolStep "OldValue";
BA_ "GenSigStartValue" SG_ 1284 AMP_LKASWarningOn 3;
BA_ "SignalCategory" SG_ 1284 AMP_LKASWarningOn 13;
BA_ "TimeoutValue" SG_ 1284 AMP_LKASWarningOn "OldValue";
BA_ "GenSigStartValue" SG_ 1284 AMP_BSDWarningOn 3;
BA_ "SignalCategory" SG_ 1284 AMP_BSDWarningOn 13;
BA_ "TimeoutValue" SG_ 1284 AMP_BSDWarningOn "OldValue";
BA_ "GenSigSendType" SG_ 256 HU_Type 4;
BA_ "GenSigStartValue" SG_ 256 HU_Type 255;
BA_ "NmNetworkRequest" SG_ 256 HU_Type 1;
BA_ "TimeoutValue" SG_ 256 HU_Type "0xFF";
BA_ "GenSigSendType" SG_ 256 HU_VerMajor 4;
BA_ "GenSigStartValue" SG_ 256 HU_VerMajor 255;
BA_ "NmNetworkRequest" SG_ 256 HU_VerMajor 1;
BA_ "TimeoutValue" SG_ 256 HU_VerMajor "0xFF";
BA_ "GenSigSendType" SG_ 256 HU_VerMinor 4;
BA_ "GenSigStartValue" SG_ 256 HU_VerMinor 255;
BA_ "NmNetworkRequest" SG_ 256 HU_VerMinor 1;
BA_ "TimeoutValue" SG_ 256 HU_VerMinor "0xFF";
BA_ "GenSigSendType" SG_ 256 HU_DistributeInfo 4;
BA_ "GenSigStartValue" SG_ 256 HU_DistributeInfo 255;
BA_ "NmNetworkRequest" SG_ 256 HU_DistributeInfo 1;
BA_ "TimeoutValue" SG_ 256 HU_DistributeInfo "0xFF";
BA_ "GenSigSendType" SG_ 256 HU_SubVerMajor 4;
BA_ "GenSigStartValue" SG_ 256 HU_SubVerMajor 255;
BA_ "NmNetworkRequest" SG_ 256 HU_SubVerMajor 1;
BA_ "TimeoutValue" SG_ 256 HU_SubVerMajor "0xFF";
BA_ "GenSigSendType" SG_ 256 HU_SubVerMinor 4;
BA_ "GenSigStartValue" SG_ 256 HU_SubVerMinor 255;
BA_ "NmNetworkRequest" SG_ 256 HU_SubVerMinor 1;
BA_ "TimeoutValue" SG_ 256 HU_SubVerMinor "0xFF";
BA_ "GenSigSendType" SG_ 256 HU_SDARSVersion 4;
BA_ "GenSigStartValue" SG_ 256 HU_SDARSVersion 255;
BA_ "NmNetworkRequest" SG_ 256 HU_SDARSVersion 1;
BA_ "TimeoutValue" SG_ 256 HU_SDARSVersion "0xFF";
BA_ "GenSigSendType" SG_ 256 HU_AdasSupport 4;
BA_ "GenSigStartValue" SG_ 256 HU_AdasSupport 7;
BA_ "Gatewaysignal" SG_ 256 HU_AdasSupport 3;
BA_ "NmNetworkRequest" SG_ 256 HU_AdasSupport 1;
BA_ "TimeoutValue" SG_ 256 HU_AdasSupport "Old Value";
BA_REL_ "GenSigTimeoutTime" BU_SG_REL_ CGW SG_ 62 Navi_SLIF_Frwinfo 0;
BA_REL_ "GenSigTimeoutTime" BU_SG_REL_ CLU SG_ 62 Navi_SLIF_Frwinfo 0;
BA_REL_ "GenSigTimeoutTime" BU_SG_REL_ HUD SG_ 62 Navi_SLIF_Frwinfo 0;
BA_REL_ "GenSigTimeoutTime" BU_SG_REL_ CGW SG_ 62 Navi_SLIF_LinkClass 0;
BA_REL_ "GenSigTimeoutTime" BU_SG_REL_ CLU SG_ 62 Navi_SLIF_LinkClass 0;
BA_REL_ "GenSigTimeoutTime" BU_SG_REL_ HUD SG_ 62 Navi_SLIF_LinkClass 0;
BA_REL_ "GenSigTimeoutTime" BU_SG_REL_ CGW SG_ 62 Navi_SLIFMapSource 0;
BA_REL_ "GenSigTimeoutTime" BU_SG_REL_ CLU SG_ 62 Navi_SLIFMapSource 0;
BA_REL_ "GenSigTimeoutTime" BU_SG_REL_ HUD SG_ 62 Navi_SLIFMapSource 0;
BA_REL_ "GenSigTimeoutTime" BU_SG_REL_ CGW SG_ 62 Navi_SLIF_CountryCode 0;
BA_REL_ "GenSigTimeoutTime" BU_SG_REL_ CLU SG_ 62 Navi_SLIF_CountryCode 0;
BA_REL_ "GenSigTimeoutTime" BU_SG_REL_ HUD SG_ 62 Navi_SLIF_CountryCode 0;
BA_REL_ "GenSigTimeoutTime" BU_SG_REL_ CGW SG_ 52 HU_DATC_DrTempUpDn 0;
BA_REL_ "GenSigTimeoutTime" BU_SG_REL_ CLU SG_ 52 HU_DATC_DrTempUpDn 0;
BA_REL_ "GenSigTimeoutTime" BU_SG_REL_ DATC SG_ 52 HU_DATC_DrTempUpDn 0;
BA_REL_ "GenSigTimeoutTime" BU_SG_REL_ IPM SG_ 52 HU_DATC_DrTempUpDn 0;
BA_REL_ "GenSigTimeoutTime" BU_SG_REL_ CGW SG_ 52 HU_DATC_PsTempUpDn 0;
BA_REL_ "GenSigTimeoutTime" BU_SG_REL_ CLU SG_ 52 HU_DATC_PsTempUpDn 0;
BA_REL_ "GenSigTimeoutTime" BU_SG_REL_ DATC SG_ 52 HU_DATC_PsTempUpDn 0;
BA_REL_ "GenSigTimeoutTime" BU_SG_REL_ IPM SG_ 52 HU_DATC_PsTempUpDn 0;
BA_REL_ "GenSigTimeoutTime" BU_SG_REL_ CGW SG_ 52 HU_DATC_RlTempUpDn 0;
BA_REL_ "GenSigTimeoutTime" BU_SG_REL_ CLU SG_ 52 HU_DATC_RlTempUpDn 0;
BA_REL_ "GenSigTimeoutTime" BU_SG_REL_ DATC SG_ 52 HU_DATC_RlTempUpDn 0;
BA_REL_ "GenSigTimeoutTime" BU_SG_REL_ IPM SG_ 52 HU_DATC_RlTempUpDn 0;
BA_REL_ "GenSigTimeoutTime" BU_SG_REL_ CGW SG_ 52 HU_DATC_RrTempUpDn 0;
BA_REL_ "GenSigTimeoutTime" BU_SG_REL_ CLU SG_ 52 HU_DATC_RrTempUpDn 0;
BA_REL_ "GenSigTimeoutTime" BU_SG_REL_ DATC SG_ 52 HU_DATC_RrTempUpDn 0;
BA_REL_ "GenSigTimeoutTime" BU_SG_REL_ IPM SG_ 52 HU_DATC_RrTempUpDn 0;
BA_REL_ "GenSigTimeoutTime" BU_SG_REL_ CGW SG_ 52 HU_DATC_MainBlower 0;
BA_REL_ "GenSigTimeoutTime" BU_SG_REL_ CLU SG_ 52 HU_DATC_MainBlower 0;
BA_REL_ "GenSigTimeoutTime" BU_SG_REL_ DATC SG_ 52 HU_DATC_MainBlower 0;
BA_REL_ "GenSigTimeoutTime" BU_SG_REL_ IPM SG_ 52 HU_DATC_MainBlower 0;
BA_REL_ "GenSigTimeoutTime" BU_SG_REL_ CGW SG_ 52 HU_DATC_SubBlower 0;
BA_REL_ "GenSigTimeoutTime" BU_SG_REL_ CLU SG_ 52 HU_DATC_SubBlower 0;
BA_REL_ "GenSigTimeoutTime" BU_SG_REL_ DATC SG_ 52 HU_DATC_SubBlower 0;
BA_REL_ "GenSigTimeoutTime" BU_SG_REL_ IPM SG_ 52 HU_DATC_SubBlower 0;
BA_REL_ "GenSigTimeoutTime" BU_SG_REL_ CGW SG_ 52 HU_DATC_RearBlower 0;
BA_REL_ "GenSigTimeoutTime" BU_SG_REL_ CLU SG_ 52 HU_DATC_RearBlower 0;
BA_REL_ "GenSigTimeoutTime" BU_SG_REL_ DATC SG_ 52 HU_DATC_RearBlower 0;
BA_REL_ "GenSigTimeoutTime" BU_SG_REL_ IPM SG_ 52 HU_DATC_RearBlower 0;
BA_REL_ "GenSigTimeoutTime" BU_SG_REL_ CGW SG_ 52 HU_DATCRearPsModeSet 0;
BA_REL_ "GenSigTimeoutTime" BU_SG_REL_ CLU SG_ 52 HU_DATCRearPsModeSet 0;
BA_REL_ "GenSigTimeoutTime" BU_SG_REL_ CGW SG_ 52 HU_DATC_FrontModeSet 0;
BA_REL_ "GenSigTimeoutTime" BU_SG_REL_ CLU SG_ 52 HU_DATC_FrontModeSet 0;
BA_REL_ "GenSigTimeoutTime" BU_SG_REL_ DATC SG_ 52 HU_DATC_FrontModeSet 0;
BA_REL_ "GenSigTimeoutTime" BU_SG_REL_ IPM SG_ 52 HU_DATC_FrontModeSet 0;
BA_REL_ "GenSigTimeoutTime" BU_SG_REL_ CGW SG_ 52 HU_DATC_RearModeSet 0;
BA_REL_ "GenSigTimeoutTime" BU_SG_REL_ CLU SG_ 52 HU_DATC_RearModeSet 0;
BA_REL_ "GenSigTimeoutTime" BU_SG_REL_ DATC SG_ 52 HU_DATC_RearModeSet 0;
BA_REL_ "GenSigTimeoutTime" BU_SG_REL_ IPM SG_ 52 HU_DATC_RearModeSet 0;
BA_REL_ "GenSigTimeoutTime" BU_SG_REL_ CGW SG_ 52 HU_DATC_AutoSet 0;
BA_REL_ "GenSigTimeoutTime" BU_SG_REL_ CLU SG_ 52 HU_DATC_AutoSet 0;
BA_REL_ "GenSigTimeoutTime" BU_SG_REL_ DATC SG_ 52 HU_DATC_AutoSet 0;
BA_REL_ "GenSigTimeoutTime" BU_SG_REL_ IPM SG_ 52 HU_DATC_AutoSet 0;
BA_REL_ "GenSigTimeoutTime" BU_SG_REL_ CGW SG_ 52 HU_DATC_OffReq 0;
BA_REL_ "GenSigTimeoutTime" BU_SG_REL_ CLU SG_ 52 HU_DATC_OffReq 0;
BA_REL_ "GenSigTimeoutTime" BU_SG_REL_ DATC SG_ 52 HU_DATC_OffReq 0;
BA_REL_ "GenSigTimeoutTime" BU_SG_REL_ IPM SG_ 52 HU_DATC_OffReq 0;
BA_REL_ "GenSigTimeoutTime" BU_SG_REL_ CGW SG_ 52 HU_DATC_IntakeSet 0;
BA_REL_ "GenSigTimeoutTime" BU_SG_REL_ CLU SG_ 52 HU_DATC_IntakeSet 0;
BA_REL_ "GenSigTimeoutTime" BU_SG_REL_ DATC SG_ 52 HU_DATC_IntakeSet 0;
BA_REL_ "GenSigTimeoutTime" BU_SG_REL_ IPM SG_ 52 HU_DATC_IntakeSet 0;
BA_REL_ "GenSigTimeoutTime" BU_SG_REL_ CGW SG_ 52 HU_DATC_RearOnOffSet 0;
BA_REL_ "GenSigTimeoutTime" BU_SG_REL_ CLU SG_ 52 HU_DATC_RearOnOffSet 0;
BA_REL_ "GenSigTimeoutTime" BU_SG_REL_ DATC SG_ 52 HU_DATC_RearOnOffSet 0;
BA_REL_ "GenSigTimeoutTime" BU_SG_REL_ IPM SG_ 52 HU_DATC_RearOnOffSet 0;
BA_REL_ "GenSigTimeoutTime" BU_SG_REL_ CGW SG_ 52 HU_DATC_AcSet 0;
BA_REL_ "GenSigTimeoutTime" BU_SG_REL_ CLU SG_ 52 HU_DATC_AcSet 0;
BA_REL_ "GenSigTimeoutTime" BU_SG_REL_ DATC SG_ 52 HU_DATC_AcSet 0;
BA_REL_ "GenSigTimeoutTime" BU_SG_REL_ IPM SG_ 52 HU_DATC_AcSet 0;
BA_REL_ "GenSigTimeoutTime" BU_SG_REL_ CGW SG_ 52 HU_DATC_AqsSet 0;
BA_REL_ "GenSigTimeoutTime" BU_SG_REL_ CLU SG_ 52 HU_DATC_AqsSet 0;
BA_REL_ "GenSigTimeoutTime" BU_SG_REL_ DATC SG_ 52 HU_DATC_AqsSet 0;
BA_REL_ "GenSigTimeoutTime" BU_SG_REL_ IPM SG_ 52 HU_DATC_AqsSet 0;
BA_REL_ "GenSigTimeoutTime" BU_SG_REL_ CGW SG_ 52 HU_DATC_FrontDefog 0;
BA_REL_ "GenSigTimeoutTime" BU_SG_REL_ CLU SG_ 52 HU_DATC_FrontDefog 0;
BA_REL_ "GenSigTimeoutTime" BU_SG_REL_ DATC SG_ 52 HU_DATC_FrontDefog 0;
BA_REL_ "GenSigTimeoutTime" BU_SG_REL_ IPM SG_ 52 HU_DATC_FrontDefog 0;
BA_REL_ "GenSigTimeoutTime" BU_SG_REL_ CGW SG_ 52 HU_DATC_RearDefog 0;
BA_REL_ "GenSigTimeoutTime" BU_SG_REL_ CLU SG_ 52 HU_DATC_RearDefog 0;
BA_REL_ "GenSigTimeoutTime" BU_SG_REL_ DATC SG_ 52 HU_DATC_RearDefog 0;
BA_REL_ "GenSigTimeoutTime" BU_SG_REL_ IPM SG_ 52 HU_DATC_RearDefog 0;
BA_REL_ "GenSigTimeoutTime" BU_SG_REL_ CGW SG_ 52 HU_DATC_ZoneControl 0;
BA_REL_ "GenSigTimeoutTime" BU_SG_REL_ CLU SG_ 52 HU_DATC_ZoneControl 0;
BA_REL_ "GenSigTimeoutTime" BU_SG_REL_ DATC SG_ 52 HU_DATC_ZoneControl 0;
BA_REL_ "GenSigTimeoutTime" BU_SG_REL_ IPM SG_ 52 HU_DATC_ZoneControl 0;
BA_REL_ "GenSigTimeoutTime" BU_SG_REL_ CGW SG_ 52 HU_DATC_CO2Set 0;
BA_REL_ "GenSigTimeoutTime" BU_SG_REL_ CLU SG_ 52 HU_DATC_CO2Set 0;
BA_REL_ "GenSigTimeoutTime" BU_SG_REL_ DATC SG_ 52 HU_DATC_CO2Set 0;
BA_REL_ "GenSigTimeoutTime" BU_SG_REL_ IPM SG_ 52 HU_DATC_CO2Set 0;
BA_REL_ "GenSigTimeoutTime" BU_SG_REL_ CGW SG_ 52 DATC_SmartVentOnOffSet 0;
BA_REL_ "GenSigTimeoutTime" BU_SG_REL_ CLU SG_ 52 DATC_SmartVentOnOffSet 0;
BA_REL_ "GenSigTimeoutTime" BU_SG_REL_ DATC SG_ 52 DATC_SmartVentOnOffSet 0;
BA_REL_ "GenSigTimeoutTime" BU_SG_REL_ IPM SG_ 52 DATC_SmartVentOnOffSet 0;
BA_REL_ "GenSigTimeoutTime" BU_SG_REL_ CGW SG_ 52 DATC_ADSOnOffSet 0;
BA_REL_ "GenSigTimeoutTime" BU_SG_REL_ CLU SG_ 52 DATC_ADSOnOffSet 0;
BA_REL_ "GenSigTimeoutTime" BU_SG_REL_ CGW SG_ 52 HU_DATC_RearAutoDisp 0;
BA_REL_ "GenSigTimeoutTime" BU_SG_REL_ CLU SG_ 52 HU_DATC_RearAutoDisp 0;
BA_REL_ "GenSigTimeoutTime" BU_SG_REL_ CGW SG_ 52 HU_DATC_RearOffDisp 0;
BA_REL_ "GenSigTimeoutTime" BU_SG_REL_ CLU SG_ 52 HU_DATC_RearOffDisp 0;
BA_REL_ "GenSigTimeoutTime" BU_SG_REL_ AMP SG_ 308 DATC_PwrInfo 3500;
BA_REL_ "GenSigTimeoutTime" BU_SG_REL_ AVM SG_ 308 DATC_PwrInfo 3500;
BA_REL_ "GenSigTimeoutTime" BU_SG_REL_ CUBIS SG_ 308 DATC_PwrInfo 3500;
BA_REL_ "GenSigTimeoutTime" BU_SG_REL_ H_U SG_ 308 DATC_PwrInfo 3500;
BA_REL_ "GenSigTimeoutTime" BU_SG_REL_ MON SG_ 308 DATC_PwrInfo 3500;
BA_REL_ "GenSigTimeoutTime" BU_SG_REL_ H_U SG_ 308 DATC_AltL 3500;
BA_REL_ "GenSigTimeoutTime" BU_SG_REL_ MON SG_ 308 DATC_AltL 3500;
BA_REL_ "GenSigTimeoutTime" BU_SG_REL_ H_U SG_ 308 DATC_CarInfo 3500;
BA_REL_ "GenSigTimeoutTime" BU_SG_REL_ H_U SG_ 308 DATC_ParkingBrake 3500;
BA_REL_ "GenSigTimeoutTime" BU_SG_REL_ H_U SG_ 308 DATC_LowFuelWarn 3500;
BA_REL_ "GenSigTimeoutTime" BU_SG_REL_ H_U SG_ 308 DATC_Rear_Off_Disp 3500;
BA_REL_ "GenSigTimeoutTime" BU_SG_REL_ MON SG_ 308 DATC_Rear_Off_Disp 3500;
BA_REL_ "GenSigTimeoutTime" BU_SG_REL_ H_U SG_ 308 DATC_Rear_AutoDisp 3500;
BA_REL_ "GenSigTimeoutTime" BU_SG_REL_ MON SG_ 308 DATC_Rear_AutoDisp 3500;
BA_REL_ "GenSigTimeoutTime" BU_SG_REL_ H_U SG_ 308 DATC_Rear_BlowerDisp 3500;
BA_REL_ "GenSigTimeoutTime" BU_SG_REL_ MON SG_ 308 DATC_Rear_BlowerDisp 3500;
BA_REL_ "GenSigTimeoutTime" BU_SG_REL_ H_U SG_ 308 DATC_DrSeatWarmerDisp 3500;
BA_REL_ "GenSigTimeoutTime" BU_SG_REL_ MON SG_ 308 DATC_DrSeatWarmerDisp 3500;
BA_REL_ "GenSigTimeoutTime" BU_SG_REL_ H_U SG_ 308 DATC_SyncDisp 3500;
BA_REL_ "GenSigTimeoutTime" BU_SG_REL_ MON SG_ 308 DATC_SyncDisp 3500;
BA_REL_ "GenSigTimeoutTime" BU_SG_REL_ H_U SG_ 308 DATC_RearDispCtrl 3500;
BA_REL_ "GenSigTimeoutTime" BU_SG_REL_ MON SG_ 308 DATC_RearDispCtrl 3500;
BA_REL_ "GenSigTimeoutTime" BU_SG_REL_ H_U SG_ 308 DATC_RearDrModeDisp 3500;
BA_REL_ "GenSigTimeoutTime" BU_SG_REL_ H_U SG_ 308 DATC_PsSeatWarmerDisp 3500;
BA_REL_ "GenSigTimeoutTime" BU_SG_REL_ MON SG_ 308 DATC_PsSeatWarmerDisp 3500;
BA_REL_ "GenSigTimeoutTime" BU_SG_REL_ H_U SG_ 308 DATC_DrVentSeatDisp 3500;
BA_REL_ "GenSigTimeoutTime" BU_SG_REL_ MON SG_ 308 DATC_DrVentSeatDisp 3500;
BA_REL_ "GenSigTimeoutTime" BU_SG_REL_ H_U SG_ 308 DATC_PSVentSeatDisp 3500;
BA_REL_ "GenSigTimeoutTime" BU_SG_REL_ MON SG_ 308 DATC_PSVentSeatDisp 3500;
BA_REL_ "GenSigTimeoutTime" BU_SG_REL_ H_U SG_ 308 DATC_RrDefLed 3500;
BA_REL_ "GenSigTimeoutTime" BU_SG_REL_ MON SG_ 308 DATC_RrDefLed 3500;
BA_REL_ "GenSigTimeoutTime" BU_SG_REL_ H_U SG_ 308 DATC_SmartVentOnOffStatus 3500;
BA_REL_ "GenSigTimeoutTime" BU_SG_REL_ H_U SG_ 308 DATC_ADSOnOffStatus 3500;
BA_REL_ "GenSigTimeoutTime" BU_SG_REL_ H_U SG_ 308 DATC_AcDisp_OSD 3500;
BA_REL_ "GenSigTimeoutTime" BU_SG_REL_ H_U SG_ 308 DATC_PsModeDisp_OSD 3500;
BA_REL_ "GenSigTimeoutTime" BU_SG_REL_ H_U SG_ 308 DATC_ModeDisp_OSD 3500;
BA_REL_ "GenSigTimeoutTime" BU_SG_REL_ H_U SG_ 307 DATC_DiagMode 3500;
BA_REL_ "GenSigTimeoutTime" BU_SG_REL_ IBOX SG_ 307 DATC_DiagMode 3500;
BA_REL_ "GenSigTimeoutTime" BU_SG_REL_ MON SG_ 307 DATC_DiagMode 3500;
BA_REL_ "GenSigTimeoutTime" BU_SG_REL_ H_U SG_ 307 DATC_Rear_ChangeReqDisp 3500;
BA_REL_ "GenSigTimeoutTime" BU_SG_REL_ IBOX SG_ 307 DATC_Rear_ChangeReqDisp 3500;
BA_REL_ "GenSigTimeoutTime" BU_SG_REL_ MON SG_ 307 DATC_Rear_ChangeReqDisp 3500;
BA_REL_ "GenSigTimeoutTime" BU_SG_REL_ H_U SG_ 307 DATC_Rear_ClimateScnDisp 3500;
BA_REL_ "GenSigTimeoutTime" BU_SG_REL_ IBOX SG_ 307 DATC_Rear_ClimateScnDisp 3500;
BA_REL_ "GenSigTimeoutTime" BU_SG_REL_ MON SG_ 307 DATC_Rear_ClimateScnDisp 3500;
BA_REL_ "GenSigTimeoutTime" BU_SG_REL_ H_U SG_ 307 DATC_CO2OnOffStatus 3500;
BA_REL_ "GenSigTimeoutTime" BU_SG_REL_ H_U SG_ 307 DATC_SelfDiagDisp 3500;
BA_REL_ "GenSigTimeoutTime" BU_SG_REL_ IBOX SG_ 307 DATC_SelfDiagDisp 3500;
BA_REL_ "GenSigTimeoutTime" BU_SG_REL_ MON SG_ 307 DATC_SelfDiagDisp 3500;
BA_REL_ "GenSigTimeoutTime" BU_SG_REL_ H_U SG_ 307 DATC_AqsLevelOut 3500;
BA_REL_ "GenSigTimeoutTime" BU_SG_REL_ IBOX SG_ 307 DATC_AqsLevelOut 3500;
BA_REL_ "GenSigTimeoutTime" BU_SG_REL_ MON SG_ 307 DATC_AqsLevelOut 3500;
BA_REL_ "GenSigTimeoutTime" BU_SG_REL_ H_U SG_ 307 DATC_RearModeDisp 3500;
BA_REL_ "GenSigTimeoutTime" BU_SG_REL_ H_U SG_ 307 DATC_RearPsModeDisp 3500;
BA_REL_ "GenSigTimeoutTime" BU_SG_REL_ H_U SG_ 307 DATC_FrontBlwDisp_Ps 3500;
BA_REL_ "GenSigTimeoutTime" BU_SG_REL_ H_U SG_ 307 DATC_Variant 3500;
BA_REL_ "GenSigTimeoutTime" BU_SG_REL_ IBOX SG_ 307 DATC_Variant 3500;
BA_REL_ "GenSigTimeoutTime" BU_SG_REL_ MON SG_ 307 DATC_Variant 3500;
BA_REL_ "GenSigTimeoutTime" BU_SG_REL_ H_U SG_ 306 DATC_ModeDisp 3500;
BA_REL_ "GenSigTimeoutTime" BU_SG_REL_ IBOX SG_ 306 DATC_ModeDisp 3500;
BA_REL_ "GenSigTimeoutTime" BU_SG_REL_ H_U SG_ 306 DATC_TempUnit 3500;
BA_REL_ "GenSigTimeoutTime" BU_SG_REL_ IBOX SG_ 306 DATC_TempUnit 3500;
BA_REL_ "GenSigTimeoutTime" BU_SG_REL_ H_U SG_ 306 DATC_AutoDisp 3500;
BA_REL_ "GenSigTimeoutTime" BU_SG_REL_ IBOX SG_ 306 DATC_AutoDisp 3500;
BA_REL_ "GenSigTimeoutTime" BU_SG_REL_ H_U SG_ 306 DATC_IntakeDisp 3500;
BA_REL_ "GenSigTimeoutTime" BU_SG_REL_ IBOX SG_ 306 DATC_IntakeDisp 3500;
BA_REL_ "GenSigTimeoutTime" BU_SG_REL_ H_U SG_ 306 DATC_ChangeReqDisp 3500;
BA_REL_ "GenSigTimeoutTime" BU_SG_REL_ IBOX SG_ 306 DATC_ChangeReqDisp 3500;
BA_REL_ "GenSigTimeoutTime" BU_SG_REL_ H_U SG_ 306 DATC_AcDisp 3500;
BA_REL_ "GenSigTimeoutTime" BU_SG_REL_ IBOX SG_ 306 DATC_AcDisp 3500;
BA_REL_ "GenSigTimeoutTime" BU_SG_REL_ H_U SG_ 306 DATC_AqsDisp 3500;
BA_REL_ "GenSigTimeoutTime" BU_SG_REL_ IBOX SG_ 306 DATC_AqsDisp 3500;
BA_REL_ "GenSigTimeoutTime" BU_SG_REL_ H_U SG_ 306 DATC_ClimateScnDisp 3500;
BA_REL_ "GenSigTimeoutTime" BU_SG_REL_ IBOX SG_ 306 DATC_ClimateScnDisp 3500;
BA_REL_ "GenSigTimeoutTime" BU_SG_REL_ H_U SG_ 306 DATC_DualDisp 3500;
BA_REL_ "GenSigTimeoutTime" BU_SG_REL_ IBOX SG_ 306 DATC_DualDisp 3500;
BA_REL_ "GenSigTimeoutTime" BU_SG_REL_ H_U SG_ 306 DATC_OffDisp 3500;
BA_REL_ "GenSigTimeoutTime" BU_SG_REL_ IBOX SG_ 306 DATC_OffDisp 3500;
BA_REL_ "GenSigTimeoutTime" BU_SG_REL_ H_U SG_ 306 DATC_OpSts 3500;
BA_REL_ "GenSigTimeoutTime" BU_SG_REL_ IBOX SG_ 306 DATC_OpSts 3500;
BA_REL_ "GenSigTimeoutTime" BU_SG_REL_ H_U SG_ 306 DATC_RearManual 3500;
BA_REL_ "GenSigTimeoutTime" BU_SG_REL_ MON SG_ 306 DATC_RearManual 3500;
BA_REL_ "GenSigTimeoutTime" BU_SG_REL_ H_U SG_ 306 DATC_FrDefLed 3500;
BA_REL_ "GenSigTimeoutTime" BU_SG_REL_ H_U SG_ 306 DATC_SmartVentDisp 3500;
BA_REL_ "GenSigTimeoutTime" BU_SG_REL_ H_U SG_ 306 DATC_AutoDefogBlink 3500;
BA_REL_ "GenSigTimeoutTime" BU_SG_REL_ IBOX SG_ 306 DATC_AutoDefogBlink 3500;
BA_REL_ "GenSigTimeoutTime" BU_SG_REL_ H_U SG_ 306 DATC_ADSDisp 3500;
BA_REL_ "GenSigTimeoutTime" BU_SG_REL_ H_U SG_ 306 DATC_IonClean 3500;
BA_REL_ "GenSigTimeoutTime" BU_SG_REL_ IBOX SG_ 306 DATC_IonClean 3500;
BA_REL_ "GenSigTimeoutTime" BU_SG_REL_ H_U SG_ 306 DATC_CO2Warning 3500;
BA_REL_ "GenSigTimeoutTime" BU_SG_REL_ IBOX SG_ 306 DATC_CO2Warning 3500;
BA_REL_ "GenSigTimeoutTime" BU_SG_REL_ H_U SG_ 306 DATC_SubBlowerDisp 3500;
BA_REL_ "GenSigTimeoutTime" BU_SG_REL_ MON SG_ 306 DATC_SubBlowerDisp 3500;
BA_REL_ "GenSigTimeoutTime" BU_SG_REL_ H_U SG_ 306 DATC_BeepReq 3500;
BA_REL_ "GenSigTimeoutTime" BU_SG_REL_ KBD SG_ 306 DATC_BeepReq 3500;
BA_REL_ "GenSigTimeoutTime" BU_SG_REL_ MON SG_ 306 DATC_BeepReq 3500;
BA_REL_ "GenSigTimeoutTime" BU_SG_REL_ H_U SG_ 306 DATC_MainBlowerDisp 3500;
BA_REL_ "GenSigTimeoutTime" BU_SG_REL_ IBOX SG_ 306 DATC_MainBlowerDisp 3500;
BA_REL_ "GenSigTimeoutTime" BU_SG_REL_ H_U SG_ 306 DATC_PsModeDisp 3500;
BA_REL_ "GenSigTimeoutTime" BU_SG_REL_ IBOX SG_ 306 DATC_PsModeDisp 3500;
BA_REL_ "GenSigTimeoutTime" BU_SG_REL_ H_U SG_ 305 DATC_DrTempDispC 3500;
BA_REL_ "GenSigTimeoutTime" BU_SG_REL_ IBOX SG_ 305 DATC_DrTempDispC 3500;
BA_REL_ "GenSigTimeoutTime" BU_SG_REL_ MON SG_ 305 DATC_DrTempDispC 3500;
BA_REL_ "GenSigTimeoutTime" BU_SG_REL_ H_U SG_ 305 DATC_Rear_DrTempDispC 3500;
BA_REL_ "GenSigTimeoutTime" BU_SG_REL_ IBOX SG_ 305 DATC_Rear_DrTempDispC 3500;
BA_REL_ "GenSigTimeoutTime" BU_SG_REL_ MON SG_ 305 DATC_Rear_DrTempDispC 3500;
BA_REL_ "GenSigTimeoutTime" BU_SG_REL_ H_U SG_ 305 DATC_DrTempDispF 3500;
BA_REL_ "GenSigTimeoutTime" BU_SG_REL_ IBOX SG_ 305 DATC_DrTempDispF 3500;
BA_REL_ "GenSigTimeoutTime" BU_SG_REL_ MON SG_ 305 DATC_DrTempDispF 3500;
BA_REL_ "GenSigTimeoutTime" BU_SG_REL_ H_U SG_ 305 DATC_Rear_DrTempDispF 3500;
BA_REL_ "GenSigTimeoutTime" BU_SG_REL_ IBOX SG_ 305 DATC_Rear_DrTempDispF 3500;
BA_REL_ "GenSigTimeoutTime" BU_SG_REL_ MON SG_ 305 DATC_Rear_DrTempDispF 3500;
BA_REL_ "GenSigTimeoutTime" BU_SG_REL_ H_U SG_ 305 DATC_PsTempDispC 3500;
BA_REL_ "GenSigTimeoutTime" BU_SG_REL_ IBOX SG_ 305 DATC_PsTempDispC 3500;
BA_REL_ "GenSigTimeoutTime" BU_SG_REL_ MON SG_ 305 DATC_PsTempDispC 3500;
BA_REL_ "GenSigTimeoutTime" BU_SG_REL_ H_U SG_ 305 Datc_RearPsTempDispC 3500;
BA_REL_ "GenSigTimeoutTime" BU_SG_REL_ IBOX SG_ 305 Datc_RearPsTempDispC 3500;
BA_REL_ "GenSigTimeoutTime" BU_SG_REL_ MON SG_ 305 Datc_RearPsTempDispC 3500;
BA_REL_ "GenSigTimeoutTime" BU_SG_REL_ H_U SG_ 305 DATC_PsTempDispF 3500;
BA_REL_ "GenSigTimeoutTime" BU_SG_REL_ IBOX SG_ 305 DATC_PsTempDispF 3500;
BA_REL_ "GenSigTimeoutTime" BU_SG_REL_ MON SG_ 305 DATC_PsTempDispF 3500;
BA_REL_ "GenSigTimeoutTime" BU_SG_REL_ H_U SG_ 305 DATC_RearPsTempDispF 3500;
BA_REL_ "GenSigTimeoutTime" BU_SG_REL_ IBOX SG_ 305 DATC_RearPsTempDispF 3500;
BA_REL_ "GenSigTimeoutTime" BU_SG_REL_ MON SG_ 305 DATC_RearPsTempDispF 3500;
BA_REL_ "GenSigTimeoutTime" BU_SG_REL_ H_U SG_ 304 DATC_Type 3500;
BA_REL_ "GenSigTimeoutTime" BU_SG_REL_ MON SG_ 304 DATC_Type 3500;
BA_REL_ "GenSigTimeoutTime" BU_SG_REL_ H_U SG_ 304 DATC_VerMMMajor 3500;
BA_REL_ "GenSigTimeoutTime" BU_SG_REL_ MON SG_ 304 DATC_VerMMMajor 3500;
BA_REL_ "GenSigTimeoutTime" BU_SG_REL_ H_U SG_ 304 DATC_VerMMMinor 3500;
BA_REL_ "GenSigTimeoutTime" BU_SG_REL_ MON SG_ 304 DATC_VerMMMinor 3500;
BA_REL_ "GenSigTimeoutTime" BU_SG_REL_ H_U SG_ 304 DATC_VerBDFMajor 3500;
BA_REL_ "GenSigTimeoutTime" BU_SG_REL_ MON SG_ 304 DATC_VerBDFMajor 3500;
BA_REL_ "GenSigTimeoutTime" BU_SG_REL_ H_U SG_ 304 DATC_VerBDMinor 3500;
BA_REL_ "GenSigTimeoutTime" BU_SG_REL_ MON SG_ 304 DATC_VerBDMinor 3500;
BA_REL_ "GenSigTimeoutTime" BU_SG_REL_ H_U SG_ 304 DATC_VerCSMajor 3500;
BA_REL_ "GenSigTimeoutTime" BU_SG_REL_ MON SG_ 304 DATC_VerCSMajor 3500;
BA_REL_ "GenSigTimeoutTime" BU_SG_REL_ H_U SG_ 304 DATC_VerCSMinor 3500;
BA_REL_ "GenSigTimeoutTime" BU_SG_REL_ MON SG_ 304 DATC_VerCSMinor 3500;
BA_REL_ "GenSigTimeoutTime" BU_SG_REL_ CLU SG_ 291 TBT_BarGraph100Level 750;
BA_REL_ "GenSigTimeoutTime" BU_SG_REL_ HUD SG_ 291 TBT_BarGraph100Level 750;
BA_REL_ "GenSigTimeoutTime" BU_SG_REL_ CUBIS SG_ 29 SYS_CLUVer 0;
BA_REL_ "GenSigTimeoutTime" BU_SG_REL_ H_U SG_ 29 SYS_CLUVer 0;
BA_REL_ "GenSigTimeoutTime" BU_SG_REL_ H_U SG_ 29 CLU_ClockInfoReq 0;
BA_REL_ "GenSigTimeoutTime" BU_SG_REL_ H_U SG_ 29 CLU_DateInfoReq 0;
BA_REL_ "GenSigTimeoutTime" BU_SG_REL_ H_U SG_ 27 SYS_AMPVer 0;
BA_REL_ "GenSigTimeoutTime" BU_SG_REL_ DATC SG_ 23 C_ADrLNValueSet 0;
BA_REL_ "GenSigTimeoutTime" BU_SG_REL_ IPM SG_ 23 C_ADrLNValueSet 0;
BA_REL_ "GenSigTimeoutTime" BU_SG_REL_ DATC SG_ 23 C_ADrUNValueSet 0;
BA_REL_ "GenSigTimeoutTime" BU_SG_REL_ IPM SG_ 23 C_ADrUNValueSet 0;
BA_REL_ "GenSigTimeoutTime" BU_SG_REL_ AMP SG_ 23 SYS_Ver_Req 0;
BA_REL_ "GenSigTimeoutTime" BU_SG_REL_ AVM SG_ 23 SYS_Ver_Req 0;
BA_REL_ "GenSigTimeoutTime" BU_SG_REL_ CLU SG_ 23 SYS_Ver_Req 0;
BA_REL_ "GenSigTimeoutTime" BU_SG_REL_ CUBIS SG_ 23 SYS_Ver_Req 0;
BA_REL_ "GenSigTimeoutTime" BU_SG_REL_ DATC SG_ 23 SYS_Ver_Req 0;
BA_REL_ "GenSigTimeoutTime" BU_SG_REL_ IPM SG_ 23 SYS_Ver_Req 0;
BA_REL_ "GenSigTimeoutTime" BU_SG_REL_ DATC SG_ 23 C_IMSRValueReq 0;
BA_REL_ "GenSigTimeoutTime" BU_SG_REL_ IPM SG_ 23 C_IMSRValueReq 0;
BA_REL_ "GenSigTimeoutTime" BU_SG_REL_ DATC SG_ 23 C_PSMNValueSet 0;
BA_REL_ "GenSigTimeoutTime" BU_SG_REL_ IPM SG_ 23 C_PSMNValueSet 0;
BA_REL_ "GenSigTimeoutTime" BU_SG_REL_ DATC SG_ 23 C_SCMNValueSet 0;
BA_REL_ "GenSigTimeoutTime" BU_SG_REL_ IPM SG_ 23 C_SCMNValueSet 0;
BA_REL_ "GenSigTimeoutTime" BU_SG_REL_ DATC SG_ 23 C_ADrLURValueReq 0;
BA_REL_ "GenSigTimeoutTime" BU_SG_REL_ IPM SG_ 23 C_ADrLURValueReq 0;
BA_REL_ "GenSigTimeoutTime" BU_SG_REL_ DATC SG_ 23 C_ABuzzerNValueSet 0;
BA_REL_ "GenSigTimeoutTime" BU_SG_REL_ IPM SG_ 23 C_ABuzzerNValueSet 0;
BA_REL_ "GenSigTimeoutTime" BU_SG_REL_ DATC SG_ 23 C_AlarmRValueReq 0;
BA_REL_ "GenSigTimeoutTime" BU_SG_REL_ IPM SG_ 23 C_AlarmRValueReq 0;
BA_REL_ "GenSigTimeoutTime" BU_SG_REL_ DATC SG_ 23 C_ArmWKeyNValueSet 0;
BA_REL_ "GenSigTimeoutTime" BU_SG_REL_ IPM SG_ 23 C_ArmWKeyNValueSet 0;
BA_REL_ "GenSigTimeoutTime" BU_SG_REL_ DATC SG_ 23 C_TwUnRValueReq 0;
BA_REL_ "GenSigTimeoutTime" BU_SG_REL_ IPM SG_ 23 C_TwUnRValueReq 0;
BA_REL_ "GenSigTimeoutTime" BU_SG_REL_ DATC SG_ 23 C_TwUnNValueSet 0;
BA_REL_ "GenSigTimeoutTime" BU_SG_REL_ IPM SG_ 23 C_TwUnNValueSet 0;
BA_REL_ "GenSigTimeoutTime" BU_SG_REL_ DATC SG_ 23 C_AutoMRFoldRValueReq 0;
BA_REL_ "GenSigTimeoutTime" BU_SG_REL_ IPM SG_ 23 C_AutoMRFoldRValueReq 0;
BA_REL_ "GenSigTimeoutTime" BU_SG_REL_ DATC SG_ 23 C_AutoMRFoldNValueSet 0;
BA_REL_ "GenSigTimeoutTime" BU_SG_REL_ IPM SG_ 23 C_AutoMRFoldNValueSet 0;
BA_REL_ "GenSigTimeoutTime" BU_SG_REL_ DATC SG_ 23 C_ADrLRValueReq 0;
BA_REL_ "GenSigTimeoutTime" BU_SG_REL_ IPM SG_ 23 C_ADrLRValueReq 0;
BA_REL_ "GenSigTimeoutTime" BU_SG_REL_ DATC SG_ 23 C_ArmWKeyRValueReq 0;
BA_REL_ "GenSigTimeoutTime" BU_SG_REL_ IPM SG_ 23 C_ArmWKeyRValueReq 0;
BA_REL_ "GenSigTimeoutTime" BU_SG_REL_ DATC SG_ 23 C_ABuzzerRValueReq 0;
BA_REL_ "GenSigTimeoutTime" BU_SG_REL_ IPM SG_ 23 C_ABuzzerRValueReq 0;
BA_REL_ "GenSigTimeoutTime" BU_SG_REL_ DATC SG_ 23 C_ADrURValueReq 0;
BA_REL_ "GenSigTimeoutTime" BU_SG_REL_ IPM SG_ 23 C_ADrURValueReq 0;
BA_REL_ "GenSigTimeoutTime" BU_SG_REL_ DATC SG_ 23 C_PSMRValueReq 0;
BA_REL_ "GenSigTimeoutTime" BU_SG_REL_ IPM SG_ 23 C_PSMRValueReq 0;
BA_REL_ "GenSigTimeoutTime" BU_SG_REL_ DATC SG_ 23 C_SCMRValueReq 0;
BA_REL_ "GenSigTimeoutTime" BU_SG_REL_ IPM SG_ 23 C_SCMRValueReq 0;
BA_REL_ "GenSigTimeoutTime" BU_SG_REL_ AMP SG_ 17 AMP_Beep2VolumeStep 0;
BA_REL_ "GenSigTimeoutTime" BU_SG_REL_ AMP SG_ 17 AMP_Beep2Frequency 0;
BA_REL_ "GenSigTimeoutTime" BU_SG_REL_ AMP SG_ 17 AMP_Beep2Ch_OutputMask 0;
BA_REL_ "GenSigTimeoutTime" BU_SG_REL_ AMP SG_ 17 AMP_Beep2DurationOn 0;
BA_REL_ "GenSigTimeoutTime" BU_SG_REL_ AMP SG_ 17 AMP_Beep2DurationOff 0;
BA_REL_ "GenSigTimeoutTime" BU_SG_REL_ AMP SG_ 17 AMP_Beep2NumberOfCycles 0;
BA_REL_ "GenSigTimeoutTime" BU_SG_REL_ AMP SG_ 15 AMP_MainVolumeSet 0;
BA_REL_ "GenSigTimeoutTime" BU_SG_REL_ AMP SG_ 15 AMP_BalanceSet 0;
BA_REL_ "GenSigTimeoutTime" BU_SG_REL_ AMP SG_ 15 AMP_FadeSet 0;
BA_REL_ "GenSigTimeoutTime" BU_SG_REL_ AMP SG_ 15 AMP_BassSet 0;
BA_REL_ "GenSigTimeoutTime" BU_SG_REL_ AMP SG_ 15 AMP_MidSet 0;
BA_REL_ "GenSigTimeoutTime" BU_SG_REL_ AMP SG_ 15 AMP_TrebleSet 0;
BA_REL_ "GenSigTimeoutTime" BU_SG_REL_ AMP SG_ 14 AMP_HFVolumeStep 0;
BA_REL_ "GenSigTimeoutTime" BU_SG_REL_ AMP SG_ 14 AMP_HFMainAudioCut 0;
BA_REL_ "GenSigTimeoutTime" BU_SG_REL_ AMP SG_ 14 AMP_HFChannelOutputMask 0;
BA_REL_ "GenSigTimeoutTime" BU_SG_REL_ AMP SG_ 14 AMP_HFChannelMuteMask 0;
BA_REL_ "GenSigTimeoutTime" BU_SG_REL_ AMP SG_ 13 AMP_MTSVolumeStep 0;
BA_REL_ "GenSigTimeoutTime" BU_SG_REL_ AMP SG_ 13 AMP_MTSMainAudioCut 0;
BA_REL_ "GenSigTimeoutTime" BU_SG_REL_ AMP SG_ 13 AMP_MTSChannelOutputMask 0;
BA_REL_ "GenSigTimeoutTime" BU_SG_REL_ AMP SG_ 13 AMP_MTSChannelMuteMask 0;
BA_REL_ "GenSigTimeoutTime" BU_SG_REL_ AMP SG_ 12 AMP_NaviVolumeStep 0;
BA_REL_ "GenSigTimeoutTime" BU_SG_REL_ AMP SG_ 12 AMP_NaviMainAudioCut 0;
BA_REL_ "GenSigTimeoutTime" BU_SG_REL_ AMP SG_ 12 AMP_NaviChannelOutputMask 0;
BA_REL_ "GenSigTimeoutTime" BU_SG_REL_ AMP SG_ 12 AMP_NaviChannelMuteMask 0;
BA_REL_ "GenSigTimeoutTime" BU_SG_REL_ AMP SG_ 11 AMP_Drive 0;
BA_REL_ "GenSigTimeoutTime" BU_SG_REL_ AMP SG_ 11 AMP_ConvertibleTop 0;
BA_REL_ "GenSigTimeoutTime" BU_SG_REL_ AMP SG_ 10 AMP_CrtVehicleID 0;
BA_REL_ "GenSigTimeoutTime" BU_SG_REL_ AMP SG_ 10 AMP_SPDIFMode 0;
BA_REL_ "GenSigTimeoutTime" BU_SG_REL_ AMP SG_ 10 AMP_VersionReq 0;
BA_REL_ "GenSigTimeoutTime" BU_SG_REL_ AMP SG_ 10 AMP_UpdateStart 0;
BA_REL_ "GenSigTimeoutTime" BU_SG_REL_ AMP SG_ 10 AMP_UpdateEnd 0;
BA_REL_ "GenSigTimeoutTime" BU_SG_REL_ AMP SG_ 9 AMP_Mute 0;
BA_REL_ "GenSigTimeoutTime" BU_SG_REL_ AMP SG_ 9 AMP_RearSpMute 0;
BA_REL_ "GenSigTimeoutTime" BU_SG_REL_ AMP SG_ 9 AMP_SurroundMode 0;
BA_REL_ "GenSigTimeoutTime" BU_SG_REL_ AMP SG_ 9 AMP_VEQMode 0;
BA_REL_ "GenSigTimeoutTime" BU_SG_REL_ AMP SG_ 9 AMP_AudioMode 0;
BA_REL_ "GenSigTimeoutTime" BU_SG_REL_ AMP SG_ 9 AMP_EQ 0;
BA_REL_ "GenSigTimeoutTime" BU_SG_REL_ AMP SG_ 9 AMP_Reset 0;
BA_REL_ "GenSigTimeoutTime" BU_SG_REL_ AMP SG_ 9 AMP_SPDIFMute 0;
BA_REL_ "GenSigTimeoutTime" BU_SG_REL_ AMP SG_ 9 AMP_DefaultBeep1 0;
BA_REL_ "GenSigTimeoutTime" BU_SG_REL_ AMP SG_ 9 AMP_DefaultBeep2 0;
BA_REL_ "GenSigTimeoutTime" BU_SG_REL_ AMP SG_ 9 AMP_BeatsMode 0;
BA_REL_ "GenSigTimeoutTime" BU_SG_REL_ AMP SG_ 9 AMP_VIPMode 0;
BA_REL_ "GenSigTimeoutTime" BU_SG_REL_ AMP SG_ 9 AMP_QLSMode 0;
BA_REL_ "GenSigTimeoutTime" BU_SG_REL_ AMP SG_ 8 AMP_HFMode 0;
BA_REL_ "GenSigTimeoutTime" BU_SG_REL_ AMP SG_ 8 AMP_NaviMode 0;
BA_REL_ "GenSigTimeoutTime" BU_SG_REL_ AMP SG_ 8 AMP_MTSMode 0;
BA_REL_ "GenSigTimeoutTime" BU_SG_REL_ AMP SG_ 8 AMP_VSCMode 0;
BA_REL_ "GenSigTimeoutTime" BU_SG_REL_ AMP SG_ 8 AMP_Beep1Mode 0;
BA_REL_ "GenSigTimeoutTime" BU_SG_REL_ AMP SG_ 8 AMP_Beep2Mode 0;
BA_REL_ "GenSigTimeoutTime" BU_SG_REL_ AMP SG_ 8 AMP_SDVCStep 0;
BA_REL_ "GenSigTimeoutTime" BU_SG_REL_ AMP SG_ 8 AMP_ASDMode 0;
BA_REL_ "GenSigTimeoutTime" BU_SG_REL_ AMP SG_ 8 AMP_SignalDoctor 0;
BA_REL_ "GenSigTimeoutTime" BU_SG_REL_ AMP SG_ 8 AMP_AutoVolume 0;
BA_REL_ "GenSigTimeoutTime" BU_SG_REL_ AMP SG_ 256 HU_Type 3500;
BA_REL_ "GenSigTimeoutTime" BU_SG_REL_ CGW SG_ 256 HU_Type 3500;
BA_REL_ "GenSigTimeoutTime" BU_SG_REL_ CLU SG_ 256 HU_Type 3500;
BA_REL_ "GenSigTimeoutTime" BU_SG_REL_ HUD SG_ 256 HU_Type 3500;
BA_REL_ "GenSigTimeoutTime" BU_SG_REL_ KMA_TMU SG_ 256 HU_Type 3500;
BA_REL_ "GenSigTimeoutTime" BU_SG_REL_ AMP SG_ 256 HU_VerMajor 3500;
BA_REL_ "GenSigTimeoutTime" BU_SG_REL_ CLU SG_ 256 HU_VerMajor 3500;
BA_REL_ "GenSigTimeoutTime" BU_SG_REL_ KMA_TMU SG_ 256 HU_VerMajor 3500;
BA_REL_ "GenSigTimeoutTime" BU_SG_REL_ MON SG_ 256 HU_VerMajor 3500;
BA_REL_ "GenSigTimeoutTime" BU_SG_REL_ AMP SG_ 256 HU_VerMinor 3500;
BA_REL_ "GenSigTimeoutTime" BU_SG_REL_ CLU SG_ 256 HU_VerMinor 3500;
BA_REL_ "GenSigTimeoutTime" BU_SG_REL_ KMA_TMU SG_ 256 HU_VerMinor 3500;
BA_REL_ "GenSigTimeoutTime" BU_SG_REL_ MON SG_ 256 HU_VerMinor 3500;
BA_REL_ "GenSigTimeoutTime" BU_SG_REL_ AMP SG_ 256 HU_DistributeInfo 3500;
BA_REL_ "GenSigTimeoutTime" BU_SG_REL_ CGW SG_ 256 HU_DistributeInfo 3500;
BA_REL_ "GenSigTimeoutTime" BU_SG_REL_ CLU SG_ 256 HU_DistributeInfo 3500;
BA_REL_ "GenSigTimeoutTime" BU_SG_REL_ KMA_TMU SG_ 256 HU_DistributeInfo 3500;
BA_REL_ "GenSigTimeoutTime" BU_SG_REL_ MON SG_ 256 HU_DistributeInfo 3500;
BA_REL_ "GenSigTimeoutTime" BU_SG_REL_ RRC SG_ 256 HU_DistributeInfo 3500;
BA_REL_ "GenSigTimeoutTime" BU_SG_REL_ AMP SG_ 256 HU_SubVerMajor 3500;
BA_REL_ "GenSigTimeoutTime" BU_SG_REL_ MON SG_ 256 HU_SubVerMajor 3500;
BA_REL_ "GenSigTimeoutTime" BU_SG_REL_ AMP SG_ 256 HU_SubVerMinor 3500;
BA_REL_ "GenSigTimeoutTime" BU_SG_REL_ MON SG_ 256 HU_SubVerMinor 3500;
BA_REL_ "GenSigTimeoutTime" BU_SG_REL_ AMP SG_ 256 HU_SDARSVersion 3500;
BA_REL_ "GenSigTimeoutTime" BU_SG_REL_ MON SG_ 256 HU_SDARSVersion 3500;
BA_REL_ "GenSigTimeoutTime" BU_SG_REL_ CGW SG_ 256 HU_AdasSupport 3500;
BA_REL_ "GenSigTimeoutTime" BU_SG_REL_ CLU SG_ 256 HU_AdasSupport 3500;
VAL_ 62 Navi_SLIF_SpdUnit 0 "None" 1 "KPH" 2 "MPH" 3 "Invalid" ;
VAL_ 62 Navi_SLIF_Frwinfo 0 "None" 1 "Entrance" 2 "Exit" 3 "Branch" 4 "Restarea" 7 "Invalid" ;
VAL_ 62 Navi_SLIF_LinkClass 0 "Unknown" 1 "Freeway" 2 "IC" 3 "JC" 4 "Restarea" 5 "Arterial" 6 "Country" 7 "Invalid" ;
VAL_ 62 Navi_SLIF_SpdLimit 0 "None" 254 "Unlimited" 255 "Invalid" ;
VAL_ 62 Navi_SLIFMapSource 0 "None" 1 "Navteq" 2 "TomTom" 3 "Reserved" 4 "Reserved" 5 "Reserved" 6 "Reserved" 7 "Invalid" ;
VAL_ 62 Navi_SLIF_CountryCode 0 "Unknown" 1023 "Invalid" ;
VAL_ 52 HU_DATC_DrTempUpDn 0 "Off" 1 "Temp Up" 2 "Temp Down" 3 "Invalid" ;
VAL_ 52 HU_DATC_PsTempUpDn 0 "Off" 1 "Temp Up" 2 "Temp Down" 3 "Invalid" ;
VAL_ 52 HU_DATC_RlTempUpDn 0 "Off" 1 "Temp Up" 2 "Temp Down" 3 "Invalid" ;
VAL_ 52 HU_DATC_RrTempUpDn 0 "Off" 1 "Temp Up" 2 "Temp Down" 3 "Invalid" ;
VAL_ 52 HU_DATC_MainBlower 0 "Off" 1 "0 level" 2 "1 level" 3 "2 level" 4 "3 level" 5 "4 level" 6 "5 level" 7 "6 level" 8 "7 level" 9 "8 level" 10 "Level Up" 11 "Level Down" 12 "Max" 13 "Min" 14 "reserved" 15 "Invalid" ;
VAL_ 52 HU_DATC_SubBlower 0 "Off" 1 "0 level" 2 "1 level" 3 "2 level" 4 "3 level" 5 "4 level" 6 "5 level" 7 "6 level" 8 "7 level" 9 "8 level" 10 "Level Up" 11 "Level Down" 12 "Max" 13 "Min" 14 "reserved" 15 "Invalid" ;
VAL_ 52 HU_DATC_RearBlower 0 "Off" 1 "0 level" 2 "1 level" 3 "2 level" 4 "3 level" 5 "4 level" 6 "5 level" 7 "6 level" 8 "7 level" 9 "8 level" 10 "Level Up" 11 "Level Down" 12 "Max" 13 "Min" 14 "reserved" 15 "Invalid" ;
VAL_ 52 HU_DATCRearPsModeSet 0 "off" 1 "Vent" 2 "B_L" 3 "Floor" 15 "Invalid" ;
VAL_ 52 HU_DATC_FrontModeSet 0 "Off" 1 "VENT" 2 "BL" 3 "FLOOR" 4 "MIX" 5 "DEF" 6 "AUTO DEFOG" 7 "reserved" 8 "reserved" 9 "reserved" 10 "Mode Up" 11 "Mode Down" 12 "reserved" 13 "reserved" 14 "reserved" 15 "Invalid" ;
VAL_ 52 HU_DATC_RearModeSet 0 "Off" 1 "VENT" 2 "BL" 3 "FLOOR" 4 "MIX" 5 "DEF" 6 "AUTO DEFOG" 7 "reserved" 8 "reserved" 9 "reserved" 10 "Mode Up" 11 "Mode Down" 12 "reserved" 13 "reserved" 14 "reserved" 15 "Invalid" ;
VAL_ 52 HU_DATC_AutoSet 0 "Off" 1 "AUTO ON" 2 "reserved" 3 "Invalid" ;
VAL_ 52 HU_DATC_OffReq 0 "None" 1 "Request" 2 "reserved" 3 "Invalid" ;
VAL_ 52 HU_DATC_IntakeSet 0 "Off" 1 "Intake ON" 2 "reserved" 3 "Invalid" ;
VAL_ 52 HU_DATC_RearOnOffSet 0 "Rear Off" 1 "Rear ON" 2 "reserved" 3 "Invalid" ;
VAL_ 52 HU_DATC_AcSet 0 "Off" 1 "AC ON" 2 "reserved" 3 "Invalid" ;
VAL_ 52 HU_DATC_AqsSet 0 "Off" 1 "AQS ON" 2 "reserved" 3 "Invalid" ;
VAL_ 52 HU_DATC_FrontDefog 0 "Off" 1 "Defog On" 2 "reserved" 3 "Invalid" ;
VAL_ 52 HU_DATC_RearDefog 0 "Off" 1 "Defog On" 2 "reserved" 3 "Invalid" ;
VAL_ 52 HU_DATC_ZoneControl 0 "Off" 1 "Zone Activate" 2 "reserved" 3 "Invalid" ;
VAL_ 52 HU_DATC_CO2Set 0 "Function Off" 1 "Function On" 2 "reserved" 3 "Invalid" ;
VAL_ 52 DATC_SmartVentOnOffSet 0 "Function Off" 1 "Function On" 2 "reserved" 3 "Invalid" ;
VAL_ 52 DATC_ADSOnOffSet 0 "Function Off" 1 "Function On" 2 "reserved" 3 "Invalid" ;
VAL_ 52 HU_DATC_RearAutoDisp 0 "Auto Off" 1 "Auto On" 2 "Not Used" 3 "Invalid" ;
VAL_ 52 HU_DATC_RearOffDisp 0 "Off" 1 "Rear Normal" 2 "Rear Off Display" 3 "Invalid" ;
VAL_ 308 DATC_PwrInfo 0 "Off" 1 "Invalid" 2 "Invalid" 3 "IGN" 4 "Reserved" 5 "Reserved" 6 "Reserved" 7 "Reserved" 8 "Reserved" 9 "Reserved" 10 "Reserved" 11 "Reserved" 12 "Reserved" 13 "Reserved" 14 "Reserved" 15 "Invalid" ;
VAL_ 308 DATC_AltL 0 "off" 1 "on" 2 "Invalid" ;
VAL_ 308 DATC_CarInfo 0 "Wagon" 1 "Sedan" 2 "Invalid" ;
VAL_ 308 DATC_ParkingBrake 0 "Off" 1 "ON" 2 "Invaild" ;
VAL_ 308 DATC_LowFuelWarn 0 "Off" 1 "LowFuelWarning" 2 "Not used" 3 "Invaild" ;
VAL_ 308 DATC_Rear_Off_Disp 0 "off" 1 "normal mode" 2 "off display" 3 "invalid" ;
VAL_ 308 DATC_Rear_AutoDisp 0 "auto off" 1 "auto on" 2 "not used" 3 "invalid" ;
VAL_ 308 DATC_Rear_BlowerDisp 0 "Off" 1 "0 level" 2 "1 level" 3 "2 level" 4 "3 level" 5 "4 level" 6 "5 level" 7 "6 level" 8 "7 level" 9 "8 level" 10 "not used" 11 "not used" 12 "not used" 13 "not used" 14 "not used" 15 "invalid" ;
VAL_ 308 DATC_DrSeatWarmerDisp 0 "initial" 1 "OFF" 2 "Level 1" 3 "Level 2" 4 "Level 3" 5 "Reserved" 6 "Reserved" 7 "invalid" ;
VAL_ 308 DATC_SyncDisp 0 "initial" 1 "Sync On" 2 "Sync OFF" 3 "Reserved" 4 "Reserved" 5 "Reserved" 6 "Reserved" 7 "Reserved" 8 "Reserved" 9 "Reserved" 10 "Reserved" 11 "Reserved" 12 "Reserved" 13 "Reserved" 14 "Reserved" 15 "invalid" ;
VAL_ 308 DATC_RearDispCtrl 0 "initial" 1 "Rear Display On" 2 "Rear Display Off" 3 "Reserved" 4 "Reserved" 5 "Reserved" 6 "Reserved" 7 "Reserved" 8 "Reserved" 9 "Reserved" 10 "Reserved" 11 "Reserved" 12 "Reserved" 13 "Reserved" 14 "Reserved" 15 "invalid" ;
VAL_ 308 DATC_RearDrModeDisp 0 "OFF" 1 "VENT" 2 "BL" 3 "FLOOR" 4 "reserved" 5 "reserved" 6 "reserved" 7 "reserved" 8 "reserved" 9 "reserved" 10 "reserved" 11 "reserved" 12 "reserved" 13 "reserved" 14 "reserved" 15 "Invalid" ;
VAL_ 308 DATC_PsSeatWarmerDisp 0 "initial" 1 "OFF" 2 "Level 1" 3 "Level 2" 4 "Level 3" 5 "Reserved" 6 "Reserved" 7 "invalid" ;
VAL_ 308 DATC_DrVentSeatDisp 0 "initial" 1 "Off" 2 "Level 1" 3 "Level 2" 4 "Level 3" 5 "Reserved" 6 "Reserved" 7 "Invalid" ;
VAL_ 308 DATC_PSVentSeatDisp 0 "Initial" 1 "OFF" 2 "Level 1" 3 "Level 2" 4 "Level 3" 5 "Reserved" 6 "Reserved" 7 "Invalid" ;
VAL_ 308 DATC_RrDefLed 0 "off" 1 "On" 2 "Not used" 3 "invalid" ;
VAL_ 308 DATC_SmartVentOnOffStatus 0 "Function Off" 1 "Function On" 2 "reserved" 3 "Invalid" ;
VAL_ 308 DATC_ADSOnOffStatus 0 "Function Off" 1 "Function On" 2 "reserved" 3 "Invalid" ;
VAL_ 308 DATC_AcDisp_OSD 0 "AC OFF" 1 "AC On" 2 "Not used" 3 "Invalid" ;
VAL_ 308 DATC_PsModeDisp_OSD 0 "OFF" 1 "Vent" 2 "BL" 3 "Floor" 4 "Mix" 5 "Def" 6 "Auto Defog" 15 "Invalid" ;
VAL_ 308 DATC_ModeDisp_OSD 0 "OFF" 1 "Vent" 2 "BL" 3 "Floor" 4 "Mix" 5 "Def" 6 "Auto Defog" 15 "Invalid" ;
VAL_ 307 DATC_DiagMode 0 "Off(Default)" 1 "Diagnosis Code Displa" 2 "Not used" 3 "Invalid" ;
VAL_ 307 DATC_Rear_ChangeReqDisp 0 "Off" 1 "USER INPUT" 2 "reserved" 3 "Invalid" ;
VAL_ 307 DATC_Rear_ClimateScnDisp 0 "Deactivate" 1 "Activate" 2 "reserved" 3 "Invalid" ;
VAL_ 307 DATC_CO2OnOffStatus 0 "Function Off" 1 "Function On" 2 "Reserved" 3 "Invalid" ;
VAL_ 307 DATC_SelfDiagDisp 0 "Off(Blank Display)" 1 "Error Code Value(0~99)" 2 "Error Code Value(0~99)" 3 "Error Code Value(0~99)" 4 "Error Code Value(0~99)" 5 "Error Code Value(0~99)" 6 "Error Code Value(0~99)" 7 "Error Code Value(0~99)" 8 "Error Code Value(0~99)" 9 "Error Code Value(0~99)" 10 "Error Code Value(0~99)" 11 "Error Code Value(0~99)" 12 "Error Code Value(0~99)" 13 "Error Code Value(0~99)" 14 "Error Code Value(0~99)" 15 "Error Code Value(0~99)" 16 "Error Code Value(0~99)" 17 "Error Code Value(0~99)" 18 "Error Code Value(0~99)" 19 "Error Code Value(0~99)" 20 "Error Code Value(0~99)" 21 "Error Code Value(0~99)" 22 "Error Code Value(0~99)" 23 "Error Code Value(0~99)" 24 "Error Code Value(0~99)" 25 "Error Code Value(0~99)" 26 "Error Code Value(0~99)" 27 "Error Code Value(0~99)" 28 "Error Code Value(0~99)" 29 "Error Code Value(0~99)" 30 "Error Code Value(0~99)" 31 "Error Code Value(0~99)" 32 "Error Code Value(0~99)" 33 "Error Code Value(0~99)" 34 "Error Code Value(0~99)" 35 "Error Code Value(0~99)" 36 "Error Code Value(0~99)" 37 "Error Code Value(0~99)" 38 "Error Code Value(0~99)" 39 "Error Code Value(0~99)" 40 "Error Code Value(0~99)" 41 "Error Code Value(0~99)" 42 "Error Code Value(0~99)" 43 "Error Code Value(0~99)" 44 "Error Code Value(0~99)" 45 "Error Code Value(0~99)" 46 "Error Code Value(0~99)" 47 "Error Code Value(0~99)" 48 "Error Code Value(0~99)" 49 "Error Code Value(0~99)" 50 "Error Code Value(0~99)" 51 "Error Code Value(0~99)" 52 "Error Code Value(0~99)" 53 "Error Code Value(0~99)" 54 "Error Code Value(0~99)" 55 "Error Code Value(0~99)" 56 "Error Code Value(0~99)" 57 "Error Code Value(0~99)" 58 "Error Code Value(0~99)" 59 "Error Code Value(0~99)" 60 "Error Code Value(0~99)" 61 "Error Code Value(0~99)" 62 "Error Code Value(0~99)" 63 "Error Code Value(0~99)" 64 "Error Code Value(0~99)" 65 "Error Code Value(0~99)" 66 "Error Code Value(0~99)" 67 "Error Code Value(0~99)" 68 "Error Code Value(0~99)" 69 "Error Code Value(0~99)" 70 "Error Code Value(0~99)" 71 "Error Code Value(0~99)" 72 "Error Code Value(0~99)" 73 "Error Code Value(0~99)" 74 "Error Code Value(0~99)" 75 "Error Code Value(0~99)" 76 "Error Code Value(0~99)" 77 "Error Code Value(0~99)" 78 "Error Code Value(0~99)" 79 "Error Code Value(0~99)" 80 "Error Code Value(0~99)" 81 "Error Code Value(0~99)" 82 "Error Code Value(0~99)" 83 "Error Code Value(0~99)" 84 "Error Code Value(0~99)" 85 "Error Code Value(0~99)" 86 "Error Code Value(0~99)" 87 "Error Code Value(0~99)" 88 "Error Code Value(0~99)" 89 "Error Code Value(0~99)" 90 "Error Code Value(0~99)" 91 "Error Code Value(0~99)" 92 "Error Code Value(0~99)" 93 "Error Code Value(0~99)" 94 "Error Code Value(0~99)" 95 "Error Code Value(0~99)" 96 "Error Code Value(0~99)" 97 "Error Code Value(0~99)" 98 "Error Code Value(0~99)" 99 "Error Code Value(0~99)" 100 "Error Code Value(0~99)" 255 "Invalid" ;
VAL_ 307 DATC_RearBlwDisp_OSD 0 "Off" 1 "0 Level" 2 "1 Level" 3 "2 Level" 4 "3 Level" 5 "4 Level" 6 "5 Level" 7 "6 Level" 8 "7 Level" 9 "8 Level" 15 "Invalid" ;
VAL_ 307 DATC_AqsLevelOut 0 "Off" 1 "1 level" 2 "1 level" 3 "3 level" 4 "4 level" 5 "5 level" 6 "reserved" 7 "reserved" 8 "reserved" 9 "reserved" 10 "reserved" 11 "reserved" 12 "reserved" 13 "reserved" 14 "reserved" 15 "Invalid" ;
VAL_ 307 DATC_RearModeDisp 0 "Off" 1 "Vent" 2 "BL" 3 "Floor" 15 "Invalid" ;
VAL_ 307 DATC_RearPsModeDisp 0 "Off" 1 "Vent" 2 "BL" 3 "Floor" 15 "Invalid" ;
VAL_ 307 DATC_FrontBlwDisp_Ps 0 "Off" 1 "0 Level" 2 "1 Level" 3 "2 Level" 4 "3 Level" 5 "4 Level" 6 "5 Level" 7 "6 Level" 8 "7 Level" 9 "8 Level" 10 "Reserved" 11 "Reserved" 12 "Reserved" 13 "Reserved" 14 "Reserved" 15 "Invalid" ;
VAL_ 307 DATC_AutoDisp_Ps 0 "Off" 1 "On" 2 "Reserved" 3 "Invalid" ;
VAL_ 307 DATC_RearModeDisp_OSD 0 "Off" 1 "Vent" 2 "B_L" 3 "Floor" 15 "Invalid" ;
VAL_ 307 DATC_RearPSModeDisp_OSD 0 "Off" 1 "Vent" 2 "B_L" 3 "Floor" 15 "Invalid" ;
VAL_ 307 DATC_FrontBlwDisp_OSD 0 "Off" 1 "0 Level" 2 "1 Level" 3 "2 Level" 4 "3 Level" 5 "4 Level" 6 "5 Level" 7 "6 Level" 8 "7 Level" 9 "8 Level" 15 "Invalid" ;
VAL_ 307 DATC_FrontBlwDispPs_OSD 0 "Off" 1 "0 Level" 2 "1 Level" 3 "2 Level" 4 "3 Level" 5 "4 Level" 6 "5 Level" 7 "6 Level" 8 "7 Level" 9 "8 Level" 15 "Invalid" ;
VAL_ 307 DATC_Variant 255 "Invalid" ;
VAL_ 306 DATC_ModeDisp 0 "Off" 1 "Vent" 2 "Vent_Floor" 3 "Floor" 4 "Defog_Floor" 5 "Max Defog" 6 "Auto Defog" 7 "Def_Vent" 8 "Def_Floor" 9 "Def_Vent_Floor" 10 "Def" 11 "Reserved" 12 "Reserved" 13 "Reserved" 14 "Reserved" 15 "Invalid" ;
VAL_ 306 DATC_TempUnit 0 "Off" 1 "Centigrade" 2 "Fahrenheit" 3 "invalid" ;
VAL_ 306 DATC_AutoDisp 0 "Off" 1 "AUTO ON" 2 "reserved" 3 "Invalid" ;
VAL_ 306 DATC_IntakeDisp 0 "REC OFF" 1 "REC ON" 2 "reserved" 3 "Invalid" ;
VAL_ 306 DATC_ChangeReqDisp 0 "OFF" 1 "USER INPUT" 2 "reserved" 3 "invalid" ;
VAL_ 306 DATC_AcDisp 0 "OFF" 1 "AC ON" 2 "reserved" 3 "Invalid" ;
VAL_ 306 DATC_AqsDisp 0 "OFF" 1 "AQC ON" 2 "reserved" 3 "Invalid" ;
VAL_ 306 DATC_ClimateScnDisp 0 "Deactivate" 1 "Activate" 2 "reserved" 3 "Invalid" ;
VAL_ 306 DATC_DualDisp 0 "OFF" 1 "DUAL ON" 2 "reserved" 3 "Invalid" ;
VAL_ 306 DATC_OffDisp 0 "Off" 1 "Normal Display" 2 "OFF Display" 3 "Invalid" ;
VAL_ 306 DATC_OpSts 0 "DATC Off (Power Down)" 1 "DATC Normal" 2 "DATC System Off (Blower Off)" 3 "DATC Self Diagnosis" 4 "AQS Sensitive Level" 5 "reserved" 6 "reserved" 7 "Inavalid" ;
VAL_ 306 DATC_RearManual 0 "Null" 1 "Enable" 2 "Disable" 3 "(Invalid)" ;
VAL_ 306 DATC_FrDefLed 0 "Off" 1 "On" 2 "Reserved" 3 "Invalid" ;
VAL_ 306 DATC_SmartVentDisp 0 "Off" 1 "Smart Ventilation" 2 "Smart CO2 Ventilation" 3 "Invalid" ;
VAL_ 306 DATC_AutoDefogBlink 0 "Off" 1 "Blinking" 2 "reserved" 3 "Invalid" ;
VAL_ 306 DATC_ADSDisp 0 "ADS Deactivated" 1 "ADS Activated" 2 "reserved" 3 "Invalid" ;
VAL_ 306 DATC_IonClean 0 "Off" 1 "CLEAN" 2 "ION" 3 "Invalid" ;
VAL_ 306 DATC_CO2Warning 0 "Off" 1 "CO2 Warning" 2 "reserved" 3 "Invalid" ;
VAL_ 306 DATC_SubBlowerDisp 0 "Off" 1 "0 level" 2 "1 level" 3 "2 level" 4 "3 level" 5 "4 level" 6 "5 level" 7 "6 level" 8 "7 level" 9 "8 level" 10 "not used" 11 "not used" 12 "not used" 13 "not used" 14 "not used" 15 "invalid" ;
VAL_ 306 DATC_BeepReq 0 "beep off" 1 "beep1 on" 2 "beep2 on" 3 "Beep1 Off" 4 "Beep2 Off" 15 "Invalid" ;
VAL_ 306 DATC_MainBlowerDisp 0 "Off" 1 "0 level" 2 "1 level" 3 "2 level" 4 "3 level" 5 "4 level" 6 "5 level" 7 "6 level" 8 "7 level" 9 "8 level" 10 "reserved" 11 "reserved" 12 "reserved" 13 "reserved" 14 "reserved" 15 "Invalid" ;
VAL_ 306 DATC_PsModeDisp 0 "Off" 1 "VENT" 2 "BL" 3 "FLOOR" 4 "MIX" 5 "DEF" 6 "AUTO DEFOG" 7 "reserved" 8 "reserved" 9 "reserved" 10 "reserved" 11 "reserved" 12 "reserved" 13 "reserved" 14 "reserved" 15 "Invalid" ;
VAL_ 1329 DATC_AmbientTemp_C 0 "Off ( Blank Display)" 1 "Not Used(BlankDisplay )" 203 "Not used" 204 "Not used" 205 "Not used" 206 "Not used" 207 "Not used" 208 "Not used" 209 "Not used" 210 "Not used" 211 "Not used" 212 "Not used" 213 "Not used" 214 "Not used" 215 "Not used" 216 "Not used" 217 "Not used" 218 "Not used" 219 "Not used" 220 "Not used" 221 "Not used" 222 "Not used" 223 "Not used" 224 "Not used" 225 "Not used" 226 "Not used" 227 "Not used" 228 "Not used" 229 "Not used" 230 "Not used" 231 "Not used" 232 "Not used" 233 "Not used" 234 "Not used" 235 "Not used" 236 "Not used" 237 "Not used" 238 "Not used" 239 "Not used" 240 "Not used" 241 "Not used" 242 "Not used" 243 "Not used" 244 "Not used" 245 "Not used" 246 "Not used" 247 "Not used" 248 "Not used" 249 "Not used" 250 "Not used" 251 "Not used" 252 "Not used" 253 "Not used" 254 "Sensor Error ( -- Display)" 255 "invalid" ;
VAL_ 1329 DATC_AmbientTemp_F 0 "Off ( Blank Display)" 1 "Not Used(BlankDisplay )" 183 "Not used" 184 "Not used" 185 "Not used" 186 "Not used" 187 "Not used" 188 "Not used" 189 "Not used" 190 "Not used" 191 "Not used" 192 "Not used" 193 "Not used" 194 "Not used" 195 "Not used" 196 "Not used" 197 "Not used" 198 "Not used" 199 "Not used" 200 "Not used" 201 "Not used" 202 "Not used" 203 "Not used" 204 "Not used" 205 "Not used" 206 "Not used" 207 "Not used" 208 "Not used" 209 "Not used" 210 "Not used" 211 "Not used" 212 "Not used" 213 "Not used" 214 "Not used" 215 "Not used" 216 "Not used" 217 "Not used" 218 "Not used" 219 "Not used" 220 "Not used" 221 "Not used" 222 "Not used" 223 "Not used" 224 "Not used" 225 "Not used" 226 "Not used" 227 "Not used" 228 "Not used" 229 "Not used" 230 "Not used" 231 "Not used" 232 "Not used" 233 "Not used" 234 "Not used" 235 "Not used" 236 "Not used" 237 "Not used" 238 "Not used" 239 "Not used" 240 "Not used" 241 "Not used" 242 "Not used" 243 "Not used" 244 "Not used" 245 "Not used" 246 "Not used" 247 "Not used" 248 "Not used" 249 "Not used" 250 "Not used" 251 "Not used" 252 "Not used" 253 "Not used" 254 "Sensor Error ( -- Display)" 255 "invalid" ;
VAL_ 305 DATC_DrTempDispC 0 "Off (Blank display)" 1 "reserved(blank display)" 255 "Invalid" ;
VAL_ 305 DATC_Rear_DrTempDispC 0 "Off (Blank display)" 1 "reserved(blank display)" 255 "Invalid" ;
VAL_ 305 DATC_DrTempDispF 0 "Off (Blank display)" 1 "reserved(blank display)" 255 "Invalid" ;
VAL_ 305 DATC_Rear_DrTempDispF 0 "Off (Blank display)" 1 "reserved(blank display)" 255 "Invalid" ;
VAL_ 305 DATC_PsTempDispC 0 "Off (Blank display)" 1 "reserved(blank display)" 255 "Invalid" ;
VAL_ 305 Datc_RearPsTempDispC 0 "Off (Blank Display)" 1 "Reserved(Blank DIsplay)" 2 "PHY" 3 "PHY" 4 "PHY" 5 "PHY" 6 "PHY" 7 "PHY" 8 "PHY" 9 "PHY" 10 "PHY" 11 "PHY" 12 "PHY" 13 "PHY" 14 "PHY" 15 "PHY" 16 "PHY" 17 "PHY" 18 "PHY" 19 "PHY" 20 "PHY" 21 "PHY" 22 "PHY" 23 "PHY" 24 "PHY" 25 "PHY" 26 "PHY" 27 "PHY" 28 "PHY" 29 "PHY" 30 "PHY" 31 "PHY" 32 "PHY" 33 "PHY" 34 "PHY" 35 "PHY" 36 "PHY" 255 "Invalid" ;
VAL_ 305 DATC_PsTempDispF 0 "Off (Blank display)" 1 "reserved(blank display)" 255 "Invalid" ;
VAL_ 305 DATC_RearPsTempDispF 0 "0FF(Blank Display)" 1 "Reserved (Blank Display)" 2 "Phy" 3 "Phy" 4 "Phy" 5 "Phy" 6 "Phy" 7 "Phy" 8 "Phy" 9 "Phy" 10 "Phy" 11 "Phy" 12 "Phy" 13 "Phy" 14 "Phy" 15 "Phy" 16 "Phy" 17 "Phy" 18 "Phy" 19 "Phy" 20 "Phy" 21 "Phy" 22 "Phy" 23 "Phy" 24 "Phy" 25 "Phy" 26 "Phy" 27 "Phy" 28 "Phy" 29 "Phy" 30 "Phy" 31 "Phy" 32 "Phy" 33 "Phy" 34 "Phy" 35 "Phy" 36 "Phy" 255 "Invalid" ;
VAL_ 304 DATC_Type 0 "Null" 1 "DATC" 2 "FATC" 3 "MTC" 255 "(invalid)" ;
VAL_ 304 DATC_VerMMMajor 0 "Null" 255 "(invalid)" ;
VAL_ 304 DATC_VerMMMinor 0 "Null" 255 "(invalid)" ;
VAL_ 304 DATC_VerBDFMajor 0 "Null" 255 "(invalid)" ;
VAL_ 304 DATC_VerBDMinor 0 "Null" 255 "(invalid)" ;
VAL_ 304 DATC_VerCSMajor 0 "Null" 255 "(invalid)" ;
VAL_ 304 DATC_VerCSMinor 0 "Null" 255 "(invalid)" ;
VAL_ 291 NV_DS_Curve 0 "off" 1 "Right" 2 "Left" 3 "Right curve continuously" 4 "Left curve continuously" 5 "Reserved" 6 "Reserved" 7 "Reserved" 8 "Reserved" 9 "Reserved" 10 "Reserved" 11 "Reserved" 12 "Reserved" 13 "Reserved" 14 "Reserved" 15 "invalid" ;
VAL_ 291 NV_DS_Merge 0 "off" 1 "right" 2 "left" 3 "Reserved" 4 "Reserved" 5 "Reserved" 6 "Reserved" 7 "Reserved" 8 "Reserved" 9 "Reserved" 10 "Reserved" 11 "Reserved" 12 "Reserved" 13 "Reserved" 14 "Reserved" 15 "invalid" ;
VAL_ 291 NV_DS_RailCross 0 "off" 1 "on" 2 "not used" 3 "invalid" ;
VAL_ 291 NV_DS_FallingRocks 0 "off" 1 "on" 2 "not used" 3 "invalid" ;
VAL_ 291 NV_DS_SchoolZone 0 "off" 1 "on" 2 "not used" 3 "invalid" ;
VAL_ 291 NV_DS_AccidentBlack 0 "off" 1 "on" 2 "not used" 3 "invalid" ;
VAL_ 291 NV_DS_SpeedBump 0 "off" 1 "on" 2 "not used" 3 "invalid" ;
VAL_ 291 NV_DS_RoadKill 0 "off" 1 "on" 2 "not used" 3 "invalid" ;
VAL_ 291 NV_DS_Downhill 0 "off" 1 "on" 2 "not used" 3 "invalid" ;
VAL_ 291 NV_DS_Fog 0 "off" 1 "on" 2 "not used" 3 "invalid" ;
VAL_ 291 NV_Display_TG 0 "off" 1 "on" 2 "not used" 3 "invalid" ;
VAL_ 291 NV_Charge 1 "10 won" 2 "20 won" 65534 "655340 won" 65535 "invalid" ;
VAL_ 291 NV_Charge_Unit 0 "Off" 1 "KRW" 2 "USD(Cent)" 3 "JPY" 4 "EUR" 5 "CNY" 6 "AUD" 7 "CAD" 8 "NZD" 9 "reserved" 10 "reserved" 11 "reserved" 12 "reserved" 13 "reserved" 14 "reserved" 15 "Invalid" ;
VAL_ 291 TBT_BarGraph100Level 254 "Not Displayed" 255 "initial value, invald" ;
VAL_ 290 NV_SD_SpdLimit2 0 "physical value" 1 "physical value" 2 "physical value" 3 "physical value" 4 "physical value" 5 "physical value" 6 "physical value" 7 "physical value" 8 "physical value" 9 "physical value" 10 "physical value" 11 "physical value" 12 "physical value" 13 "physical value" 14 "physical value" 15 "invalid" ;
VAL_ 290 NV_SD_SpdLimit1 0 "physical value" 1 "physical value" 2 "physical value" 3 "physical value" 4 "physical value" 5 "physical value" 6 "physical value" 7 "physical value" 8 "physical value" 9 "physical value" 10 "physical value" 11 "physical value" 12 "physical value" 13 "physical value" 14 "physical value" 15 "invalid" ;
VAL_ 290 NV_SD_EtcCam 0 "off" 1 "on" 2 "not used" 3 "invalid" ;
VAL_ 290 NV_SD_SpdLimit3 0 "physical value" 1 "physical value" 2 "physical value" 3 "physical value" 4 "physical value" 5 "physical value" 6 "physical value" 7 "physical value" 8 "physical value" 9 "physical value" 10 "physical value" 11 "physical value" 12 "physical value" 13 "physical value" 14 "physical value" 15 "invalid" ;
VAL_ 290 NV_SD_SignCam 0 "off" 1 "on" 2 "not used" 3 "invalid" ;
VAL_ 290 NV_SD_SignOverCam 0 "off" 1 "on" 2 "not used" 3 "invalid" ;
VAL_ 290 NV_SD_MobileCam 0 "off" 1 "on" 2 "not used" 3 "invalid" ;
VAL_ 290 NV_SD_FixedCam 0 "off" 1 "on" 2 "not used" 3 "invalid" ;
VAL_ 290 NV_SD_OverLoadCam 0 "off" 1 "on" 2 "not used" 3 "invalid" ;
VAL_ 290 NV_SD_ParkCam 0 "off" 1 "on" 2 "not used" 3 "invalid" ;
VAL_ 290 NV_SD_CutInCam 0 "off" 1 "on" 2 "not used" 3 "invalid" ;
VAL_ 290 NV_SD_BusOnlyCam 0 "off" 1 "on" 2 "not used" 3 "invalid" ;
VAL_ 290 NV_SD_ShoulderCam 0 "off" 1 "on" 2 "not used" 3 "invalid" ;
VAL_ 290 NV_SD_TrafficCam 0 "off" 1 "on" 2 "not used" 3 "invalid" ;
VAL_ 290 NV_SD_PlateRcgCam 0 "off" 1 "on" 2 "not used" 3 "invalid" ;
VAL_ 286 Navi_TBTInfo 255 "Invalid" ;
VAL_ 29 SYS_CLUVer 0 "Off" 65535 "Invalid" ;
VAL_ 29 CLU_ClockInfoReq 0 "off" 1 "Request" 2 "Not used" 3 "Invalid" ;
VAL_ 29 CLU_DateInfoReq 0 "off" 1 "Request" 2 "Not used" 3 "Invalid" ;
VAL_ 27 SYS_AMPVer 0 "Off" 65535 "Invalid" ;
VAL_ 23 C_ADrLNValueSet 0 "Default" 1 "Off" 2 "Vehicle Speed On" 3 "Shift Lever On" 4 "Reserved" 5 "Reserved" 6 "Reserved" 7 "Invalid" ;
VAL_ 23 C_ADrUNValueSet 0 "Default" 1 "Off" 2 "Key Out On" 3 "Shift Lever On" 4 "Override" 5 "Reserved" 6 "Reserved" 7 "Invalid" ;
VAL_ 23 SYS_Ver_Req 0 "Off" 1 "Version Req" 2 "reserved" 3 "Invalid" ;
VAL_ 23 C_IMSRValueReq 0 "Off" 1 "Real value Request" 2 "reserved" 3 "Invalid" ;
VAL_ 23 C_PSMNValueSet 0 "Default" 1 "Seat Off" 2 "Seat On" 3 "Invalid" ;
VAL_ 23 C_SCMNValueSet 0 "Default" 1 "Steering Off" 2 "Steeringt On" 3 "Invalid" ;
VAL_ 23 C_ADrLURValueReq 0 "Off" 1 "Real value Request" 2 "reserved" 3 "Invalid" ;
VAL_ 23 C_ABuzzerNValueSet 0 "Default" 1 "Answer Buzzer Off" 2 "Anwer Buzzer On" 3 "Invalid" ;
VAL_ 23 C_AlarmRValueReq 0 "Off" 1 "Real value Request" 2 "reserved" 3 "Invalid" ;
VAL_ 23 C_ArmWKeyNValueSet 0 "Default" 1 "Off" 2 "Arm with Key" 3 "Invalid" ;
VAL_ 23 C_TwUnRValueReq 0 "Off" 1 "Real value Request" 2 "reserved" 3 "Invalid" ;
VAL_ 23 C_TwUnNValueSet 0 "Default" 1 "Twice Unlock Off" 2 "Twice Unlock On" 3 "Invalid" ;
VAL_ 23 C_AutoMRFoldRValueReq 0 "Off" 1 "Real value request" 2 "reserved" 3 "Invalid" ;
VAL_ 23 C_AutoMRFoldNValueSet 0 "Default" 1 "Auto Mirror Fold Off" 2 "Auto Mirror Fold On" 3 "Invalid" ;
VAL_ 23 C_ADrLRValueReq 0 "Off" 1 "Real value Request" 2 "not used" 3 "Invalid" ;
VAL_ 23 C_ArmWKeyRValueReq 0 "Off" 1 "Real value Request" 2 "not used" 3 "Invalid" ;
VAL_ 23 C_ABuzzerRValueReq 0 "Off" 1 "Real value Request" 2 "not used" 3 "Invalid" ;
VAL_ 23 C_ADrURValueReq 0 "Off" 1 "Real value Request" 2 "not used" 3 "Invalid" ;
VAL_ 23 C_PSMRValueReq 0 "Off" 1 "Real value Request" 2 "not used" 3 "Invalid" ;
VAL_ 23 C_SCMRValueReq 0 "Off" 1 "Real value Request" 2 "not used" 3 "Invalid" ;
VAL_ 277 TBT_Display_Type 0 "No Symbol" 1 "No info" 16 "Turn Combination 2" 17 "Exit Right" 18 "Exit Left" 19 "Exit Right Combination 1" 20 "Exit Left Combination 1" 21 "Exit Right Combination 2" 22 "Exit Left Combination 2" 23 "Service Road Right" 24 "Service Road Left" 25 "Fork-2" 26 "Fork-3" 27 "Roundabout Trs Right" 28 "Roundabout Trs Left" 29 "Square Trs Right" 30 "Square Trs Left" 31 "U turn" 2 "Direction to Destination" 32 "Exit Roundabout Trs Right" 33 "Exit Roundabout Trs Left" 34 "Prepare Turn" 35 "Prepare Roundabout" 36 "Prepare Exit" 37 "Prepare Square" 38 "Prepare U Turn" 39 "Exit Right Ramp Up" 40 "Exit Right Ramp Down" 41 "Exit Left Ramp Up" 42 "Exit Left Ramp Down" 43 "Overpass Right" 44 "Overpass Left" 45 "Underpass Right" 46 "Underpass Left" 47 "Schematic Diagram" 3 "Arrived" 4 "Near Destination" 66 "Turn 1 o&apos;clock" 67 "Turn Right" 68 "Turn 4 o&apos;clock" 69 "Turn 8 o&apos;clock" 70 "Turn Left" 71 "Turn 11 o&apos;clock" 72 "U Turn (L)" 73 "U Turn (R)" 74 "P Turn (L)" 75 "P Turn (R)" 76 "Permitted Left Turn" 5 "Arrived Destination Off Map" 80 "Aside Overpass (C)" 81 "Aside Overpass (R)" 82 "Aside Overpass (L)" 83 "Aside Underpass (C)" 84 "Aside Underpass (R)" 85 "Aside Underpass (L)" 86 "Into Overpass (C)" 87 "Into Overpass (R)" 88 "Into Overpass (L)" 89 "Into Underpass (C)" 90 "Into Underpass (R)" 91 "Into Underpass (L)" 6 "Off Road" 96 "Roundabout (R12)" 97 "Roundabout (R1)" 98 "Roundabout (R2)" 99 "Roundabout (R3)" 100 "Roundabout (R4)" 101 "Roundabout (R5)" 102 "Roundabout (R6)" 103 "Roundabout (R7)" 104 "Roundabout (R8)" 105 "Roundabout (R9)" 106 "Roundabout (R10)" 107 "Roundabout (R11)" 7 "Off Map" 112 "Destination (C)" 113 "Destination (R)" 114 "Destination (L)" 115 "Waypoint1 (C)" 116 "Waypoint1 (R)" 117 "Waypoint1 (L)" 118 "Waypoint2 (C)" 119 "Waypoint2 (R)" 120 "Waypoint2 (L)" 121 "Waypoint3 (C)" 122 "Waypoint3 (R)" 123 "Waypoint3 (L)" 124 "Waypoint4 (C)" 125 "Waypoint4 (R)" 126 "Waypoint4 (L)" 8 "No Route Guidance (Compass)" 128 "waypoint5(C)" 129 "waypoint5(L)" 130 "waypoint5(R)" 131 "waypoint6(C)" 132 "waypoint6(L)" 133 "waypoint6(R)" 134 "waypoint7(C)" 135 "waypoint7(L)" 136 "waypoint7(R)" 9 "Calc Route" 144 "Fork-2 Right" 145 "Fork-2 Left" 146 "Fork-SR Straight" 147 "Fork-SR Right" 148 "Fork-SL Straight" 149 "Fork-SL Left" 10 "Recalc Route" 160 "FWY Entrance (C)" 161 "FWY Entrance (R)" 162 "FWY Entrance (L)" 163 "FWY Exit (C)" 164 "FWY Exit (R)" 165 "FWY Exit (L)" 166 "CHWY Entrance (C)" 167 "CHWY Entrance (R)" 168 "CHWY Entrance (L)" 169 "CHWY Exit (C)" 170 "CHWY Exit (R)" 171 "CHWY Exit (L)" 172 "Main Road Entrance (C)" 173 "Main Road Entrance (R)" 174 "Main Road Entrance (L)" 11 "Follow Street" 176 "Ferry" 177 "Tunnel" 178 "Tollgate" 179 "IC" 180 "JC" 181 "SA" 182 "PA" 183 "SA Entrance" 184 "Coin Tollgate" 185 "JC Exit (C)" 186 "JC Exit (R)" 187 "JC Exit (L)" 12 "Change Lane" 192 "Roundabout (L12)" 193 "Roundabout (L1)" 194 "Roundabout (L2)" 195 "Roundabout (L3)" 196 "Roundabout (L4)" 197 "Roundabout (L5)" 198 "Roundabout (L6)" 199 "Roundabout (L7)" 200 "Roundabout (L8)" 201 "Roundabout (L9)" 202 "Roundabout (L10)" 203 "Roundabout (L11)" 13 "Turn" 14 "Turn On Main Road" 15 "Turn Combination 1" 255 "Invalid" ;
VAL_ 277 TBT_Side_Street 65535 "Invalid" ;
VAL_ 277 TBT_Direction 255 "Invalid" ;
VAL_ 277 TBT_Distance_Turn_Point 0 "0" 65535 "Invalid" ;
VAL_ 277 TBT_Combined_Side_Street 0 "No Combined" 1 "Right Combined" 2 "Left combined" 3 "Bothside" 4 "Reserved" 5 "Reserved" 6 "Reserved" 7 "Reserved" 8 "Reserved" 9 "Reserved" 10 "Reserved" 11 "Reserved" 12 "Reserved" 13 "Reserved" 14 "Reserved" 15 "Invalid" ;
VAL_ 277 TBT_Scale 0 "Meter" 1 "Kilometer" 2 "Mile" 3 "Feet" 4 "yard" 15 "Invalid" ;
VAL_ 277 TBT_DistancetoTurnPoint 0 "0" 1 "number of tuning point" 2 "number of tuning point" 3 "number of tuning point" 4 "number of tuning point" 5 "number of tuning point" 6 "number of tuning point" 7 "number of tuning point" 8 "number of tuning point" 9 "number of tuning point" 10 "Reserved" 11 "Reserved" 12 "Reserved" 13 "Reserved" 14 "Reserved" 15 "Invalid" ;
VAL_ 277 TBT_Bar_Graph_Level 0 "0%" 11 "Reserved" 12 "Reserved" 13 "Reserved" 14 "Reserved" 15 "Invalid" ;
VAL_ 276 HU_OpState 0 "Initial" 1 "iBox App" 2 "DLNA" 3 "iBox AV" 4 "Internet" 5 "MoreLike This" 6 "ZUNE" 7 "Juke Box" 8 "Bluetooth Audio" 9 "NAVI TBT" 10 "AV OFF" 11 "AV PowerOFF" 12 "MY music (ripping)" 13 "Internet Radio(Pandora)" 14 "Dispaly Navi" 15 "JukeBox-vide" 16 "Aha Radio" 17 "FM" 18 "FM1" 19 "FM2" 20 "AM" 21 "LW" 22 "MW" 23 "BSMing" 24 "FMA" 25 "AMA" 26 "Emergency Cal" 27 "ACN" 28 "Center Call" 29 "Bluelink Assistant" 30 "reserved" 31 "reserved" 32 "reserved" 33 "FM(HD)" 34 "FM1(HD)" 35 "FM2(HD)" 36 "AM(HD)" 39 "Reserved" 40 "Reserved" 41 "Reserved" 42 "Mozen Incoming call" 43 "Mozen Active call" 44 "Mozen Hangup" 45 "Mozen outgoing call" 47 "reserved" 48 "reserved" 49 "XM" 50 "XM1" 51 "XM2" 52 "XM3" 53 "reserved" 54 "DAB" 55 "DAB1" 56 "DAB2" 57 "DAB3" 59 "D-Radio Receiving" 60 "D-Radio Signal Weak" 61 "D-Radio Signal Lost" 64 "reserved" 65 "DMB1 TV" 66 "DMB1 Radio" 67 "DMB2 TV" 68 "DMB2 Radio" 69 "DMB(Reserved) TV" 70 "DMB Radio" 71 "DMB Searching" 72 "reserved" 73 "reserved" 74 "D-TV No Channe" 75 "D-TV Receiving" 76 "D-TV Signal Weak" 77 "D-TV Signal Lost" 80 "CD" 81 "CD Audio" 82 "CD MP3" 83 "DVD Audio" 84 "DVD-V" 85 "VCD" 86 "DVDVideo" 87 "CDCCD" 88 "CDCMP3" 89 "Disc reading" 90 "Virtual DiscMTSOnly" 91 "CD-video" 92 "DVD-music" 93 "READING CD" 94 "LOADING CD" 95 "DISC Error" 96 "Loading" 97 "iPod" 98 "USB" 99 "AUX" 100 "USB Video" 101 "USB Music" 102 "USB Photo" 104 "IPOD Reading" 105 "USB Reading" 106 "Reading Media" 107 "AUX-audio" 108 "AUX-video" 109 "AUX no signal" 112 "reserved" 113 "Incoming cal" 114 "Active call" 115 "Hangup" 116 "Last Call" 117 "Disconnection" 118 "IVR call for NA" 119 "SOS call for NA" 120 "IVR call for CHN" 121 "SOS call for CHN" 122 "BlueLink Mode" 123 "MOZEN Mode for cubis -T" 124 "Reserved" 125 "Reserved" 126 "Reserved" 127 "Invalid" ;
VAL_ 276 HU_Navi_On_Off 0 "Off" 1 "On" ;
VAL_ 276 HU_Preset_Number 0 "Off" 1 "Preset No. 1~30" 2 "Preset No. 1~30" 3 "Preset No. 1~30" 4 "Preset No. 1~30" 5 "Preset No. 1~30" 6 "Preset No. 1~30" 7 "Preset No. 1~30" 8 "Preset No. 1~30" 9 "Preset No. 1~30" 10 "Preset No. 1~30" 11 "Preset No. 1~30" 12 "Preset No. 1~30" 13 "Preset No. 1~30" 14 "Preset No. 1~30" 15 "Preset No. 1~30" 16 "Preset No. 1~30" 17 "Preset No. 1~30" 18 "Preset No. 1~30" 19 "Preset No. 1~30" 20 "Preset No. 1~30" 21 "Preset No. 1~30" 22 "Preset No. 1~30" 23 "Preset No. 1~30" 24 "Preset No. 1~30" 25 "Preset No. 1~30" 26 "Preset No. 1~30" 27 "Preset No. 1~30" 28 "Preset No. 1~30" 29 "Preset No. 1~30" 30 "Preset No. 1~30" 31 "Invalid" ;
VAL_ 276 HU_Tuner_Area 0 "Off" 1 "Korea(CHN, MES)" 2 "USA(CAN)" 3 "Europe" 4 "Japan" 5 "Columbia" 6 "South America" 7 "Invalid" ;
VAL_ 276 HU_Track_Number 65535 "Invalid" ;
VAL_ 276 HU_Play_time_Sec 0 "0~59 sec." 1 "0~59 sec." 2 "0~59 sec." 3 "0~59 sec." 4 "0~59 sec." 5 "0~59 sec." 6 "0~59 sec." 7 "0~59 sec." 8 "0~59 sec." 9 "0~59 sec." 10 "0~59 sec." 11 "0~59 sec." 12 "0~59 sec." 13 "0~59 sec." 14 "0~59 sec." 15 "0~59 sec." 16 "0~59 sec." 17 "0~59 sec." 18 "0~59 sec." 19 "0~59 sec." 20 "0~59 sec." 21 "0~59 sec." 22 "0~59 sec." 23 "0~59 sec." 24 "0~59 sec." 25 "0~59 sec." 26 "0~59 sec." 27 "0~59 sec." 28 "0~59 sec." 29 "0~59 sec." 30 "0~59 sec." 31 "0~59 sec." 32 "0~59 sec." 33 "0~59 sec." 34 "0~59 sec." 35 "0~59 sec." 36 "0~59 sec." 37 "0~59 sec." 38 "0~59 sec." 39 "0~59 sec." 40 "0~59 sec." 41 "0~59 sec." 42 "0~59 sec." 43 "0~59 sec." 44 "0~59 sec." 45 "0~59 sec." 46 "0~59 sec." 47 "0~59 sec." 48 "0~59 sec." 49 "0~59 sec." 50 "0~59 sec." 51 "0~59 sec." 52 "0~59 sec." 53 "0~59 sec." 54 "0~59 sec." 55 "0~59 sec." 56 "0~59 sec." 57 "0~59 sec." 58 "0~59 sec." 59 "0~59 sec." 63 "Invalid" ;
VAL_ 276 HU_Play_time_Min 0 "0~59 min." 1 "0~59 min." 2 "0~59 min." 3 "0~59 min." 4 "0~59 min." 5 "0~59 min." 6 "0~59 min." 7 "0~59 min." 8 "0~59 min." 9 "0~59 min." 10 "0~59 min." 11 "0~59 min." 12 "0~59 min." 13 "0~59 min." 14 "0~59 min." 15 "0~59 min." 16 "0~59 min." 17 "0~59 min." 18 "0~59 min." 19 "0~59 min." 20 "0~59 min." 21 "0~59 min." 22 "0~59 min." 23 "0~59 min." 24 "0~59 min." 25 "0~59 min." 26 "0~59 min." 27 "0~59 min." 28 "0~59 min." 29 "0~59 min." 30 "0~59 min." 31 "0~59 min." 32 "0~59 min." 33 "0~59 min." 34 "0~59 min." 35 "0~59 min." 36 "0~59 min." 37 "0~59 min." 38 "0~59 min." 39 "0~59 min." 40 "0~59 min." 41 "0~59 min." 42 "0~59 min." 43 "0~59 min." 44 "0~59 min." 45 "0~59 min." 46 "0~59 min." 47 "0~59 min." 48 "0~59 min." 49 "0~59 min." 50 "0~59 min." 51 "0~59 min." 52 "0~59 min." 53 "0~59 min." 54 "0~59 min." 55 "0~59 min." 56 "0~59 min." 57 "0~59 min." 58 "0~59 min." 59 "0~59 min." 127 "Invalid" ;
VAL_ 276 HU_Play_time_Hour 0 "0~99 Hour" 1 "0~99 Hour" 2 "0~99 Hour" 3 "0~99 Hour" 4 "0~99 Hour" 5 "0~99 Hour" 6 "0~99 Hour" 7 "0~99 Hour" 8 "0~99 Hour" 9 "0~99 Hour" 10 "0~99 Hour" 11 "0~99 Hour" 12 "0~99 Hour" 13 "0~99 Hour" 14 "0~99 Hour" 15 "0~99 Hour" 16 "0~99 Hour" 17 "0~99 Hour" 18 "0~99 Hour" 19 "0~99 Hour" 20 "0~99 Hour" 21 "0~99 Hour" 22 "0~99 Hour" 23 "0~99 Hour" 24 "0~99 Hour" 25 "0~99 Hour" 26 "0~99 Hour" 27 "0~99 Hour" 28 "0~99 Hour" 29 "0~99 Hour" 30 "0~99 Hour" 31 "0~99 Hour" 32 "0~99 Hour" 33 "0~99 Hour" 34 "0~99 Hour" 35 "0~99 Hour" 36 "0~99 Hour" 37 "0~99 Hour" 38 "0~99 Hour" 39 "0~99 Hour" 40 "0~99 Hour" 41 "0~99 Hour" 42 "0~99 Hour" 43 "0~99 Hour" 44 "0~99 Hour" 45 "0~99 Hour" 46 "0~99 Hour" 47 "0~99 Hour" 48 "0~99 Hour" 49 "0~99 Hour" 50 "0~99 Hour" 51 "0~99 Hour" 52 "0~99 Hour" 53 "0~99 Hour" 54 "0~99 Hour" 55 "0~99 Hour" 56 "0~99 Hour" 57 "0~99 Hour" 58 "0~99 Hour" 59 "0~99 Hour" 60 "0~99 Hour" 61 "0~99 Hour" 62 "0~99 Hour" 63 "0~99 Hour" 64 "0~99 Hour" 65 "0~99 Hour" 66 "0~99 Hour" 67 "0~99 Hour" 68 "0~99 Hour" 69 "0~99 Hour" 70 "0~99 Hour" 71 "0~99 Hour" 72 "0~99 Hour" 73 "0~99 Hour" 74 "0~99 Hour" 75 "0~99 Hour" 76 "0~99 Hour" 77 "0~99 Hour" 78 "0~99 Hour" 79 "0~99 Hour" 80 "0~99 Hour" 81 "0~99 Hour" 82 "0~99 Hour" 83 "0~99 Hour" 84 "0~99 Hour" 85 "0~99 Hour" 86 "0~99 Hour" 87 "0~99 Hour" 88 "0~99 Hour" 89 "0~99 Hour" 90 "0~99 Hour" 91 "0~99 Hour" 92 "0~99 Hour" 93 "0~99 Hour" 94 "0~99 Hour" 95 "0~99 Hour" 96 "0~99 Hour" 97 "0~99 Hour" 98 "0~99 Hour" 99 "0~99 Hour" 63 "Invalid" ;
VAL_ 276 HU_Disc_select_No 0 "0" 1 "Disc number 1" 2 "Disc number 2" 3 "Disc number 3" 4 "Disc number 4" 5 "Disc number 5" 6 "Disc number 6" 7 "Reserved" 8 "Reserved" 9 "Reserved" 10 "Reserved" 11 "Reserved" 12 "Reserved" 13 "Reserved" 14 "Reserved" 15 "Invalid" ;
VAL_ 276 HU_Frequency 511 "invalid" ;
VAL_ 17 AMP_Beep2VolumeStep 254 "Req.amp.Beep 1 settings" 255 "Invalid" ;
VAL_ 17 AMP_Beep2Frequency 65535 "Invalid" ;
VAL_ 17 AMP_Beep2Ch_OutputMask 65535 "Invalid" ;
VAL_ 17 AMP_Beep2DurationOn 255 "Invalid" ;
VAL_ 17 AMP_Beep2DurationOff 255 "Invalid" ;
VAL_ 17 AMP_Beep2NumberOfCycles 255 "Invalid" ;
VAL_ 15 AMP_MainVolumeSet 254 "Req.amp.VTBF step max" 255 "Invalid" ;
VAL_ 15 AMP_BalanceSet 255 "Invalid" ;
VAL_ 15 AMP_FadeSet 255 "Invalid" ;
VAL_ 15 AMP_BassSet 255 "Invalid" ;
VAL_ 15 AMP_MidSet 255 "Invalid" ;
VAL_ 15 AMP_TrebleSet 255 "Invalid" ;
VAL_ 14 AMP_HFVolumeStep 254 "Request amp supported HF Set" 255 "Invalid" ;
VAL_ 14 AMP_HFMainAudioCut 254 "Invalid" 255 "Invalid" ;
VAL_ 14 AMP_HFChannelOutputMask 0 "Channel does not output HF call" 1 "Channel outputs HF call" 65535 "Invalid" ;
VAL_ 14 AMP_HFChannelMuteMask 0 "Channel main audio not muted" 1 "Channel main audio muted" 65535 "Invalid" ;
VAL_ 13 AMP_MTSVolumeStep 254 "Request amp supported MTS Set" 255 "Invalid" ;
VAL_ 13 AMP_MTSMainAudioCut 255 "Invalid" ;
VAL_ 13 AMP_MTSChannelOutputMask 65535 "Invalid" ;
VAL_ 13 AMP_MTSChannelMuteMask 65535 "Invalid" ;
VAL_ 12 AMP_NaviVolumeStep 254 "Req. amp supported Navi Set" 255 "Invalid" ;
VAL_ 12 AMP_NaviMainAudioCut 254 "Invalid" 255 "Invalid" ;
VAL_ 12 AMP_NaviChannelOutputMask 0 "Channel Audio Not Muted" 1 "Channel Audio Muted" 65535 "Invalid" ;
VAL_ 12 AMP_NaviChannelMuteMask 0 "Channel main audio not muted" 1 "Channel main audio muted" 65535 "Invalid" ;
VAL_ 11 AMP_Drive 0 "Null" 1 "LHD" 2 "RHD" 3 "Invalid" ;
VAL_ 11 AMP_ConvertibleTop 0 "Null" 1 "UP" 2 "down" 3 "Invalid" ;
VAL_ 10 AMP_CrtVehicleID 255 "Invalid" ;
VAL_ 10 AMP_SPDIFMode 0 "Null" 1 "Two Channel Audio" 2 "Four Channel Audio" 3 "DD" 4 "DTS" 5 "Unused" 6 "Unused" 7 "Unused" 8 "Unused" 9 "Unused" 10 "Unused" 11 "Unused" 12 "Unused" 13 "Unused" 14 "Unused" 15 "Invalid" ;
VAL_ 10 AMP_VersionReq 0 "Off" 1 "Version request" 2 "Reservd" 3 "Invalid" ;
VAL_ 10 AMP_UpdateStart 0 "No update start" 1 "Update start" 2 "Unused" 3 "Invalid" ;
VAL_ 10 AMP_UpdateEnd 0 "No update end" 1 "Update end" 2 "Unused" 3 "Invalid" ;
VAL_ 9 AMP_Mute 0 "Not mute" 1 "mute" 2 "Unsed" 3 "Invalid" ;
VAL_ 9 AMP_RearSpMute 0 "Not mute" 1 "mute" 2 "Unsed" 3 "Invalid" ;
VAL_ 9 AMP_SurroundMode 0 "Surround mode off" 1 "Surround mode On" 2 "Surround mode check" 3 "Invalid" ;
VAL_ 9 AMP_VEQMode 0 "VEQ mode off" 1 "VEQ mode On" 2 "VEQ mode Check" 3 "Invalid" ;
VAL_ 9 AMP_AudioMode 0 "Off" 1 "AM" 2 "FM" 3 "Reserved" 4 "XM_SIRIUS" 5 "DMB(South Korea Only)" 6 "Reserved" 7 "Reserved" 8 "Reserved" 9 "Reserved" 10 "Reserved" 11 "Reserved" 12 "Reserved" 13 "Reserved" 14 "Reserved" 15 "Reserved" 16 "CD(CDDA_MP3)" 17 "DVD DD" 18 "DVD DTS" 19 "RSE CD_MP3_VCD" 20 "RSE DD" 21 "RSE DTS" 22 "Reserved" 23 "Reserved" 24 "Reserved" 25 "Reserved" 26 "Reserved" 27 "Reserved" 28 "Reserved" 29 "Reserved" 30 "Reserved" 31 "Reserved" 32 "USB MP3" 33 "BT MP3" 34 "iPod" 35 "AUX" 36 "RSE AUX" 37 "HF(SPDIF)" 38 "MTS(SPDIF)" 39 "MTS(analog)" 40 "ZUNE" 255 "Invalid" ;
VAL_ 9 AMP_EQ 0 "null" 1 "EQ Active" 2 "EQ loading" 3 "invalid" ;
VAL_ 9 AMP_Reset 0 "Not used" 1 "Amp_reset" 2 "Reserved" 3 "Invalid" ;
VAL_ 9 AMP_SPDIFMute 0 "SPDIF Un-mutef" 1 "SPDIF Mute On" 2 "Unused" 3 "Invalid" ;
VAL_ 9 AMP_DefaultBeep1 0 "Default beep 1 Off" 1 "Default beep1 ON" 2 "Double Beep on" 3 "Invalid" ;
VAL_ 9 AMP_DefaultBeep2 0 "default beep2 Off" 1 "Default beep2 ON" 2 "Unused" 3 "Invalid" ;
VAL_ 9 AMP_BeatsMode 0 "Beats Off" 1 "Beats On" 2 "Beats Check" 3 "Invalid" ;
VAL_ 9 AMP_VIPMode 0 "VIP OFF" 1 "VIP ON" 2 "Reserved" 3 "Invalid" ;
VAL_ 9 AMP_QLSMode 0 "QLS OFF" 1 "On Stage" 2 "Audience" 3 "Invalid" ;
VAL_ 1288 NV_TIME_TYPE 0 "Estimated Time" 1 "the necessary time" 2 "not used" 3 "not used" 4 "not used" 5 "not used" 6 "not used" 7 "not used" 8 "not used" 9 "not used" 10 "not used" 11 "not used" 12 "not used" 13 "not used" 14 "not used" 15 "invalid" ;
VAL_ 1288 NV_Hour 0 "hours" 1 "hours" 2 "hours" 3 "hours" 4 "hours" 5 "hours" 6 "hours" 7 "hours" 8 "hours" 9 "hours" 10 "hours" 11 "hours" 12 "hours" 13 "hours" 14 "hours" 15 "hours" 16 "hours" 17 "hours" 18 "hours" 19 "hours" 20 "hours" 21 "hours" 22 "hours" 23 "hours" 255 "Invalid" ;
VAL_ 1288 NV_Min 0 "minutes" 1 "minutes" 2 "minutes" 3 "minutes" 4 "minutes" 5 "minutes" 6 "minutes" 7 "minutes" 8 "minutes" 9 "minutes" 10 "minutes" 11 "minutes" 12 "minutes" 13 "minutes" 14 "minutes" 15 "minutes" 16 "minutes" 17 "minutes" 18 "minutes" 19 "minutes" 20 "minutes" 21 "minutes" 22 "minutes" 23 "minutes" 24 "minutes" 25 "minutes" 26 "minutes" 27 "minutes" 28 "minutes" 29 "minutes" 30 "minutes" 31 "minutes" 32 "minutes" 33 "minutes" 34 "minutes" 35 "minutes" 36 "minutes" 37 "minutes" 38 "minutes" 39 "minutes" 40 "minutes" 41 "minutes" 42 "minutes" 43 "minutes" 44 "minutes" 45 "minutes" 46 "minutes" 47 "minutes" 48 "minutes" 49 "minutes" 50 "minutes" 51 "minutes" 52 "minutes" 53 "minutes" 54 "minutes" 55 "minutes" 56 "minutes" 57 "minutes" 58 "minutes" 59 "minutes" 255 "Invalid" ;
VAL_ 8 AMP_HFMode 0 "Phone Off" 1 "Phone ON" 2 "Unused" 3 "Invalid" ;
VAL_ 8 AMP_NaviMode 0 "Navi Off" 1 "Navi ON" 2 "Unused" 3 "Invalid" ;
VAL_ 8 AMP_MTSMode 0 "MTS Off" 1 "MTS ON" 2 "Unused" 3 "Invalid" ;
VAL_ 8 AMP_VSCMode 0 "Speed gain mode Off" 1 "Speed gain mode On" 2 "Support of DDVC 4 Step Control" 3 "Invalid" ;
VAL_ 8 AMP_Beep1Mode 0 "Beep1 mode off" 1 "Beep1 mode On" 2 "Unsed" 3 "Invalid" ;
VAL_ 8 AMP_Beep2Mode 0 "Beep 2 mode off" 1 "Beep 2 mode On" 2 "Unsed" 3 "Invalid" ;
VAL_ 8 AMP_SDVCStep 0 "off" 1 "low" 2 "mid" 3 "high" 7 "Invalid" ;
VAL_ 8 AMP_ASDMode 0 "Not use" 1 "Off" 2 "Quite" 3 "Sport" 4 "Reserved" 5 "Reserved" 6 "Reserved" 7 "Invalid" ;
VAL_ 8 AMP_SignalDoctor 0 "Signal Doctor OFF" 1 "Signal Doctor ON" 2 "Unused" 3 "Invalid" ;
VAL_ 8 AMP_AutoVolume 0 "AutoVolume OFF" 1 "AutoVolume ON" 2 "Unused" 3 "Invalid" ;
VAL_ 1287 NV_DistToTurn_F1 0 "physical" 1 "physical" 2 "physical" 3 "physical" 4 "physical" 5 "physical" 6 "physical" 7 "physical" 8 "physical" 9 "physical" 10 "reserved" 11 "reserved" 12 "reserved" 13 "reserved" 14 "reserved" 15 "invalid" ;
VAL_ 1287 NV_DistToTurn_Unit 0 "meter" 1 "kilometer" 2 "mile" 3 "feet" 4 "reserved" 5 "reserved" 6 "reserved" 7 "reserved" 8 "reserved" 9 "reserved" 10 "reserved" 11 "reserved" 12 "reserved" 13 "reserved" 14 "reserved" 15 "invalid" ;
VAL_ 1287 NV_DistToTurn_F3 0 "physical value" 1 "physical value" 2 "physical value" 3 "physical value" 4 "physical value" 5 "physical value" 6 "physical value" 7 "physical value" 8 "physical value" 9 "physical value" 10 "Reserved" 11 "Reserved" 12 "Reserved" 13 "Reserved" 14 "Reserved" 15 "invalid" ;
VAL_ 1287 NV_DistToTurn_F2 0 "physical value" 1 "physical value" 2 "physical value" 3 "physical value" 4 "physical value" 5 "physical value" 6 "physical value" 7 "physical value" 8 "physical value" 9 "physical value" 10 "Reserved" 11 "Reserved" 12 "Reserved" 13 "Reserved" 14 "Reserved" 15 "invalid" ;
VAL_ 1287 NV_DistToTurn_I1 0 "0" 65534 "65534" 65535 "invalid" ;
VAL_ 1287 NV_DistToTurn_I2 0 "0" 65534 "65534" 65535 "invalid" ;
VAL_ 1287 NV_DistToTurn_I3 0 "0" 65534 "65534" 65535 "invalid" ;
VAL_ 1286 NV_EstDist_F 0 "physical distance" 1 "physical distance" 2 "physical distance" 3 "physical distance" 4 "physical distance" 5 "physical distance" 6 "physical distance" 7 "physical distance" 8 "physical distance" 9 "physical distance" 10 "Reserved" 11 "Reserved" 12 "Reserved" 13 "Reserved" 14 "Reserved" 15 "invalid" ;
VAL_ 1286 NV_EstDist_Unit 0 "meter" 1 "kilometer" 2 "mile" 3 "feet" 5 "Reserved" 6 "Reserved" 7 "Reserved" 8 "Reserved" 9 "Reserved" 10 "Reserved" 11 "Reserved" 12 "Reserved" 13 "Reserved" 14 "Reserved" 15 "invalid" 4 "yard" ;
VAL_ 1286 NV_EstHour 0 "hour" 23 "hour" 255 "invalid" ;
VAL_ 1286 NV_EstMin 0 "minutes" 59 "minutes" 255 "invalid" ;
VAL_ 1286 NV_Azimuth 0 "Increase value" 31 "Increase value" 255 "Invalid" ;
VAL_ 1286 NV_EstDist_I 0 "0" 65534 "65534" 65535 "invalid" ;
VAL_ 1286 NV_EstimTimeType 0 "None" 1 "Estimate Time of Arrival" 2 "Necessary Time" 3 "Invalid" ;
VAL_ 1286 NV_EstimTimeFormat 0 "None" 1 "12 hour" 2 "24 hour" 3 "Invalid" ;
VAL_ 1284 HU_VehicleSpeed 255 "Invalid" ;
VAL_ 1284 AMP_SetMaxMainVolStep 0 "35 Step" 1 "45 Steps" 2 "reserved" 3 "Invalid" ;
VAL_ 1284 AMP_LKASWarningOn 0 "Off" 1 "On" 2 "reserved" 3 "Invalid" ;
VAL_ 1284 AMP_BSDWarningOn 0 "Off" 1 "On" 2 "reserved" 3 "Invalid" ;
VAL_ 256 HU_Type 16 "AVN(Tuner DVD KOR)" 17 "AVN(Tuner DVD EUR)" 18 "AVN(Tuner DVD China)" 19 "AVN(Tuner DVD Japan)" 20 "AVN(Tuner DVD EUR)" 21 "AVN(Tuner CDP KOR)" 22 "AVN(Tuner CDP EUR)" 23 "AVN(Tuner CDP China)" 24 "AVN(Tuner CDP Japan)" 25 "AVN(Tuner CDP EUR)" 32 "AVNT (Open)" 33 "AVNT (Not open)" 48 "Economic Audio" 64 "Standard Audio (3.0 below)" 80 "AV(Tuner DVD KOR)" 81 "AV(Tuner DVD EUR)" 82 "AV(Tuner DVD China)" 83 "AV(Tuner DVD Japan)" 84 "AV(Tuner DVD EUR)" 85 "AV(Tuner CDP KOR)" 86 "AV(Tuner CDP EUR)" 87 "AV(Tuner CDP China)" 88 "AV(Tuner CDP Japan)" 89 "AV(Tuner CDP EUR)" 96 "VIT Basic AVN" 97 "VIT Premier AVN" 255 "Invalid" 98 "EU AVN 2.0" 99 "Super Premium w Navi" 100 "Super Premium w_o Navi" 101 "Premium w Navi" 102 "Premium w_o Navi" 103 "Display Audio" 65 "Standard Audio 4.0" 112 "Compact AVN" ;
VAL_ 256 HU_VerMajor 255 "(Invalid)" ;
VAL_ 256 HU_VerMinor 255 "(Invalid)" ;
VAL_ 256 HU_DistributeInfo 0 "Default (Korea)" 1 "Korea" 2 "North America" 3 "Canada" 4 "East Europe" 5 "West Europe" 6 "China" 7 "India" 8 "Australia" 9 "Middle East" 10 "Africa" 11 "South America" 12 "Reserved" 13 "Reserved" 14 "General" 255 "Invalid" ;
VAL_ 256 HU_SubVerMajor 255 "(Invalid)" ;
VAL_ 256 HU_SubVerMinor 255 "(Invalid)" ;
VAL_ 256 HU_SDARSVersion 255 "(Invalid)" ;
VAL_ 256 HU_AdasSupport 0 "Not Support" 1 "ADAS Support(General Map)" 2 "ADAS Support(Precise Map)" 3 "Reserved" 4 "Reserved" 5 "Reserved" 6 "Reserved" 7 "Invalid" ;
VAL_ 1092 NMSleepFlag_CLOCK 0 "Alive" 1 "SleepInd" 3 "SleepAck" ;
VAL_ 1092 NMCommandCode_CLOCK 1 "Alive" 2 "Ring" 4 "Limphome" ;
VAL_ 1108 NMSleepFlag_HUD 0 "Alive" 1 "SleepInd" 3 "SleepAck" ;
VAL_ 1108 NMCommandCode_HUD 1 "Alive" 2 "Ring" 4 "Limphome" ;
VAL_ 1088 NMSleepFlag_H_U 0 "Alive" 1 "SleepInd" 3 "SleepAck" ;
VAL_ 1088 NMCommandCode_H_U 1 "Alive" 2 "Ring" 4 "Limphome" ;
VAL_ 1091 NMSleepFlag_DATC 0 "Alive" 1 "SleepInd" 3 "SleepAck" ;
VAL_ 1091 NMCommandCode_DATC 1 "Alive" 2 "Ring" 4 "Limphome" ;
VAL_ 1105 NMSleepFlag_CCP 0 "Alive" 1 "SleepInd" 3 "SleepAck" ;
VAL_ 1105 NMCommandCode_CCP 1 "Alive" 2 "Ring" 4 "Limphome" ;
VAL_ 1100 NMSleepFlag_KMA_TMU 0 "Alive" 1 "SleepInd" 3 "SleepAck" ;
VAL_ 1100 NMCommandCode_KMA_TMU 1 "Alive" 2 "Ring" 4 "Limphome" ;
VAL_ 1098 NMSleepFlag_CUBIS 0 "Alive" 1 "SleepInd" 3 "SleepAck" ;
VAL_ 1098 NMCommandCode_CUBIS 1 "Alive" 2 "Ring" 4 "Limphome" ;
VAL_ 1099 NMSleepFlag_TMU 0 "Alive" 1 "SleepInd" 3 "SleepAck" ;
VAL_ 1099 NMCommandCode_TMU 1 "Alive" 2 "Ring" 4 "Limphome" ;
VAL_ 1095 NMSleepFlag_IPM 0 "Alive" 1 "SleepInd" 3 "SleepAck" ;
VAL_ 1095 NMCommandCode_IPM 1 "Alive" 2 "Ring" 4 "Limphome" ;
VAL_ 1107 NMSleepFlag_RSE_R 0 "Alive" 1 "SleepInd" 3 "SleepAck" ;
VAL_ 1107 NMCommandCode_RSE_R 1 "Alive" 2 "Ring" 4 "Limphome" ;
VAL_ 1093 NMSleepFlag_RRC 0 "Alive" 1 "SleepInd" 3 "SleepAck" ;
VAL_ 1093 NMCommandCode_RRC 1 "Alive" 2 "Ring" 4 "Limphome" ;
VAL_ 1109 NMSleepFlag_CGW 0 "Alive" 1 "SleepInd" 3 "SleepAck" ;
VAL_ 1109 NMCommandCode_CGW 1 "Alive" 2 "Ring" 4 "Limphome" ;
VAL_ 1106 NMSleepFlag_RSE_L 0 "Alive" 1 "SleepInd" 3 "SleepAck" ;
VAL_ 1106 NMCommandCode_RSE_L 1 "Alive" 2 "Ring" 4 "Limphome" ;
VAL_ 1096 NMSleepFlag_AMP 0 "Alive" 1 "SleepInd" 3 "SleepAck" ;
VAL_ 1096 NMCommandCode_AMP 1 "Alive" 2 "Ring" 4 "Limphome" ;
VAL_ 1103 NMSleepFlag_EDT 0 "Alive" 1 "SleepInd" 3 "SleepAck" ;
VAL_ 1103 NMCommandCode_EDT 1 "Alive" 2 "Ring" 4 "Limphome" ;
VAL_ 1110 NMSleepFlag_SWRC 0 "Alive" 1 "SleepInd" 3 "SleepAck" ;
VAL_ 1110 NMCommandCode_SWRC 1 "Alive" 2 "Ring" 4 "Limphome" ;
VAL_ 1102 NMSleepFlag_IBOX 0 "Alive" 1 "SleepInd" 3 "SleepAck" ;
VAL_ 1102 NMCommandCode_IBOX 1 "Alive" 2 "Ring" 4 "Limphome" ;
VAL_ 1101 NMSleepFlag_CLU 0 "Alive" 1 "SleepInd" 3 "SleepAck" ;
VAL_ 1101 NMCommandCode_CLU 1 "Alive" 2 "Ring" 4 "Limphome" ;
VAL_ 1097 NMSleepFlag_FHCU 0 "Alive" 1 "SleepInd" 3 "SleepAck" ;
VAL_ 1097 NMCommandCode_FHCU 1 "Alive" 2 "Ring" 4 "Limphome" ;
VAL_ 1094 NMSleepFlag_ASD 0 "Alive" 1 "SleepInd" 3 "SleepAck" ;
VAL_ 1094 NMCommandCode_ASD 1 "Alive" 2 "Ring" 4 "Limphome" ;
VAL_ 1089 NMSleepFlag_MON 0 "Alive" 1 "SleepInd" 3 "SleepAck" ;
VAL_ 1089 NMCommandCode_MON 1 "Alive" 2 "Ring" 4 "Limphome" ;
VAL_ 1104 NMSleepFlag_AVM 0 "Alive" 1 "SleepInd" 3 "SleepAck" ;
VAL_ 1104 NMCommandCode_AVM 1 "Alive" 2 "Ring" 4 "Limphome" ;
VAL_ 1090 NMSleepFlag_KBD 0 "Alive" 1 "SleepInd" 3 "SleepAck" ;
VAL_ 1090 NMCommandCode_KBD 1 "Alive" 2 "Ring" 4 "Limphome" ;
